[part 1 of 10: packages /Cluster to /E40_Platform_System_SystemPackage/Components]
AUTOSAR XML (schema 4-2-1)
standard types defined: uint8, uint16, UInt16, uint32, UInt32, sint32, boolean, Boolean, SInt32, UInt8, sint8, SInt8, sint16, SInt16
package /Cluster
  can cluster HS3_CAN: baudrate=500000, protocol-name=CAN  # Y2021_FNV2_CMDB_v21.01_HS3_ISOUpdated | FNV2 HS3 CAN
    can physical channel CHNL: comm-connectors=CN_CAN00
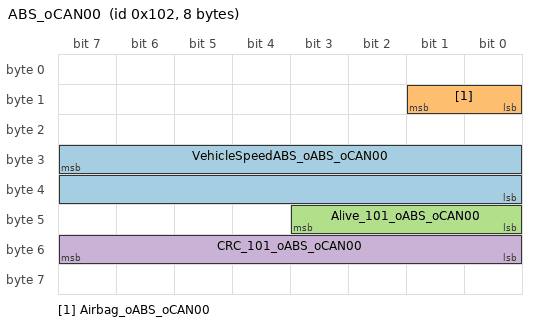
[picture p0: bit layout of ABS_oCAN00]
      frame ABS_oCAN00: id 0x102, to IC, frame-length=8, can-addressing-mode=STANDARD
        pdu ABS_oCAN00: length=8, minimum-delay=0.02, unused-bit-pattern=0
          signal VehicleSpeedABS_oABS_oCAN00: start 31, 16 bit, big-endian, init-value=0, base-type=uint16, compu-method=CM_VehicleSpeedABS, unit=U_SED, transfer-property=PENDING, to IC
          signal Airbag_oABS_oCAN00: start 9, 2 bit, big-endian, init-value=0, base-type=uint8, compu-method=CM_Airbag, unit=U_SED, transfer-property=PENDING, to IC
          signal Alive_101_oABS_oCAN00: start 43, 4 bit, big-endian, init-value=0, base-type=uint8, compu-method=CM_Alive_101, unit=U_SED, transfer-property=PENDING, to IC
          signal CRC_101_oABS_oCAN00: start 55, 8 bit, big-endian, init-value=0, base-type=uint8, compu-method=CM_CRC_101, unit=U_SED, transfer-property=PENDING, to IC
      frame Cluster_Secure_Tx_oCAN00: id 0x300, from IC, frame-length=8, can-addressing-mode=STANDARD
        pdu Cluster_Secure_Tx_oCAN00: length=8, minimum-delay=0.02, unused-bit-pattern=0
          signal SecureTxByte0_oCluster_Secure_Tx_oCAN00: start 0, 8 bit, big-endian, init-value=0, base-type=uint8, compu-method=CM_SecureTxByte0, unit=U_SED, transfer-property=PENDING
          signal SecureTxByte1_oCluster_Secure_Tx_oCAN00: start 8, 8 bit, big-endian, init-value=0, base-type=uint8, compu-method=CM_SecureTxByte1, unit=U_SED, transfer-property=PENDING
          signal SecureTxByte2_oCluster_Secure_Tx_oCAN00: start 16, 8 bit, big-endian, init-value=0, base-type=uint8, compu-method=CM_SecureTxByte2, unit=U_SED, transfer-property=PENDING
          signal SecureTxByte3_oCluster_Secure_Tx_oCAN00: start 24, 8 bit, big-endian, init-value=0, base-type=uint8, compu-method=CM_SecureTxByte3, unit=U_SED, transfer-property=PENDING
          signal MAC_Tx_oCluster_Secure_Tx_oCAN00: start 32, 28 bit, big-endian, init-value=0, base-type=uint32, compu-method=CM_MAC_Tx, unit=U_SED, transfer-property=PENDING
          signal FV_Tx_oCluster_Secure_Tx_oCAN00: start 60, 4 bit, big-endian, init-value=0, base-type=uint8, compu-method=CM_FV_Tx, unit=U_SED, transfer-property=PENDING
      frame Cluster_Tx_Normal_COM_HS_oCAN00: id 0x200, from IC, frame-length=8, can-addressing-mode=STANDARD
        pdu Cluster_Tx_Normal_COM_HS_oCAN00: length=8, minimum-delay=0.02, unused-bit-pattern=0
          signal Battery_Voltage_oCluster_Tx_Normal_COM_HS_oCAN00: start 0, 8 bit, big-endian, init-value=0, base-type=uint8, compu-method=CM_Battery_Voltage, unit=U_SED, transfer-property=PENDING
      frame Cluster_Tx_Normal_COM_LS_oCAN00: id 0x202, from IC, frame-length=8, can-addressing-mode=STANDARD
        pdu Cluster_Tx_Normal_COM_LS_oCAN00: length=8, minimum-delay=0.02, unused-bit-pattern=0
          signal Odometer_oCluster_Tx_Normal_COM_LS_oCAN00: start 0, 32 bit, big-endian, init-value=0, base-type=uint32, compu-method=CM_Odometer, unit=U_SED, transfer-property=PENDING
      frame Cluster_Tx_Normal_COM_MS_oCAN00: id 0x201, from IC, frame-length=8, can-addressing-mode=STANDARD
        pdu Cluster_Tx_Normal_COM_MS_oCAN00: length=8, minimum-delay=0.02, unused-bit-pattern=0
          signal VehicleSpeedIC_oCluster_Tx_Normal_COM_MS_oCAN00: start 0, 16 bit, big-endian, init-value=0, base-type=uint16, compu-method=CM_VehicleSpeedIC, unit=U_SED, transfer-property=PENDING
      frame Cluster_Tx_Reduced_Com_oCAN00: id 0x210, from IC, frame-length=8, can-addressing-mode=STANDARD
        pdu Cluster_Tx_Reduced_Com_oCAN00: length=8, minimum-delay=0.02, unused-bit-pattern=0
          signal Illumination_PWM_oCluster_Tx_Reduced_Com_oCAN00: start 0, 8 bit, big-endian, init-value=0, base-type=uint8, compu-method=CM_Illumination_PWM, unit=U_SED, transfer-property=PENDING
      frame Debug_Frame1_oCAN00: id 0x550, from IC, frame-length=8, can-addressing-mode=STANDARD
        pdu Debug_Frame1_oCAN00: length=8, minimum-delay=0.02, unused-bit-pattern=0
          signal Debug1_Byte0_oDebug_Frame1_oCAN00: start 0, 8 bit, big-endian, init-value=0, base-type=uint8, compu-method=CM_Debug1_Byte0, unit=U_SED, transfer-property=PENDING
          signal Debug1_Byte1_oDebug_Frame1_oCAN00: start 8, 8 bit, big-endian, init-value=0, base-type=uint8, compu-method=CM_Debug1_Byte1, unit=U_SED, transfer-property=PENDING
          signal Debug1_Byte2_oDebug_Frame1_oCAN00: start 16, 8 bit, big-endian, init-value=0, base-type=uint8, compu-method=CM_Debug1_Byte2, unit=U_SED, transfer-property=PENDING
          signal Debug1_Byte3_oDebug_Frame1_oCAN00: start 24, 8 bit, big-endian, init-value=0, base-type=uint8, compu-method=CM_Debug1_Byte3, unit=U_SED, transfer-property=PENDING
          signal Debug1_Byte4_oDebug_Frame1_oCAN00: start 32, 8 bit, big-endian, init-value=0, base-type=uint8, compu-method=CM_Debug1_Byte4, unit=U_SED, transfer-property=PENDING
          signal Debug1_Byte5_oDebug_Frame1_oCAN00: start 40, 8 bit, big-endian, init-value=0, base-type=uint8, compu-method=CM_Debug1_Byte5, unit=U_SED, transfer-property=PENDING
          signal Debug1_Byte6_oDebug_Frame1_oCAN00: start 48, 8 bit, big-endian, init-value=0, base-type=uint8, compu-method=CM_Debug1_Byte6, unit=U_SED, transfer-property=PENDING
          signal Debug1_Byte7_oDebug_Frame1_oCAN00: start 56, 8 bit, big-endian, init-value=0, base-type=uint8, compu-method=CM_Debug1_Byte7, unit=U_SED, transfer-property=PENDING
      frame Debug_Frame2_oCAN00: id 0x551, from IC, frame-length=8, can-addressing-mode=STANDARD
        pdu Debug_Frame2_oCAN00: length=8, minimum-delay=0.02, unused-bit-pattern=0
          signal Debug2_Byte0_oDebug_Frame2_oCAN00: start 0, 8 bit, big-endian, init-value=0, base-type=uint8, compu-method=CM_Debug2_Byte0, unit=U_SED, transfer-property=PENDING
          signal Debug2_Byte1_oDebug_Frame2_oCAN00: start 8, 8 bit, big-endian, init-value=0, base-type=uint8, compu-method=CM_Debug2_Byte1, unit=U_SED, transfer-property=PENDING
          signal Debug2_Byte2_oDebug_Frame2_oCAN00: start 16, 8 bit, big-endian, init-value=0, base-type=uint8, compu-method=CM_Debug2_Byte2, unit=U_SED, transfer-property=PENDING
          signal Debug2_Byte3_oDebug_Frame2_oCAN00: start 24, 8 bit, big-endian, init-value=0, base-type=uint8, compu-method=CM_Debug2_Byte3, unit=U_SED, transfer-property=PENDING
          signal Debug2_Byte4_oDebug_Frame2_oCAN00: start 32, 8 bit, big-endian, init-value=0, base-type=uint8, compu-method=CM_Debug2_Byte4, unit=U_SED, transfer-property=PENDING
          signal Debug2_Byte5_oDebug_Frame2_oCAN00: start 40, 8 bit, big-endian, init-value=0, base-type=uint8, compu-method=CM_Debug2_Byte5, unit=U_SED, transfer-property=PENDING
          signal Debug2_Byte6_oDebug_Frame2_oCAN00: start 48, 8 bit, big-endian, init-value=0, base-type=uint8, compu-method=CM_Debug2_Byte6, unit=U_SED, transfer-property=PENDING
          signal Debug2_Byte7_oDebug_Frame2_oCAN00: start 56, 8 bit, big-endian, init-value=0, base-type=uint8, compu-method=CM_Debug2_Byte7, unit=U_SED, transfer-property=PENDING
      frame Debug_Frame3_oCAN00: id 0x552, from IC, frame-length=8, can-addressing-mode=STANDARD
        pdu Debug_Frame3_oCAN00: length=8, minimum-delay=0.02, unused-bit-pattern=0
          signal Debug3_Byte0_oDebug_Frame3_oCAN00: start 0, 8 bit, big-endian, init-value=0, base-type=uint8, compu-method=CM_Debug3_Byte0, unit=U_SED, transfer-property=PENDING
          signal Debug3_Byte1_oDebug_Frame3_oCAN00: start 8, 8 bit, big-endian, init-value=0, base-type=uint8, compu-method=CM_Debug3_Byte1, unit=U_SED, transfer-property=PENDING
          signal Debug3_Byte2_oDebug_Frame3_oCAN00: start 16, 8 bit, big-endian, init-value=0, base-type=uint8, compu-method=CM_Debug3_Byte2, unit=U_SED, transfer-property=PENDING
          signal Debug3_Byte3_oDebug_Frame3_oCAN00: start 24, 8 bit, big-endian, init-value=0, base-type=uint8, compu-method=CM_Debug3_Byte3, unit=U_SED, transfer-property=PENDING
          signal Debug3_Byte4_oDebug_Frame3_oCAN00: start 32, 8 bit, big-endian, init-value=0, base-type=uint8, compu-method=CM_Debug3_Byte4, unit=U_SED, transfer-property=PENDING
          signal Debug3_Byte5_oDebug_Frame3_oCAN00: start 40, 8 bit, big-endian, init-value=0, base-type=uint8, compu-method=CM_Debug3_Byte5, unit=U_SED, transfer-property=PENDING
          signal Debug3_Byte6_oDebug_Frame3_oCAN00: start 48, 8 bit, big-endian, init-value=0, base-type=uint8, compu-method=CM_Debug3_Byte6, unit=U_SED, transfer-property=PENDING
          signal Debug3_Byte7_oDebug_Frame3_oCAN00: start 56, 8 bit, big-endian, init-value=0, base-type=uint8, compu-method=CM_Debug3_Byte7, unit=U_SED, transfer-property=PENDING
      frame Debug_Frame4_oCAN00: id 0x553, from IC, frame-length=8, can-addressing-mode=STANDARD
        pdu Debug_Frame4_oCAN00: length=8, minimum-delay=0.02, unused-bit-pattern=0
          signal Debug4_Byte0_oDebug_Frame4_oCAN00: start 0, 8 bit, big-endian, init-value=0, base-type=uint8, compu-method=CM_Debug4_Byte0, unit=U_SED, transfer-property=PENDING
          signal Debug4_Byte1_oDebug_Frame4_oCAN00: start 8, 8 bit, big-endian, init-value=0, base-type=uint8, compu-method=CM_Debug4_Byte1, unit=U_SED, transfer-property=PENDING
          signal Debug4_Byte2_oDebug_Frame4_oCAN00: start 16, 8 bit, big-endian, init-value=0, base-type=uint8, compu-method=CM_Debug4_Byte2, unit=U_SED, transfer-property=PENDING
          signal Debug4_Byte3_oDebug_Frame4_oCAN00: start 24, 8 bit, big-endian, init-value=0, base-type=uint8, compu-method=CM_Debug4_Byte3, unit=U_SED, transfer-property=PENDING
          signal Debug4_Byte4_oDebug_Frame4_oCAN00: start 32, 8 bit, big-endian, init-value=0, base-type=uint8, compu-method=CM_Debug4_Byte4, unit=U_SED, transfer-property=PENDING
          signal Debug4_Byte5_oDebug_Frame4_oCAN00: start 40, 8 bit, big-endian, init-value=0, base-type=uint8, compu-method=CM_Debug4_Byte5, unit=U_SED, transfer-property=PENDING
          signal Debug4_Byte6_oDebug_Frame4_oCAN00: start 48, 8 bit, big-endian, init-value=0, base-type=uint8, compu-method=CM_Debug4_Byte6, unit=U_SED, transfer-property=PENDING
          signal Debug4_Byte7_oDebug_Frame4_oCAN00: start 56, 8 bit, big-endian, init-value=0, base-type=uint8, compu-method=CM_Debug4_Byte7, unit=U_SED, transfer-property=PENDING
      frame Debug_Frame5_oCAN00: id 0x554, from IC, frame-length=8, can-addressing-mode=STANDARD
        pdu Debug_Frame5_oCAN00: length=8, minimum-delay=0.02, unused-bit-pattern=0
          signal Debug5_Byte0_oDebug_Frame5_oCAN00: start 0, 8 bit, big-endian, init-value=0, base-type=uint8, compu-method=CM_Debug5_Byte0, unit=U_SED, transfer-property=PENDING
          signal Debug5_Byte1_oDebug_Frame5_oCAN00: start 8, 8 bit, big-endian, init-value=0, base-type=uint8, compu-method=CM_Debug5_Byte1, unit=U_SED, transfer-property=PENDING
          signal Debug5_Byte2_oDebug_Frame5_oCAN00: start 16, 8 bit, big-endian, init-value=0, base-type=uint8, compu-method=CM_Debug5_Byte2, unit=U_SED, transfer-property=PENDING
          signal Debug5_Byte3_oDebug_Frame5_oCAN00: start 24, 8 bit, big-endian, init-value=0, base-type=uint8, compu-method=CM_Debug5_Byte3, unit=U_SED, transfer-property=PENDING
          signal Debug5_Byte4_oDebug_Frame5_oCAN00: start 32, 8 bit, big-endian, init-value=0, base-type=uint8, compu-method=CM_Debug5_Byte4, unit=U_SED, transfer-property=PENDING
          signal Debug5_Byte5_oDebug_Frame5_oCAN00: start 40, 8 bit, big-endian, init-value=0, base-type=uint8, compu-method=CM_Debug5_Byte5, unit=U_SED, transfer-property=PENDING
          signal Debug5_Byte6_oDebug_Frame5_oCAN00: start 48, 8 bit, big-endian, init-value=0, base-type=uint8, compu-method=CM_Debug5_Byte6, unit=U_SED, transfer-property=PENDING
          signal Debug5_Byte7_oDebug_Frame5_oCAN00: start 56, 8 bit, big-endian, init-value=0, base-type=uint8, compu-method=CM_Debug5_Byte7, unit=U_SED, transfer-property=PENDING
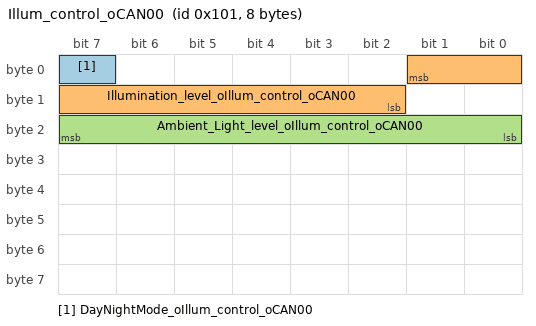
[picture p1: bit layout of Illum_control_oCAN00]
      frame Illum_control_oCAN00: id 0x101, to IC, frame-length=8, can-addressing-mode=STANDARD
        pdu Illum_control_oCAN00: length=8, minimum-delay=0.02, unused-bit-pattern=0
          signal DayNightMode_oIllum_control_oCAN00: start 7, 1 bit, big-endian, init-value=0, base-type=boolean, compu-method=CM_DayNightMode, unit=U_SED, transfer-property=PENDING, to IC
          signal Illumination_level_oIllum_control_oCAN00: start 1, 8 bit, big-endian, init-value=0, base-type=uint8, compu-method=CM_Illumination_level, unit=U_SED, transfer-property=PENDING, to IC
          signal Ambient_Light_level_oIllum_control_oCAN00: start 23, 8 bit, big-endian, init-value=0, base-type=uint8, compu-method=CM_Ambient_Light_level, unit=U_SED, transfer-property=PENDING, to IC
      frame VehicleControl_oCAN00: id 0x100, to IC, frame-length=8, can-addressing-mode=STANDARD
        pdu VehicleControl_oCAN00: length=8, minimum-delay=0.02, unused-bit-pattern=0
          signal PowerMode_oVehicleControl_oCAN00: start 0, 4 bit, big-endian, init-value=0, base-type=uint8, compu-method=CM_PowerMode, unit=U_SED, transfer-property=PENDING, to IC
          signal TransportMode_oVehicleControl_oCAN00: start 54, 1 bit, big-endian, init-value=0, base-type=boolean, compu-method=CM_TransportMode, unit=U_SED, transfer-property=PENDING, to IC
          signal GearMode_oVehicleControl_oCAN00: start 51, 1 bit, big-endian, init-value=0, base-type=boolean, compu-method=CM_GearMode, unit=U_SED, transfer-property=PENDING, to IC
          signal GearRecommendation_oVehicleControl_oCAN00: start 50, 3 bit, big-endian, init-value=0, base-type=uint8, compu-method=CM_GearRecommendation, unit=U_SED, transfer-property=PENDING, to IC
          signal Gear_oVehicleControl_oCAN00: start 7, 4 bit, big-endian, init-value=0, base-type=uint8, compu-method=CM_Gear, unit=U_SED, transfer-property=PENDING, to IC
          signal Warning_oVehicleControl_oCAN00: start 63, 8 bit, big-endian, init-value=0, base-type=uint8, compu-method=CM_Warning, unit=U_SED, transfer-property=PENDING, to IC
          signal GearStatus_oVehicleControl_oCAN00: start 15, 8 bit, big-endian, init-value=0, base-type=uint8, compu-method=CM_GearStatus, unit=U_SED, transfer-property=PENDING, to IC
          signal EngineSpeed_oVehicleControl_oCAN00: start 39, 16 bit, big-endian, init-value=0, base-type=uint16, compu-method=CM_EngineSpeed, unit=U_SED, transfer-property=PENDING, to IC
package /ECU
  ecu instance IC: associated-com-i-pdu-group=[IC_oCAN00_Rx, IC_oCAN00_Tx]  # Instrument Panel Cluster Control Module, IC (Instrument Cluster)
    can communication controller CT_CAN00
    can communication connector CN_CAN00: comm-controller=CT_CAN00
package /IPDUGroup
  i signal i pdu group IC_oCAN00_Rx: communication-direction=IN, i-signal-i-pdus=[ABS_oCAN00, Illum_control_oCAN00, VehicleControl_oCAN00]
  i signal i pdu group IC_oCAN00_Tx: communication-direction=OUT
    i-signal-i-pdus:
      Cluster_Secure_Tx_oCAN00
      Cluster_Tx_Normal_COM_HS_oCAN00
      Cluster_Tx_Normal_COM_LS_oCAN00
      Cluster_Tx_Normal_COM_MS_oCAN00
      Cluster_Tx_Reduced_Com_oCAN00
      Debug_Frame{1..5}_oCAN00
package /E40_Platform_System_SystemPackage
  composition sw component type E40_Platform_System_SoftwareArchitecture
    component E40_Platform_SystemCmp: type=E40_Platform_System
  system E40_Platform_System_System
    system mapping MAPPING
      data-mappings:
        data-element=CComAbsMdl.SoftwareArchitecture.pp_SR_TxSecureTxByte{0..3}.SecureTxByte{0..3}, system-signal=SecureTxByte{0..3}
        data-element=CComAbsMdl.SoftwareArchitecture.pp_SR_TxMAC_Tx.MAC_Tx, system-signal=MAC_Tx
        data-element=CComAbsMdl.SoftwareArchitecture.pp_SR_TxFV_Tx.FV_Tx, system-signal=FV_Tx
        data-element=CComAbsMdl.SoftwareArchitecture.pp_SR_TxBattery_Voltage.Battery_Voltage, system-signal=Battery_Voltage
        data-element=CComAbsMdl.SoftwareArchitecture.pp_SR_TxOdometer.Odometer, system-signal=Odometer
        data-element=CComAbsMdl.SoftwareArchitecture.pp_SR_TxVehicleSpeedIC.VehicleSpeedIC, system-signal=VehicleSpeedIC
        data-element=CComAbsMdl.SoftwareArchitecture.pp_SR_TxIllumination_PWM.Illumination_PWM, system-signal=Illumination_PWM
        data-element=CComAbsMdl.SoftwareArchitecture.pp_SR_TxDebug1_Byte{0..7}.Debug1_Byte{0..7}, system-signal=Debug1_Byte{0..7}
        data-element=CComAbsMdl.SoftwareArchitecture.pp_SR_TxDebug2_Byte{0..7}.Debug2_Byte{0..7}, system-signal=Debug2_Byte{0..7}
        data-element=CComAbsMdl.SoftwareArchitecture.pp_SR_TxDebug3_Byte{0..7}.Debug3_Byte{0..7}, system-signal=Debug3_Byte{0..7}
        data-element=CComAbsMdl.SoftwareArchitecture.pp_SR_TxDebug4_Byte{0..7}.Debug4_Byte{0..7}, system-signal=Debug4_Byte{0..7}
        data-element=CComAbsMdl.SoftwareArchitecture.pp_SR_TxDebug5_Byte{0..7}.Debug5_Byte{0..7}, system-signal=Debug5_Byte{0..7}
        data-element=CComAbsMdl.SoftwareArchitecture.rp_SR_RxDayNightMode.DayNightMode, system-signal=DayNightMode
        data-element=CComAbsMdl.SoftwareArchitecture.rp_SR_RxIllumination_level.Illumination_level, system-signal=Illumination_level
        data-element=CComAbsMdl.SoftwareArchitecture.rp_SR_RxAmbient_Light_level.Ambient_Light_level, system-signal=Ambient_Light_level
        data-element=CComAbsMdl.SoftwareArchitecture.rp_SR_RxPowerMode.PowerMode, system-signal=PowerMode
        data-element=CComAbsMdl.SoftwareArchitecture.rp_SR_RxTransportMode.TransportMode, system-signal=TransportMode
        data-element=CComAbsMdl.SoftwareArchitecture.rp_SR_RxGearMode.GearMode, system-signal=GearMode
        data-element=CComAbsMdl.SoftwareArchitecture.rp_SR_RxGearRecommendation.GearRecommendation, system-signal=GearRecommendation
        data-element=CComAbsMdl.SoftwareArchitecture.rp_SR_RxGear.Gear, system-signal=Gear
        data-element=CComAbsMdl.SoftwareArchitecture.rp_SR_RxWarning.Warning, system-signal=Warning
        data-element=CComAbsMdl.SoftwareArchitecture.rp_SR_RxGearStatus.GearStatus, system-signal=GearStatus
        data-element=CComAbsMdl.SoftwareArchitecture.rp_SR_RxEngineSpeed.EngineSpeed, system-signal=EngineSpeed
        data-element=CComAbsMdl.SoftwareArchitecture.rp_SR_RxVehicleSpeedABS.VehicleSpeedABS, system-signal=VehicleSpeedABS
        data-element=CComAbsMdl.SoftwareArchitecture.rp_SR_RxAirbag.Airbag, system-signal=Airbag
        data-element=CComAbsMdl.SoftwareArchitecture.rp_SR_RxAlive_101.Alive_101, system-signal=Alive_101
        data-element=CComAbsMdl.SoftwareArchitecture.rp_SR_RxCRC_101.CRC_101, system-signal=CRC_101
      sw-impl-mappings:
        58 x swc to impl mapping:
          ImplementationMapping1: component-implementation=IMPL_CBacklightCdd, component=SoftwareArchitecture.E40_Platform_SystemCmp.CBacklightCdd
          ImplementationMapping2: component-implementation=IMPL_IoHwAb, component=SoftwareArchitecture.E40_Platform_SystemCmp.IoHwAb
          ImplementationMapping3: component-implementation=IMPL_CBattMdl, component=SoftwareArchitecture.E40_Platform_SystemCmp.CBattMdl
          ImplementationMapping4: component-implementation=IMPL_CCDD_EcuPowerM, component=SoftwareArchitecture.E40_Platform_SystemCmp.CCDD_EcuPowerM
          ImplementationMapping5: component-implementation=IMPL_CComAbsCtrl, component=SoftwareArchitecture.E40_Platform_SystemCmp.CComAbsCtrl
          ImplementationMapping6: component-implementation=IMPL_ComMExt, component=SoftwareArchitecture.E40_Platform_SystemCmp.ComMExt
          ImplementationMapping7: component-implementation=IMPL_CComAbsMdl, component=SoftwareArchitecture.E40_Platform_SystemCmp.CComAbsMdl
          ImplementationMapping8: component-implementation=IMPL_CCtrl_Telltale, component=SoftwareArchitecture.E40_Platform_SystemCmp.CCtrl_Telltale
          ImplementationMapping9: component-implementation=IMPL_Ctrl_WSS, component=SoftwareArchitecture.E40_Platform_SystemCmp.Ctrl_WSS
          ImplementationMapping10: component-implementation=IMPL_NvMExt, component=SoftwareArchitecture.E40_Platform_SystemCmp.NvMExt
          ImplementationMapping11: component-implementation=IMPL_TmExt, component=SoftwareArchitecture.E40_Platform_SystemCmp.TmExt
          ImplementationMapping12: component-implementation=IMPL_Mdl_Dim, component=SoftwareArchitecture.E40_Platform_SystemCmp.Mdl_Dim
          ImplementationMapping13: component-implementation=IMPL_Ctrl_Dim, component=SoftwareArchitecture.E40_Platform_SystemCmp.Ctrl_Dim
          ImplementationMapping14: component-implementation=IMPL_MemAbstractMdl, component=SoftwareArchitecture.E40_Platform_SystemCmp.MemAbstractMdl
          ImplementationMapping15: component-implementation=IMPL_Ctrl_warning, component=SoftwareArchitecture.E40_Platform_SystemCmp.Ctrl_warning
          ImplementationMapping16: component-implementation=IMPL_CWarnMsg_Core_Observer, component=SoftwareArchitecture.E40_Platform_SystemCmp.CWarnMsg_Core_Observer
          ImplementationMapping17: component-implementation=IMPL_UclProxyCdd, component=SoftwareArchitecture.E40_Platform_SystemCmp.UclProxyCdd
          ImplementationMapping18: component-implementation=IMPL_DmnMgr, component=SoftwareArchitecture.E40_Platform_SystemCmp.DmnMgr
          ImplementationMapping19: component-implementation=IMPL_CSleepManager, component=SoftwareArchitecture.E40_Platform_SystemCmp.CSleepManager
          ImplementationMapping20: component-implementation=IMPL_Mdl_Gear, component=SoftwareArchitecture.E40_Platform_SystemCmp.Mdl_Gear
          ImplementationMapping21: component-implementation=IMPL_CView_Telltale, component=SoftwareArchitecture.E40_Platform_SystemCmp.CView_Telltale
          ImplementationMapping22: component-implementation=IMPL_Mdl_Airbag, component=SoftwareArchitecture.E40_Platform_SystemCmp.Mdl_Airbag
          ImplementationMapping23: component-implementation=IMPL_Mdl_SafetyAdapter, component=SoftwareArchitecture.E40_Platform_SystemCmp.Mdl_SafetyAdapter
          ImplementationMapping24: component-implementation=IMPL_Mdl_TurnHazard, component=SoftwareArchitecture.E40_Platform_SystemCmp.Mdl_TurnHazard
          ImplementationMapping25: component-implementation=IMPL_FastGaugeAdapter, component=SoftwareArchitecture.E40_Platform_SystemCmp.FastGaugeAdapter
          ImplementationMapping26: component-implementation=IMPL_View_Speed, component=SoftwareArchitecture.E40_Platform_SystemCmp.View_Speed
          ImplementationMapping27: component-implementation=IMPL_Mdl_Speed, component=SoftwareArchitecture.E40_Platform_SystemCmp.Mdl_Speed
          ImplementationMapping28: component-implementation=IMPL_Mdl_Linear_Interpolation, component=SoftwareArchitecture.E40_Platform_SystemCmp.Mdl_Linear_Interpolation
          ImplementationMapping29: component-implementation=IMPL_Mdl_Tacho, component=SoftwareArchitecture.E40_Platform_SystemCmp.Mdl_Tacho
          ImplementationMapping30: component-implementation=IMPL_SlowGaugeAdapter, component=SoftwareArchitecture.E40_Platform_SystemCmp.SlowGaugeAdapter
          ImplementationMapping31: component-implementation=IMPL_CUpdateCdd, component=SoftwareArchitecture.E40_Platform_SystemCmp.CUpdateCdd
          ImplementationMapping32: component-implementation=IMPL_Mdl_wAirbag, component=SoftwareArchitecture.E40_Platform_SystemCmp.Mdl_wAirbag
          ImplementationMapping33: component-implementation=IMPL_Mdl_wFuelLidOpen, component=SoftwareArchitecture.E40_Platform_SystemCmp.Mdl_wFuelLidOpen
          ImplementationMapping34: component-implementation=IMPL_WarnMsg_Core_TmrSupport, component=SoftwareArchitecture.E40_Platform_SystemCmp.WarnMsg_Core_TmrSupport
          ImplementationMapping35: component-implementation=IMPL_DcmApp, component=SoftwareArchitecture.E40_Platform_SystemCmp.DcmApp
          ImplementationMapping36: component-implementation=IMPL_DemApp, component=SoftwareArchitecture.E40_Platform_SystemCmp.DemApp
          ImplementationMapping37: component-implementation=IMPL_DemExt, component=SoftwareArchitecture.E40_Platform_SystemCmp.DemExt
          ImplementationMapping38: component-implementation=IMPL_CDisplayCdd, component=SoftwareArchitecture.E40_Platform_SystemCmp.CDisplayCdd
          ImplementationMapping39: component-implementation=IMPL_CFltM, component=SoftwareArchitecture.E40_Platform_SystemCmp.CFltM
          ImplementationMapping40: component-implementation=IMPL_RstM, component=SoftwareArchitecture.E40_Platform_SystemCmp.RstM
          ImplementationMapping41: component-implementation=IMPL_Dlt, component=SoftwareArchitecture.E40_Platform_SystemCmp.Dlt
          ImplementationMapping42: component-implementation=IMPL_EcuMExt, component=SoftwareArchitecture.E40_Platform_SystemCmp.EcuMExt
          ImplementationMapping43: component-implementation=IMPL_EcuAppM, component=SoftwareArchitecture.E40_Platform_SystemCmp.EcuAppM
          ImplementationMapping44: component-implementation=IMPL_CFltMExt, component=SoftwareArchitecture.E40_Platform_SystemCmp.CFltMExt
          ImplementationMapping45: component-implementation=IMPL_GdtCdd, component=SoftwareArchitecture.E40_Platform_SystemCmp.GdtCdd
          ImplementationMapping46: component-implementation=IMPL_CIoExp, component=SoftwareArchitecture.E40_Platform_SystemCmp.CIoExp
          ImplementationMapping47: component-implementation=IMPL_CPmicCdd, component=SoftwareArchitecture.E40_Platform_SystemCmp.CPmicCdd
          ImplementationMapping48: component-implementation=IMPL_RtcCdd, component=SoftwareArchitecture.E40_Platform_SystemCmp.RtcCdd
          ImplementationMapping49: component-implementation=IMPL_SafeNvM, component=SoftwareArchitecture.E40_Platform_SystemCmp.SafeNvM
          ImplementationMapping50: component-implementation=IMPL_CSndCdd, component=SoftwareArchitecture.E40_Platform_SystemCmp.CSndCdd
          ImplementationMapping51: component-implementation=IMPL_CorTst, component=SoftwareArchitecture.E40_Platform_SystemCmp.CorTst
          ImplementationMapping52: component-implementation=IMPL_FlsTst, component=SoftwareArchitecture.E40_Platform_SystemCmp.FlsTst
          ImplementationMapping53: component-implementation=IMPL_CMeetCdd, component=SoftwareArchitecture.E40_Platform_SystemCmp.CMeetCdd
          ImplementationMapping54: component-implementation=IMPL_RamTst, component=SoftwareArchitecture.E40_Platform_SystemCmp.RamTst
          ImplementationMapping55: component-implementation=IMPL_SysTst, component=SoftwareArchitecture.E40_Platform_SystemCmp.SysTst
          ImplementationMapping56: component-implementation=IMPL_DltExt, component=SoftwareArchitecture.E40_Platform_SystemCmp.DltExt
          ImplementationMapping57: component-implementation=IMPL_ComCallout, component=SoftwareArchitecture.E40_Platform_SystemCmp.ComCallout
          ImplementationMapping58: component-implementation=IMPL_DcmExt, component=SoftwareArchitecture.E40_Platform_SystemCmp.DcmExt
      sw-mappings:
        swc to ecu mapping SwcToEcuMapping: ecu-instance=IC
    root-software-compositions:
      root sw composition prototype SoftwareArchitecture: software-composition=E40_Platform_System
package /E40_Platform_System_SystemPackage/Components
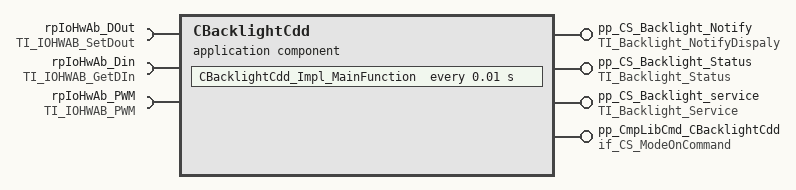
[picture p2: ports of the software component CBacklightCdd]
  application sw component type CBacklightCdd
    4 x provide port:
      pp_CS_Backlight_Notify: server-com-spec{operation=NotifyDisplayPowerState, queue-length=1}, provided-interface=TI_Backlight_NotifyDispaly
      pp_CS_Backlight_Status: server-com-spec{operation=TI_Backlight_Status/GetStatus, queue-length=1}, provided-interface=TI_Backlight_Status
      pp_CS_Backlight_service: provided-interface=TI_Backlight_Service
        provided-com-specs:
          operation=GetBrightnessValue, queue-length=1
          operation=GetThermalValue, queue-length=1
          operation=SetBrightnessValue, queue-length=1
      pp_CmpLibCmd_CBacklightCdd: server-com-spec{operation=Impl_OnCommand, queue-length=1}, provided-interface=if_CS_ModeOnCommand
    require port rpIoHwAb_DOut: required-interface=TI_IOHWAB_SetDout
    require port rpIoHwAb_Din: required-interface=TI_IOHWAB_GetDIn
    require port rpIoHwAb_PWM: required-interface=TI_IOHWAB_PWM
    behavior IB_CBacklightCdd
      operation invoked event OIE_pp_CS_Backlight_service_CBacklightCdd_GetBrightnessValueTrigByGetBrightnessValue: start-on-event=CBacklightCdd_GetBrightnessValue, operation=pp_CS_Backlight_service.GetBrightnessValue
      operation invoked event OIE_pp_CS_Backlight_Status_CBacklightCdd_GetStatusTrigByGetStatus: start-on-event=CBacklightCdd_GetStatus, operation=pp_CS_Backlight_Status.GetStatus
      operation invoked event OIE_pp_CS_Backlight_service_CBacklightCdd_GetThermalValueTrigByGetThermalValue: start-on-event=CBacklightCdd_GetThermalValue, operation=pp_CS_Backlight_service.GetThermalValue
      timing event TECBacklightCdd_Impl_MainFunction: start-on-event=CBacklightCdd_Impl_MainFunction, period=0.01
      operation invoked event OIE_pp_CmpLibCmd_CBacklightCdd_CBacklightCdd_Impl_OnCommandTrigByImpl_OnCommand: start-on-event=CBacklightCdd_Impl_OnCommand, operation=pp_CmpLibCmd_CBacklightCdd.Impl_OnCommand
      operation invoked event OIE_pp_CS_Backlight_Notify_CBacklightCdd_NotifyDisplayPowerStateTrigByNotifyDisplayPowerState: start-on-event=CBacklightCdd_NotifyDisplayPowerState, operation=pp_CS_Backlight_Notify.NotifyDisplayPowerState
      operation invoked event OIE_pp_CS_Backlight_service_CBacklightCdd_SetBrightnessValueTrigBySetBrightnessValue: start-on-event=CBacklightCdd_SetBrightnessValue, operation=pp_CS_Backlight_service.SetBrightnessValue
      port-api-options:
        enable-take-address=false, indirect-api=false, port=pp_CS_Backlight_Notify
        enable-take-address=false, indirect-api=false, port=pp_CS_Backlight_Status
        enable-take-address=false, indirect-api=false, port=pp_CS_Backlight_service
        enable-take-address=false, indirect-api=false, port=pp_CmpLibCmd_CBacklightCdd
        enable-take-address=false, indirect-api=false, port=CBacklightCdd/rpIoHwAb_DOut
        enable-take-address=false, indirect-api=false, port=CBacklightCdd/rpIoHwAb_Din
        enable-take-address=false, indirect-api=false, port=CBacklightCdd/rpIoHwAb_PWM
      7 x runnable, all with can-be-invoked-concurrently=true:
        CBacklightCdd_GetBrightnessValue
          9 x sync call, all with timeout=0.0:
            OA_rpIoHwAb_DOut_SetOutputGroup: operation=rpIoHwAb_DOut.SetOutputGroup
            OA_rpIoHwAb_DOut_SetOutputPin: operation=rpIoHwAb_DOut.SetOutputPin
            OA_rpIoHwAb_Din_GetAsyncRawInput: operation=rpIoHwAb_Din.GetAsyncRawInput
            OA_rpIoHwAb_Din_GetProcessedInput: operation=rpIoHwAb_Din.GetProcessedInput
            OA_rpIoHwAb_Din_GetSyncRawInput: operation=rpIoHwAb_Din.GetSyncRawInput
            OA_rpIoHwAb_Din_GetInputGroup: operation=rpIoHwAb_Din.GetInputGroup
            OA_rpIoHwAb_PWM_PwmSetDuty: operation=rpIoHwAb_PWM.PwmSetDuty
            OA_rpIoHwAb_PWM_PwmSetDutyAndPeriod: operation=rpIoHwAb_PWM.PwmSetDutyAndPeriod
            OA_rpIoHwAb_PWM_PwmSetIdeal: operation=rpIoHwAb_PWM.PwmSetIdeal
        CBacklightCdd_GetStatus
          9 x sync call, all with timeout=0.0:
            OA_rpIoHwAb_DOut_SetOutputGroup: operation=rpIoHwAb_DOut.SetOutputGroup
            OA_rpIoHwAb_DOut_SetOutputPin: operation=rpIoHwAb_DOut.SetOutputPin
            OA_rpIoHwAb_Din_GetAsyncRawInput: operation=rpIoHwAb_Din.GetAsyncRawInput
            OA_rpIoHwAb_Din_GetProcessedInput: operation=rpIoHwAb_Din.GetProcessedInput
            OA_rpIoHwAb_Din_GetSyncRawInput: operation=rpIoHwAb_Din.GetSyncRawInput
            OA_rpIoHwAb_Din_GetInputGroup: operation=rpIoHwAb_Din.GetInputGroup
            OA_rpIoHwAb_PWM_PwmSetDuty: operation=rpIoHwAb_PWM.PwmSetDuty
            OA_rpIoHwAb_PWM_PwmSetDutyAndPeriod: operation=rpIoHwAb_PWM.PwmSetDutyAndPeriod
            OA_rpIoHwAb_PWM_PwmSetIdeal: operation=rpIoHwAb_PWM.PwmSetIdeal
        CBacklightCdd_GetThermalValue
          9 x sync call, all with timeout=0.0:
            OA_rpIoHwAb_DOut_SetOutputGroup: operation=rpIoHwAb_DOut.SetOutputGroup
            OA_rpIoHwAb_DOut_SetOutputPin: operation=rpIoHwAb_DOut.SetOutputPin
            OA_rpIoHwAb_Din_GetAsyncRawInput: operation=rpIoHwAb_Din.GetAsyncRawInput
            OA_rpIoHwAb_Din_GetProcessedInput: operation=rpIoHwAb_Din.GetProcessedInput
            OA_rpIoHwAb_Din_GetSyncRawInput: operation=rpIoHwAb_Din.GetSyncRawInput
            OA_rpIoHwAb_Din_GetInputGroup: operation=rpIoHwAb_Din.GetInputGroup
            OA_rpIoHwAb_PWM_PwmSetDuty: operation=rpIoHwAb_PWM.PwmSetDuty
            OA_rpIoHwAb_PWM_PwmSetDutyAndPeriod: operation=rpIoHwAb_PWM.PwmSetDutyAndPeriod
            OA_rpIoHwAb_PWM_PwmSetIdeal: operation=rpIoHwAb_PWM.PwmSetIdeal
        CBacklightCdd_Impl_MainFunction
          9 x sync call, all with timeout=0.0:
            OA_rpIoHwAb_DOut_SetOutputGroup: operation=rpIoHwAb_DOut.SetOutputGroup
            OA_rpIoHwAb_DOut_SetOutputPin: operation=rpIoHwAb_DOut.SetOutputPin
            OA_rpIoHwAb_Din_GetAsyncRawInput: operation=rpIoHwAb_Din.GetAsyncRawInput
            OA_rpIoHwAb_Din_GetProcessedInput: operation=rpIoHwAb_Din.GetProcessedInput
            OA_rpIoHwAb_Din_GetSyncRawInput: operation=rpIoHwAb_Din.GetSyncRawInput
            OA_rpIoHwAb_Din_GetInputGroup: operation=rpIoHwAb_Din.GetInputGroup
            OA_rpIoHwAb_PWM_PwmSetDuty: operation=rpIoHwAb_PWM.PwmSetDuty
            OA_rpIoHwAb_PWM_PwmSetDutyAndPeriod: operation=rpIoHwAb_PWM.PwmSetDutyAndPeriod
            OA_rpIoHwAb_PWM_PwmSetIdeal: operation=rpIoHwAb_PWM.PwmSetIdeal
        CBacklightCdd_Impl_OnCommand
          9 x sync call, all with timeout=0.0:
            OA_rpIoHwAb_DOut_SetOutputGroup: operation=rpIoHwAb_DOut.SetOutputGroup
            OA_rpIoHwAb_DOut_SetOutputPin: operation=rpIoHwAb_DOut.SetOutputPin
            OA_rpIoHwAb_Din_GetAsyncRawInput: operation=rpIoHwAb_Din.GetAsyncRawInput
            OA_rpIoHwAb_Din_GetProcessedInput: operation=rpIoHwAb_Din.GetProcessedInput
            OA_rpIoHwAb_Din_GetSyncRawInput: operation=rpIoHwAb_Din.GetSyncRawInput
            OA_rpIoHwAb_Din_GetInputGroup: operation=rpIoHwAb_Din.GetInputGroup
            OA_rpIoHwAb_PWM_PwmSetDuty: operation=rpIoHwAb_PWM.PwmSetDuty
            OA_rpIoHwAb_PWM_PwmSetDutyAndPeriod: operation=rpIoHwAb_PWM.PwmSetDutyAndPeriod
            OA_rpIoHwAb_PWM_PwmSetIdeal: operation=rpIoHwAb_PWM.PwmSetIdeal
        CBacklightCdd_NotifyDisplayPowerState
          9 x sync call, all with timeout=0.0:
            OA_rpIoHwAb_DOut_SetOutputGroup: operation=rpIoHwAb_DOut.SetOutputGroup
            OA_rpIoHwAb_DOut_SetOutputPin: operation=rpIoHwAb_DOut.SetOutputPin
            OA_rpIoHwAb_Din_GetAsyncRawInput: operation=rpIoHwAb_Din.GetAsyncRawInput
            OA_rpIoHwAb_Din_GetProcessedInput: operation=rpIoHwAb_Din.GetProcessedInput
            OA_rpIoHwAb_Din_GetSyncRawInput: operation=rpIoHwAb_Din.GetSyncRawInput
            OA_rpIoHwAb_Din_GetInputGroup: operation=rpIoHwAb_Din.GetInputGroup
            OA_rpIoHwAb_PWM_PwmSetDuty: operation=rpIoHwAb_PWM.PwmSetDuty
            OA_rpIoHwAb_PWM_PwmSetDutyAndPeriod: operation=rpIoHwAb_PWM.PwmSetDutyAndPeriod
            OA_rpIoHwAb_PWM_PwmSetIdeal: operation=rpIoHwAb_PWM.PwmSetIdeal
        CBacklightCdd_SetBrightnessValue
          9 x sync call, all with timeout=0.0:
            OA_rpIoHwAb_DOut_SetOutputGroup: operation=rpIoHwAb_DOut.SetOutputGroup
            OA_rpIoHwAb_DOut_SetOutputPin: operation=rpIoHwAb_DOut.SetOutputPin
            OA_rpIoHwAb_Din_GetAsyncRawInput: operation=rpIoHwAb_Din.GetAsyncRawInput
            OA_rpIoHwAb_Din_GetProcessedInput: operation=rpIoHwAb_Din.GetProcessedInput
            OA_rpIoHwAb_Din_GetSyncRawInput: operation=rpIoHwAb_Din.GetSyncRawInput
            OA_rpIoHwAb_Din_GetInputGroup: operation=rpIoHwAb_Din.GetInputGroup
            OA_rpIoHwAb_PWM_PwmSetDuty: operation=rpIoHwAb_PWM.PwmSetDuty
            OA_rpIoHwAb_PWM_PwmSetDutyAndPeriod: operation=rpIoHwAb_PWM.PwmSetDutyAndPeriod
            OA_rpIoHwAb_PWM_PwmSetIdeal: operation=rpIoHwAb_PWM.PwmSetIdeal
  swc implementation IMPL_CBacklightCdd: programming-language=C, behavior=IB_CBacklightCdd
    code-descriptors:
      code CodeDescriptor
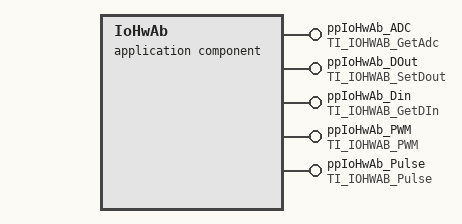
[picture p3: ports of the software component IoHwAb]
  application sw component type IoHwAb
    5 x provide port:
      ppIoHwAb_ADC: provided-interface=TI_IOHWAB_GetAdc
        provided-com-specs:
          operation=GetAsyncRawAdc, queue-length=1
          operation=GetProcessedAdc, queue-length=1
          operation=GetSyncRawAdc, queue-length=1
      ppIoHwAb_DOut: provided-com-specs=[{operation=SetOutputGroup, queue-length=1}, {operation=SetOutputPin, queue-length=1}], provided-interface=TI_IOHWAB_SetDout
      ppIoHwAb_Din: provided-interface=TI_IOHWAB_GetDIn
        provided-com-specs:
          operation=GetAsyncRawInput, queue-length=1
          operation=GetInputGroup, queue-length=1
          operation=GetProcessedInput, queue-length=1
          operation=GetSyncRawInput, queue-length=1
      ppIoHwAb_PWM: provided-interface=TI_IOHWAB_PWM
        provided-com-specs:
          operation=PwmSetDuty, queue-length=1
          operation=PwmSetDutyAndPeriod, queue-length=1
          operation=PwmSetIdeal, queue-length=1
      ppIoHwAb_Pulse: provided-interface=TI_IOHWAB_Pulse
        provided-com-specs:
          operation=GetCurrentSignalStatus_PulseInput, queue-length=1
          operation=GetCurrentSpeed_PulseInput, queue-length=1
          operation=GetRollingCount_PulseInput, queue-length=1
          operation=ResetRollingCount_PulseInput, queue-length=1
          operation=Start_Signal_Measurement_PulseInput, queue-length=1
          operation=Stop_Signal_Measurement_PulseInput, queue-length=1
          operation=Update_CalibParam_PulseInput, queue-length=1
    behavior IB_IoHwAb
      10 x operation invoked event:
        OIE_ppIoHwAb_ADC_IoHwAb_GetAsyncRawAdcTrigByGetAsyncRawAdc: start-on-event=IoHwAb_GetAsyncRawAdc, operation=ppIoHwAb_ADC.GetAsyncRawAdc
        OIE_ppIoHwAb_Din_IoHwAb_GetAsyncRawInputTrigByGetAsyncRawInput: start-on-event=IoHwAb_GetAsyncRawInput, operation=ppIoHwAb_Din.GetAsyncRawInput
        OIE_ppIoHwAb_Pulse_IoHwAb_GetCurrentSignalStatus_PulseInputTrigByGetCurrentSignalStatus_PulseInput: start-on-event=IoHwAb_GetCurrentSignalStatus_PulseInput, operation=ppIoHwAb_Pulse.GetCurrentSignalStatus_PulseInput
        OIE_ppIoHwAb_Pulse_IoHwAb_GetCurrentSpeed_PulseInputTrigByGetCurrentSpeed_PulseInput: start-on-event=IoHwAb_GetCurrentSpeed_PulseInput, operation=ppIoHwAb_Pulse.GetCurrentSpeed_PulseInput
        OIE_ppIoHwAb_Din_IoHwAb_GetInputGroupTrigByGetInputGroup: start-on-event=IoHwAb_GetInputGroup, operation=ppIoHwAb_Din.GetInputGroup
        OIE_ppIoHwAb_ADC_IoHwAb_GetProcessedAdcTrigByGetProcessedAdc: start-on-event=IoHwAb_GetProcessedAdc, operation=ppIoHwAb_ADC.GetProcessedAdc
        OIE_ppIoHwAb_Din_IoHwAb_GetProcessedInputTrigByGetProcessedInput: start-on-event=IoHwAb_GetProcessedInput, operation=ppIoHwAb_Din.GetProcessedInput
        OIE_ppIoHwAb_Pulse_IoHwAb_GetRollingCount_PulseInputTrigByGetRollingCount_PulseInput: start-on-event=IoHwAb_GetRollingCount_PulseInput, operation=ppIoHwAb_Pulse.GetRollingCount_PulseInput
        OIE_ppIoHwAb_ADC_IoHwAb_GetSyncRawAdcTrigByGetSyncRawAdc: start-on-event=IoHwAb_GetSyncRawAdc, operation=ppIoHwAb_ADC.GetSyncRawAdc
        OIE_ppIoHwAb_Din_IoHwAb_GetSyncRawInputTrigByGetSyncRawInput: start-on-event=IoHwAb_GetSyncRawInput, operation=ppIoHwAb_Din.GetSyncRawInput
      5 x timing event:
        TEIoHwAb_MainFunction: start-on-event=IoHwAb_MainFunction, period=0.01
        TEIoHwAb_OsTask_SafeBsw_Task_10ms: start-on-event=IoHwAb_OsTask_SafeBsw_Task_10ms, period=0.01
        TEIoHwAb_OsTask_SafeBsw_WdgM_CheckPoint_10ms: start-on-event=IoHwAb_OsTask_SafeBsw_WdgM_CheckPoint_10ms, period=0.01
        TEIoHwAb_OsTask_SafeBsw_WdgM_CheckPoint_20ms: start-on-event=IoHwAb_OsTask_SafeBsw_WdgM_CheckPoint_20ms, period=0.02
        TEIoHwAb_OsTask_SafeBsw_WdgM_CheckPoint_30ms: start-on-event=IoHwAb_OsTask_SafeBsw_WdgM_CheckPoint_30ms, period=0.03
      9 x operation invoked event:
        OIE_ppIoHwAb_PWM_IoHwAb_PwmSetDutyTrigByPwmSetDuty: start-on-event=IoHwAb_PwmSetDuty, operation=ppIoHwAb_PWM.PwmSetDuty
        OIE_ppIoHwAb_PWM_IoHwAb_PwmSetDutyAndPeriodTrigByPwmSetDutyAndPeriod: start-on-event=IoHwAb_PwmSetDutyAndPeriod, operation=ppIoHwAb_PWM.PwmSetDutyAndPeriod
        OIE_ppIoHwAb_PWM_IoHwAb_PwmSetIdealTrigByPwmSetIdeal: start-on-event=IoHwAb_PwmSetIdeal, operation=ppIoHwAb_PWM.PwmSetIdeal
        OIE_ppIoHwAb_Pulse_IoHwAb_ResetRollingCount_PulseInputTrigByResetRollingCount_PulseInput: start-on-event=IoHwAb_ResetRollingCount_PulseInput, operation=ppIoHwAb_Pulse.ResetRollingCount_PulseInput
        OIE_ppIoHwAb_DOut_IoHwAb_SetOutputGroupTrigBySetOutputGroup: start-on-event=IoHwAb_SetOutputGroup, operation=ppIoHwAb_DOut.SetOutputGroup
        OIE_ppIoHwAb_DOut_IoHwAb_SetOutputPinTrigBySetOutputPin: start-on-event=IoHwAb_SetOutputPin, operation=ppIoHwAb_DOut.SetOutputPin
        OIE_ppIoHwAb_Pulse_IoHwAb_Start_Signal_Measurement_PulseInputTrigByStart_Signal_Measurement_PulseInput: start-on-event=IoHwAb_Start_Signal_Measurement_PulseInput, operation=ppIoHwAb_Pulse.Start_Signal_Measurement_PulseInput
        OIE_ppIoHwAb_Pulse_IoHwAb_Stop_Signal_Measurement_PulseInputTrigByStop_Signal_Measurement_PulseInput: start-on-event=IoHwAb_Stop_Signal_Measurement_PulseInput, operation=ppIoHwAb_Pulse.Stop_Signal_Measurement_PulseInput
        OIE_ppIoHwAb_Pulse_IoHwAb_Update_CalibParam_PulseInputTrigByUpdate_CalibParam_PulseInput: start-on-event=IoHwAb_Update_CalibParam_PulseInput, operation=ppIoHwAb_Pulse.Update_CalibParam_PulseInput
      port-api-options:
        enable-take-address=false, indirect-api=false, port=ppIoHwAb_ADC
        enable-take-address=false, indirect-api=false, port=ppIoHwAb_DOut
        enable-take-address=false, indirect-api=false, port=ppIoHwAb_Din
        enable-take-address=false, indirect-api=false, port=ppIoHwAb_PWM
        enable-take-address=false, indirect-api=false, port=ppIoHwAb_Pulse
      24 x runnable, all with can-be-invoked-concurrently=true:
        IoHwAb_GetAsyncRawAdc
        IoHwAb_GetAsyncRawInput
        IoHwAb_GetCurrentSignalStatus_PulseInput
        IoHwAb_GetCurrentSpeed_PulseInput
        IoHwAb_GetInputGroup
        IoHwAb_GetProcessedAdc
        IoHwAb_GetProcessedInput
        IoHwAb_GetRollingCount_PulseInput
        IoHwAb_GetSyncRawAdc
        IoHwAb_GetSyncRawInput
        IoHwAb_MainFunction
        IoHwAb_OsTask_SafeBsw_Task_10ms
        IoHwAb_OsTask_SafeBsw_WdgM_CheckPoint_10ms
        IoHwAb_OsTask_SafeBsw_WdgM_CheckPoint_20ms
        IoHwAb_OsTask_SafeBsw_WdgM_CheckPoint_30ms
        IoHwAb_PwmSetDuty
        IoHwAb_PwmSetDutyAndPeriod
        IoHwAb_PwmSetIdeal
        IoHwAb_ResetRollingCount_PulseInput
        IoHwAb_SetOutputGroup
        IoHwAb_SetOutputPin
        IoHwAb_Start_Signal_Measurement_PulseInput
        IoHwAb_Stop_Signal_Measurement_PulseInput
        IoHwAb_Update_CalibParam_PulseInput
  swc implementation IMPL_IoHwAb: programming-language=C, behavior=IB_IoHwAb
    code-descriptors:
      code CodeDescriptor
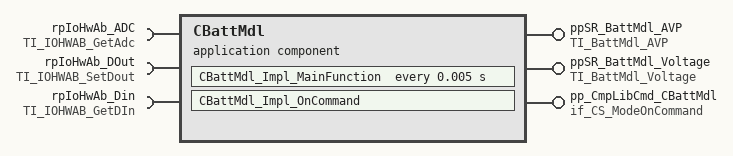
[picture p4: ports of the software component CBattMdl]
  application sw component type CBattMdl
    provide port ppSR_BattMdl_AVP: provided-interface=TI_BattMdl_AVP
      provided-com-specs:
        data-element=HVP0Flag, uses-end-to-end-protection=0, init-value=constant-reference=CBattMdlHVP0FlagValue0
        data-element=HVSD{0..4}Flag, uses-end-to-end-protection=0, init-value=constant-reference=CBattMdlHVSD{0..4}FlagValue0
        data-element=LVP0Flag, uses-end-to-end-protection=0, init-value=constant-reference=CBattMdlLVP0FlagValue0
        data-element=LVP1Flag, uses-end-to-end-protection=0, init-value=constant-reference=CBattMdlLVP1FlagValue0
        data-element=LVSD{0..4}Flag, uses-end-to-end-protection=0, init-value=constant-reference=CBattMdlLVSD{0..4}FlagValue0
        data-element=SVPFlag, uses-end-to-end-protection=0, init-value=constant-reference=CBattMdlSVPFlagValue0
    provide port ppSR_BattMdl_Voltage: nonqueued-sender-com-spec{data-element=OverVoltageInterruptFlag, uses-end-to-end-protection=0, init-value=constant-reference=CBattMdlOverVoltageInterruptFlagValue0}, provided-interface=TI_BattMdl_Voltage
    provide port pp_CmpLibCmd_CBattMdl: server-com-spec{operation=Impl_OnCommand, queue-length=1}, provided-interface=if_CS_ModeOnCommand
    require port rpIoHwAb_ADC: required-interface=TI_IOHWAB_GetAdc
    require port rpIoHwAb_DOut: required-interface=TI_IOHWAB_SetDout
    require port rpIoHwAb_Din: required-interface=TI_IOHWAB_GetDIn
    behavior IB_CBattMdl
      timing event TECBattMdl_Impl_MainFunction: start-on-event=CBattMdl_Impl_MainFunction, period=0.005
      operation invoked event OIE_pp_CmpLibCmd_CBattMdl_CBattMdl_Impl_OnCommandTrigByImpl_OnCommand: start-on-event=CBattMdl_Impl_OnCommand, operation=pp_CmpLibCmd_CBattMdl.Impl_OnCommand
      port-api-options:
        enable-take-address=false, indirect-api=false, port=ppSR_BattMdl_AVP
        enable-take-address=false, indirect-api=false, port=ppSR_BattMdl_Voltage
        enable-take-address=false, indirect-api=false, port=pp_CmpLibCmd_CBattMdl
        enable-take-address=false, indirect-api=false, port=CBattMdl/rpIoHwAb_ADC
        enable-take-address=false, indirect-api=false, port=CBattMdl/rpIoHwAb_DOut
        enable-take-address=false, indirect-api=false, port=CBattMdl/rpIoHwAb_Din
      runnable CBattMdl_Impl_MainFunction: can-be-invoked-concurrently=true
        data-send-points:
          15 x access:
            DWA_ppSR_BattMdl_AVP_HVP0Flag: accessed-variable=ppSR_BattMdl_AVP.HVP0Flag
            DWA_ppSR_BattMdl_AVP_HVSD{0..4}Flag: accessed-variable=ppSR_BattMdl_AVP.HVSD{0..4}Flag
            DWA_ppSR_BattMdl_AVP_LVP0Flag: accessed-variable=ppSR_BattMdl_AVP.LVP0Flag
            DWA_ppSR_BattMdl_AVP_LVP1Flag: accessed-variable=ppSR_BattMdl_AVP.LVP1Flag
            DWA_ppSR_BattMdl_AVP_LVSD{0..4}Flag: accessed-variable=ppSR_BattMdl_AVP.LVSD{0..4}Flag
            DWA_ppSR_BattMdl_AVP_SVPFlag: accessed-variable=ppSR_BattMdl_AVP.SVPFlag
            DWA_ppSR_BattMdl_Voltage_OverVoltageInterruptFlag: accessed-variable=ppSR_BattMdl_Voltage.OverVoltageInterruptFlag
        9 x sync call, all with timeout=0.0:
          OA_rpIoHwAb_ADC_GetAsyncRawAdc: operation=rpIoHwAb_ADC.GetAsyncRawAdc
          OA_rpIoHwAb_ADC_GetSyncRawAdc: operation=rpIoHwAb_ADC.GetSyncRawAdc
          OA_rpIoHwAb_ADC_GetProcessedAdc: operation=rpIoHwAb_ADC.GetProcessedAdc
          OA_rpIoHwAb_DOut_SetOutputGroup: operation=rpIoHwAb_DOut.SetOutputGroup
          OA_rpIoHwAb_DOut_SetOutputPin: operation=rpIoHwAb_DOut.SetOutputPin
          OA_rpIoHwAb_Din_GetAsyncRawInput: operation=rpIoHwAb_Din.GetAsyncRawInput
          OA_rpIoHwAb_Din_GetProcessedInput: operation=rpIoHwAb_Din.GetProcessedInput
          OA_rpIoHwAb_Din_GetSyncRawInput: operation=rpIoHwAb_Din.GetSyncRawInput
          OA_rpIoHwAb_Din_GetInputGroup: operation=rpIoHwAb_Din.GetInputGroup
      runnable CBattMdl_Impl_OnCommand: can-be-invoked-concurrently=true
        data-send-points:
          15 x access:
            DWA_ppSR_BattMdl_AVP_HVP0Flag: accessed-variable=ppSR_BattMdl_AVP.HVP0Flag
            DWA_ppSR_BattMdl_AVP_HVSD{0..4}Flag: accessed-variable=ppSR_BattMdl_AVP.HVSD{0..4}Flag
            DWA_ppSR_BattMdl_AVP_LVP0Flag: accessed-variable=ppSR_BattMdl_AVP.LVP0Flag
            DWA_ppSR_BattMdl_AVP_LVP1Flag: accessed-variable=ppSR_BattMdl_AVP.LVP1Flag
            DWA_ppSR_BattMdl_AVP_LVSD{0..4}Flag: accessed-variable=ppSR_BattMdl_AVP.LVSD{0..4}Flag
            DWA_ppSR_BattMdl_AVP_SVPFlag: accessed-variable=ppSR_BattMdl_AVP.SVPFlag
            DWA_ppSR_BattMdl_Voltage_OverVoltageInterruptFlag: accessed-variable=ppSR_BattMdl_Voltage.OverVoltageInterruptFlag
        9 x sync call, all with timeout=0.0:
          OA_rpIoHwAb_ADC_GetAsyncRawAdc: operation=rpIoHwAb_ADC.GetAsyncRawAdc
          OA_rpIoHwAb_ADC_GetSyncRawAdc: operation=rpIoHwAb_ADC.GetSyncRawAdc
          OA_rpIoHwAb_ADC_GetProcessedAdc: operation=rpIoHwAb_ADC.GetProcessedAdc
          OA_rpIoHwAb_DOut_SetOutputGroup: operation=rpIoHwAb_DOut.SetOutputGroup
          OA_rpIoHwAb_DOut_SetOutputPin: operation=rpIoHwAb_DOut.SetOutputPin
          OA_rpIoHwAb_Din_GetAsyncRawInput: operation=rpIoHwAb_Din.GetAsyncRawInput
          OA_rpIoHwAb_Din_GetProcessedInput: operation=rpIoHwAb_Din.GetProcessedInput
          OA_rpIoHwAb_Din_GetSyncRawInput: operation=rpIoHwAb_Din.GetSyncRawInput
          OA_rpIoHwAb_Din_GetInputGroup: operation=rpIoHwAb_Din.GetInputGroup
  15 x constant specification:
    CBattMdlHVP0FlagValue0: value-spec=CBattMdlHVP0FlagValue0:false
    CBattMdlHVSD{0..4}FlagValue0: value-spec=CBattMdlHVSD{0..4}FlagValue0:false
    CBattMdlLVP0FlagValue0: value-spec=CBattMdlLVP0FlagValue0:false
    CBattMdlLVP1FlagValue0: value-spec=CBattMdlLVP1FlagValue0:false
    CBattMdlLVSD{0..4}FlagValue0: value-spec=CBattMdlLVSD{0..4}FlagValue0:false
    CBattMdlSVPFlagValue0: value-spec=CBattMdlSVPFlagValue0:false
    CBattMdlOverVoltageInterruptFlagValue0: value-spec=CBattMdlOverVoltageInterruptFlagValue0:false
  swc implementation IMPL_CBattMdl: programming-language=C, behavior=IB_CBattMdl
    code-descriptors:
      code CodeDescriptor
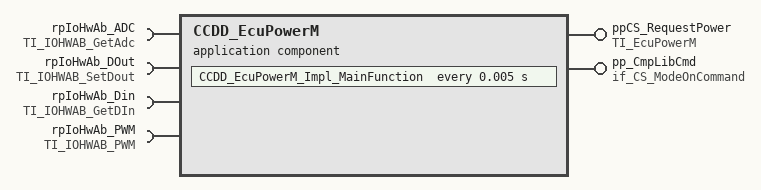
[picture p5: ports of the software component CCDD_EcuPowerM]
  application sw component type CCDD_EcuPowerM
    provide port ppCS_RequestPower: provided-interface=TI_EcuPowerM
      provided-com-specs:
        operation=EcuPowerM_GetDeviceStatus, queue-length=1
        operation=EcuPowerM_RequestPower, queue-length=1
    provide port pp_CmpLibCmd: server-com-spec{operation=Impl_OnCommand, queue-length=1}, provided-interface=if_CS_ModeOnCommand
    4 x require port:
      rpIoHwAb_ADC: required-interface=TI_IOHWAB_GetAdc
      rpIoHwAb_DOut: required-interface=TI_IOHWAB_SetDout
      rpIoHwAb_Din: required-interface=TI_IOHWAB_GetDIn
      rpIoHwAb_PWM: required-interface=TI_IOHWAB_PWM
    behavior IB_CCDD_EcuPowerM
      timing event TECCDD_EcuPowerM_Impl_MainFunction: start-on-event=CCDD_EcuPowerM_Impl_MainFunction, period=0.005
      operation invoked event OIE_ppCS_RequestPower_EcuPowerM_GetDeviceStatusTrigByEcuPowerM_GetDeviceStatus: start-on-event=EcuPowerM_GetDeviceStatus, operation=ppCS_RequestPower.EcuPowerM_GetDeviceStatus
      operation invoked event OIE_ppCS_RequestPower_EcuPowerM_RequestPowerTrigByEcuPowerM_RequestPower: start-on-event=EcuPowerM_RequestPower, operation=ppCS_RequestPower.EcuPowerM_RequestPower
      operation invoked event OIE_pp_CmpLibCmd_CCDD_EcuPowerM_Impl_OnCommandTrigByImpl_OnCommand: start-on-event=CCDD_EcuPowerM_Impl_OnCommand, operation=pp_CmpLibCmd.Impl_OnCommand
      port-api-options:
        enable-take-address=false, indirect-api=false, port=ppCS_RequestPower
        enable-take-address=false, indirect-api=false, port=CCDD_EcuPowerM/pp_CmpLibCmd
        enable-take-address=false, indirect-api=false, port=CCDD_EcuPowerM/rpIoHwAb_ADC
        enable-take-address=false, indirect-api=false, port=CCDD_EcuPowerM/rpIoHwAb_DOut
        enable-take-address=false, indirect-api=false, port=CCDD_EcuPowerM/rpIoHwAb_Din
        enable-take-address=false, indirect-api=false, port=CCDD_EcuPowerM/rpIoHwAb_PWM
      4 x runnable, all with can-be-invoked-concurrently=true:
        CCDD_EcuPowerM_Impl_MainFunction
          12 x sync call, all with timeout=0.0:
            OA_rpIoHwAb_ADC_GetAsyncRawAdc: operation=rpIoHwAb_ADC.GetAsyncRawAdc
            OA_rpIoHwAb_ADC_GetSyncRawAdc: operation=rpIoHwAb_ADC.GetSyncRawAdc
            OA_rpIoHwAb_ADC_GetProcessedAdc: operation=rpIoHwAb_ADC.GetProcessedAdc
            OA_rpIoHwAb_DOut_SetOutputGroup: operation=rpIoHwAb_DOut.SetOutputGroup
            OA_rpIoHwAb_DOut_SetOutputPin: operation=rpIoHwAb_DOut.SetOutputPin
            OA_rpIoHwAb_Din_GetAsyncRawInput: operation=rpIoHwAb_Din.GetAsyncRawInput
            OA_rpIoHwAb_Din_GetProcessedInput: operation=rpIoHwAb_Din.GetProcessedInput
            OA_rpIoHwAb_Din_GetSyncRawInput: operation=rpIoHwAb_Din.GetSyncRawInput
            OA_rpIoHwAb_Din_GetInputGroup: operation=rpIoHwAb_Din.GetInputGroup
            OA_rpIoHwAb_PWM_PwmSetDuty: operation=rpIoHwAb_PWM.PwmSetDuty
            OA_rpIoHwAb_PWM_PwmSetDutyAndPeriod: operation=rpIoHwAb_PWM.PwmSetDutyAndPeriod
            OA_rpIoHwAb_PWM_PwmSetIdeal: operation=rpIoHwAb_PWM.PwmSetIdeal
        EcuPowerM_GetDeviceStatus
          12 x sync call, all with timeout=0.0:
            OA_rpIoHwAb_ADC_GetAsyncRawAdc: operation=rpIoHwAb_ADC.GetAsyncRawAdc
            OA_rpIoHwAb_ADC_GetSyncRawAdc: operation=rpIoHwAb_ADC.GetSyncRawAdc
            OA_rpIoHwAb_ADC_GetProcessedAdc: operation=rpIoHwAb_ADC.GetProcessedAdc
            OA_rpIoHwAb_DOut_SetOutputGroup: operation=rpIoHwAb_DOut.SetOutputGroup
            OA_rpIoHwAb_DOut_SetOutputPin: operation=rpIoHwAb_DOut.SetOutputPin
            OA_rpIoHwAb_Din_GetAsyncRawInput: operation=rpIoHwAb_Din.GetAsyncRawInput
            OA_rpIoHwAb_Din_GetProcessedInput: operation=rpIoHwAb_Din.GetProcessedInput
            OA_rpIoHwAb_Din_GetSyncRawInput: operation=rpIoHwAb_Din.GetSyncRawInput
            OA_rpIoHwAb_Din_GetInputGroup: operation=rpIoHwAb_Din.GetInputGroup
            OA_rpIoHwAb_PWM_PwmSetDuty: operation=rpIoHwAb_PWM.PwmSetDuty
            OA_rpIoHwAb_PWM_PwmSetDutyAndPeriod: operation=rpIoHwAb_PWM.PwmSetDutyAndPeriod
            OA_rpIoHwAb_PWM_PwmSetIdeal: operation=rpIoHwAb_PWM.PwmSetIdeal
        EcuPowerM_RequestPower
          12 x sync call, all with timeout=0.0:
            OA_rpIoHwAb_ADC_GetAsyncRawAdc: operation=rpIoHwAb_ADC.GetAsyncRawAdc
            OA_rpIoHwAb_ADC_GetSyncRawAdc: operation=rpIoHwAb_ADC.GetSyncRawAdc
            OA_rpIoHwAb_ADC_GetProcessedAdc: operation=rpIoHwAb_ADC.GetProcessedAdc
            OA_rpIoHwAb_DOut_SetOutputGroup: operation=rpIoHwAb_DOut.SetOutputGroup
            OA_rpIoHwAb_DOut_SetOutputPin: operation=rpIoHwAb_DOut.SetOutputPin
            OA_rpIoHwAb_Din_GetAsyncRawInput: operation=rpIoHwAb_Din.GetAsyncRawInput
            OA_rpIoHwAb_Din_GetProcessedInput: operation=rpIoHwAb_Din.GetProcessedInput
            OA_rpIoHwAb_Din_GetSyncRawInput: operation=rpIoHwAb_Din.GetSyncRawInput
            OA_rpIoHwAb_Din_GetInputGroup: operation=rpIoHwAb_Din.GetInputGroup
            OA_rpIoHwAb_PWM_PwmSetDuty: operation=rpIoHwAb_PWM.PwmSetDuty
            OA_rpIoHwAb_PWM_PwmSetDutyAndPeriod: operation=rpIoHwAb_PWM.PwmSetDutyAndPeriod
            OA_rpIoHwAb_PWM_PwmSetIdeal: operation=rpIoHwAb_PWM.PwmSetIdeal
        CCDD_EcuPowerM_Impl_OnCommand
  swc implementation IMPL_CCDD_EcuPowerM: programming-language=C, behavior=IB_CCDD_EcuPowerM
    code-descriptors:
      code CodeDescriptor
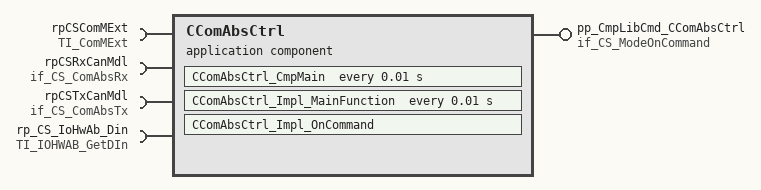
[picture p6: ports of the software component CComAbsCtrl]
  application sw component type CComAbsCtrl
    provide port pp_CmpLibCmd_CComAbsCtrl: server-com-spec{operation=Impl_OnCommand, queue-length=1}, provided-interface=if_CS_ModeOnCommand
    4 x require port:
      rpCSComMExt: required-interface=TI_ComMExt
      rpCSRxCanMdl: required-interface=if_CS_ComAbsRx
      rpCSTxCanMdl: required-interface=if_CS_ComAbsTx
      rp_CS_IoHwAb_Din: required-interface=TI_IOHWAB_GetDIn
    behavior IB_CComAbsCtrl
      timing event TECComAbsCtrl_CmpMain: start-on-event=CComAbsCtrl_CmpMain, period=0.01
      timing event TECComAbsCtrl_Impl_MainFunction: start-on-event=CComAbsCtrl_Impl_MainFunction, period=0.01
      operation invoked event OIE_pp_CmpLibCmd_CComAbsCtrl_CComAbsCtrl_Impl_OnCommandTrigByImpl_OnCommand: start-on-event=CComAbsCtrl_Impl_OnCommand, operation=pp_CmpLibCmd_CComAbsCtrl.Impl_OnCommand
      port-api-options:
        enable-take-address=false, indirect-api=false, port=pp_CmpLibCmd_CComAbsCtrl
        enable-take-address=false, indirect-api=false, port=rpCSComMExt
        enable-take-address=false, indirect-api=false, port=rpCSRxCanMdl
        enable-take-address=false, indirect-api=false, port=rpCSTxCanMdl
        enable-take-address=false, indirect-api=false, port=rp_CS_IoHwAb_Din
      runnable CComAbsCtrl_CmpMain: can-be-invoked-concurrently=true
      runnable CComAbsCtrl_Impl_MainFunction: can-be-invoked-concurrently=true
        32 x sync call, all with timeout=0.0:
          OA_rpCSComMExt_Get_MCAN_ERR_PIN_Status: operation=rpCSComMExt.Get_MCAN_ERR_PIN_Status
          OA_rpCSComMExt_Impl_MainFunction: operation=rpCSComMExt.Impl_MainFunction
          OA_rpCSComMExt_Init: operation=rpCSComMExt.Init
          OA_rpCSComMExt_GetBusOffStatus: operation=rpCSComMExt.GetBusOffStatus
          OA_rpCSComMExt_CAN_RequestCommunication: operation=rpCSComMExt.CAN_RequestCommunication
          OA_rpCSComMExt_CAN_GetCurrentComMode: operation=rpCSComMExt.CAN_GetCurrentComMode
          OA_rpCSComMExt_CAN_ReleaseCommunication: operation=rpCSComMExt.CAN_ReleaseCommunication
          OA_rpCSComMExt_CAN_DeActivateSilentCommunication: operation=rpCSComMExt.CAN_DeActivateSilentCommunication
          OA_rpCSComMExt_CAN_CommControlSetDone: operation=rpCSComMExt.CAN_CommControlSetDone
          OA_rpCSComMExt_CAN_CommControlDeActivateTx: operation=rpCSComMExt.CAN_CommControlDeActivateTx
          OA_rpCSComMExt_CAN_CommControlDeActivateRx: operation=rpCSComMExt.CAN_CommControlDeActivateRx
          OA_rpCSComMExt_CAN_ActivateSilentCommunication: operation=rpCSComMExt.CAN_ActivateSilentCommunication
          OA_rpCSComMExt_CAN_CommControlActivateRx: operation=rpCSComMExt.CAN_CommControlActivateRx
          OA_rpCSComMExt_CAN_CommControlActivateTx: operation=rpCSComMExt.CAN_CommControlActivateTx
          OA_rpCSRxCanMdl_RxCan_GetSignalValueU8Arr: operation=rpCSRxCanMdl.RxCan_GetSignalValueU8Arr
          OA_rpCSRxCanMdl_RxCan_SetSignalInitValue: operation=rpCSRxCanMdl.RxCan_SetSignalInitValue
          OA_rpCSRxCanMdl_RxCan_SetSignalInitValueU8Arr: operation=rpCSRxCanMdl.RxCan_SetSignalInitValueU8Arr
          OA_rpCSRxCanMdl_RxCan_SignalInvalidProcessingControl: operation=rpCSRxCanMdl.RxCan_SignalInvalidProcessingControl
          OA_rpCSRxCanMdl_RxCan_SignalMissingProcessingControl: operation=rpCSRxCanMdl.RxCan_SignalMissingProcessingControl
          OA_rpCSRxCanMdl_RxCan_SignalNRProcessingControl: operation=rpCSRxCanMdl.RxCan_SignalNRProcessingControl
          OA_rpCSRxCanMdl_RxCan_SignalGetJustRcvdStatus: operation=rpCSRxCanMdl.RxCan_SignalGetJustRcvdStatus
          OA_rpCSRxCanMdl_RxCan_SignalClearJustRcvdStatus: operation=rpCSRxCanMdl.RxCan_SignalClearJustRcvdStatus
          OA_rpCSRxCanMdl_RxCan_GetSignalValue: operation=rpCSRxCanMdl.RxCan_GetSignalValue
          OA_rpCSTxCanMdl_TxCan_ClearCanSignalTxConfirmation: operation=rpCSTxCanMdl.TxCan_ClearCanSignalTxConfirmation
          OA_rpCSTxCanMdl_TxCan_GetCanSignalTxConfirmation: operation=rpCSTxCanMdl.TxCan_GetCanSignalTxConfirmation
          OA_rpCSTxCanMdl_TxCan_SetSignalFromRetentionBuffer: operation=rpCSTxCanMdl.TxCan_SetSignalFromRetentionBuffer
          OA_rpCSTxCanMdl_TxCan_SetSignalValue: operation=rpCSTxCanMdl.TxCan_SetSignalValue
          OA_rpCSTxCanMdl_TxCan_SetSignalValueU8Arr: operation=rpCSTxCanMdl.TxCan_SetSignalValueU8Arr
          OA_rp_CS_IoHwAb_Din_GetAsyncRawInput: operation=rp_CS_IoHwAb_Din.GetAsyncRawInput
          OA_rp_CS_IoHwAb_Din_GetProcessedInput: operation=rp_CS_IoHwAb_Din.GetProcessedInput
          OA_rp_CS_IoHwAb_Din_GetSyncRawInput: operation=rp_CS_IoHwAb_Din.GetSyncRawInput
          OA_rp_CS_IoHwAb_Din_GetInputGroup: operation=rp_CS_IoHwAb_Din.GetInputGroup
      runnable CComAbsCtrl_Impl_OnCommand: can-be-invoked-concurrently=true
  swc implementation IMPL_CComAbsCtrl: programming-language=C, behavior=IB_CComAbsCtrl
    code-descriptors:
      code CodeDescriptor
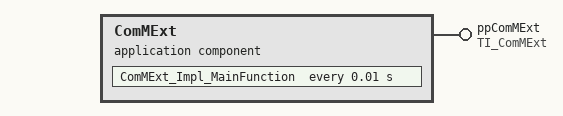
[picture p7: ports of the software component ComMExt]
  application sw component type ComMExt
    provide port ppComMExt: provided-interface=TI_ComMExt
      provided-com-specs:
        operation=CAN_ActivateSilentCommunication, queue-length=1
        operation=CAN_CommControlActivateRx, queue-length=1
        operation=CAN_CommControlActivateTx, queue-length=1
        operation=CAN_CommControlDeActivateRx, queue-length=1
        operation=CAN_CommControlDeActivateTx, queue-length=1
        operation=CAN_CommControlSetDone, queue-length=1
        operation=CAN_DeActivateSilentCommunication, queue-length=1
        operation=CAN_GetCurrentComMode, queue-length=1
        operation=CAN_ReleaseCommunication, queue-length=1
        operation=CAN_RequestCommunication, queue-length=1
        operation=GetBusOffStatus, queue-length=1
        operation=Get_MCAN_ERR_PIN_Status, queue-length=1
        operation=Impl_MainFunction, queue-length=1
        operation=TI_ComMExt/Init, queue-length=1
    behavior IB_ComMExt: port-api-option{enable-take-address=false, indirect-api=false, port=ppComMExt}
      12 x operation invoked event:
        OIE_ppComMExt_ComMExt_CAN_ActivateSilentCommunicationTrigByCAN_ActivateSilentCommunication: start-on-event=ComMExt_CAN_ActivateSilentCommunication, operation=ppComMExt.CAN_ActivateSilentCommunication
        OIE_ppComMExt_ComMExt_CAN_CommControlActivateRxTrigByCAN_CommControlActivateRx: start-on-event=ComMExt_CAN_CommControlActivateRx, operation=ppComMExt.CAN_CommControlActivateRx
        OIE_ppComMExt_ComMExt_CAN_CommControlActivateTxTrigByCAN_CommControlActivateTx: start-on-event=ComMExt_CAN_CommControlActivateTx, operation=ppComMExt.CAN_CommControlActivateTx
        OIE_ppComMExt_ComMExt_CAN_CommControlDeActivateRxTrigByCAN_CommControlDeActivateRx: start-on-event=ComMExt_CAN_CommControlDeActivateRx, operation=ppComMExt.CAN_CommControlDeActivateRx
        OIE_ppComMExt_ComMExt_CAN_CommControlDeActivateTxTrigByCAN_CommControlDeActivateTx: start-on-event=ComMExt_CAN_CommControlDeActivateTx, operation=ppComMExt.CAN_CommControlDeActivateTx
        OIE_ppComMExt_ComMExt_CAN_CommControlSetDoneTrigByCAN_CommControlSetDone: start-on-event=ComMExt_CAN_CommControlSetDone, operation=ppComMExt.CAN_CommControlSetDone
        OIE_ppComMExt_ComMExt_CAN_DeActivateSilentCommunicationTrigByCAN_DeActivateSilentCommunication: start-on-event=ComMExt_CAN_DeActivateSilentCommunication, operation=ppComMExt.CAN_DeActivateSilentCommunication
        OIE_ppComMExt_ComMExt_CAN_GetCurrentComModeTrigByCAN_GetCurrentComMode: start-on-event=ComMExt_CAN_GetCurrentComMode, operation=ppComMExt.CAN_GetCurrentComMode
        OIE_ppComMExt_ComMExt_CAN_ReleaseCommunicationTrigByCAN_ReleaseCommunication: start-on-event=ComMExt_CAN_ReleaseCommunication, operation=ppComMExt.CAN_ReleaseCommunication
        OIE_ppComMExt_ComMExt_CAN_RequestCommunicationTrigByCAN_RequestCommunication: start-on-event=ComMExt_CAN_RequestCommunication, operation=ppComMExt.CAN_RequestCommunication
        OIE_ppComMExt_ComMExt_GetBusOffStatusTrigByGetBusOffStatus: start-on-event=ComMExt_GetBusOffStatus, operation=ppComMExt.GetBusOffStatus
        OIE_ppComMExt_ComMExt_Get_MCAN_ERR_PIN_StatusTrigByGet_MCAN_ERR_PIN_Status: start-on-event=ComMExt_Get_MCAN_ERR_PIN_Status, operation=ppComMExt.Get_MCAN_ERR_PIN_Status
      timing event TEComMExt_Impl_MainFunction: start-on-event=ComMExt_Impl_MainFunction, period=0.01
      operation invoked event OIE_ppComMExt_ComMExt_InitTrigByInit: start-on-event=ComMExt_Init, operation=ppComMExt.Init
      14 x runnable, all with can-be-invoked-concurrently=true:
        ComMExt_CAN_ActivateSilentCommunication
        ComMExt_CAN_CommControlActivateRx
        ComMExt_CAN_CommControlActivateTx
        ComMExt_CAN_CommControlDeActivateRx
        ComMExt_CAN_CommControlDeActivateTx
        ComMExt_CAN_CommControlSetDone
        ComMExt_CAN_DeActivateSilentCommunication
        ComMExt_CAN_GetCurrentComMode
        ComMExt_CAN_ReleaseCommunication
        ComMExt_CAN_RequestCommunication
        ComMExt_GetBusOffStatus
        ComMExt_Get_MCAN_ERR_PIN_Status
        ComMExt_Impl_MainFunction
        ComMExt_Init
  swc implementation IMPL_ComMExt: programming-language=C, behavior=IB_ComMExt
    code-descriptors:
      code CodeDescriptor
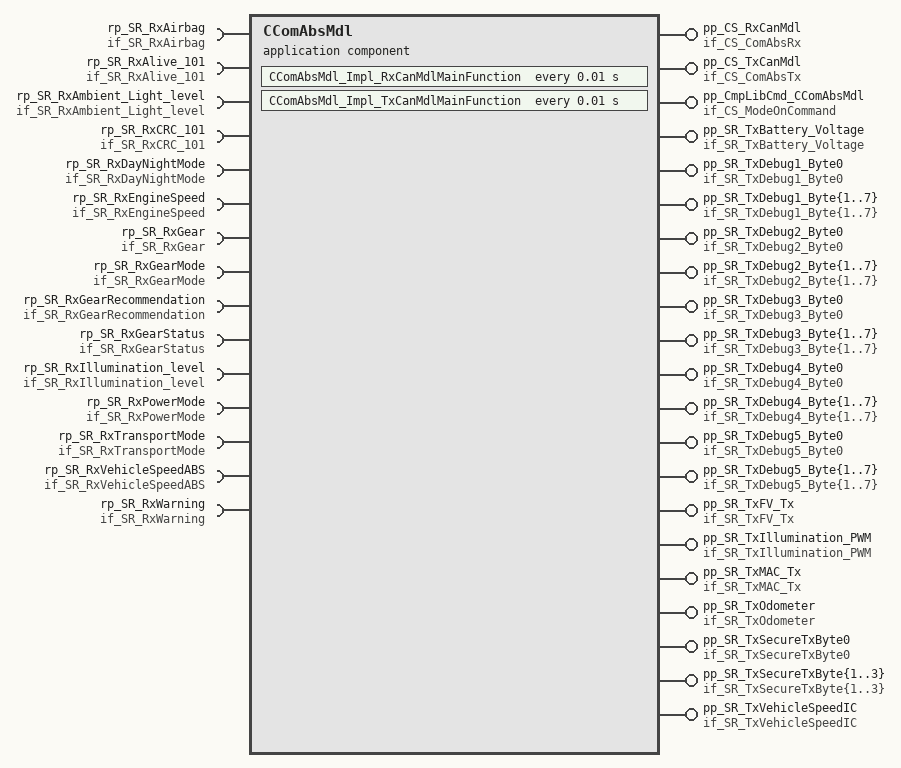
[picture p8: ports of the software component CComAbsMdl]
  application sw component type CComAbsMdl
    53 x provide port:
      pp_CS_RxCanMdl: provided-interface=if_CS_ComAbsRx
        provided-com-specs:
          operation=RxCan_GetSignalValue, queue-length=1
          operation=RxCan_GetSignalValueU8Arr, queue-length=1
          operation=if_CS_ComAbsRx/RxCan_SetSignalInitValue, queue-length=1
          operation=RxCan_SetSignalInitValueU8Arr, queue-length=1
          operation=if_CS_ComAbsRx/RxCan_SignalClearJustRcvdStatus, queue-length=1
          operation=if_CS_ComAbsRx/RxCan_SignalGetJustRcvdStatus, queue-length=1
          operation=if_CS_ComAbsRx/RxCan_SignalInvalidProcessingControl, queue-length=1
          operation=if_CS_ComAbsRx/RxCan_SignalMissingProcessingControl, queue-length=1
          operation=if_CS_ComAbsRx/RxCan_SignalNRProcessingControl, queue-length=1
      pp_CS_TxCanMdl: provided-interface=if_CS_ComAbsTx
        provided-com-specs:
          operation=TxCan_ClearCanSignalTxConfirmation, queue-length=1
          operation=TxCan_GetCanSignalTxConfirmation, queue-length=1
          operation=TxCan_SetSignalFromRetentionBuffer, queue-length=1
          operation=TxCan_SetSignalValue, queue-length=1
          operation=TxCan_SetSignalValueU8Arr, queue-length=1
      pp_CmpLibCmd_CComAbsMdl: server-com-spec{operation=Impl_OnCommand, queue-length=1}, provided-interface=if_CS_ModeOnCommand
      pp_SR_TxBattery_Voltage: nonqueued-sender-com-spec{data-element=Battery_Voltage, transmission-acknowledge=timeout=0.0, init-value=constant-reference=CComAbsMdlBattery_VoltageValue0}, provided-interface=if_SR_TxBattery_Voltage
      pp_SR_TxDebug1_Byte0: nonqueued-sender-com-spec{data-element=Debug1_Byte0, transmission-acknowledge=timeout=0.0, init-value=constant-reference=CComAbsMdlDebug1_Byte0Value0}, provided-interface=if_SR_TxDebug1_Byte0
      pp_SR_TxDebug1_Byte{1..7}: nonqueued-sender-com-spec{data-element=Debug1_Byte{1..7}, init-value=constant-reference=CComAbsMdlDebug1_Byte{1..7}Value0}, provided-interface=if_SR_TxDebug1_Byte{1..7}
      pp_SR_TxDebug2_Byte0: nonqueued-sender-com-spec{data-element=Debug2_Byte0, transmission-acknowledge=timeout=0.0, init-value=constant-reference=CComAbsMdlDebug2_Byte0Value0}, provided-interface=if_SR_TxDebug2_Byte0
      pp_SR_TxDebug2_Byte{1..7}: nonqueued-sender-com-spec{data-element=Debug2_Byte{1..7}, init-value=constant-reference=CComAbsMdlDebug2_Byte{1..7}Value0}, provided-interface=if_SR_TxDebug2_Byte{1..7}
      pp_SR_TxDebug3_Byte0: nonqueued-sender-com-spec{data-element=Debug3_Byte0, transmission-acknowledge=timeout=0.0, init-value=constant-reference=CComAbsMdlDebug3_Byte0Value0}, provided-interface=if_SR_TxDebug3_Byte0
      pp_SR_TxDebug3_Byte{1..7}: nonqueued-sender-com-spec{data-element=Debug3_Byte{1..7}, init-value=constant-reference=CComAbsMdlDebug3_Byte{1..7}Value0}, provided-interface=if_SR_TxDebug3_Byte{1..7}
      pp_SR_TxDebug4_Byte0: nonqueued-sender-com-spec{data-element=Debug4_Byte0, transmission-acknowledge=timeout=0.0, init-value=constant-reference=CComAbsMdlDebug4_Byte0Value0}, provided-interface=if_SR_TxDebug4_Byte0
      pp_SR_TxDebug4_Byte{1..7}: nonqueued-sender-com-spec{data-element=Debug4_Byte{1..7}, init-value=constant-reference=CComAbsMdlDebug4_Byte{1..7}Value0}, provided-interface=if_SR_TxDebug4_Byte{1..7}
      pp_SR_TxDebug5_Byte0: nonqueued-sender-com-spec{data-element=Debug5_Byte0, transmission-acknowledge=timeout=0.0, init-value=constant-reference=CComAbsMdlDebug5_Byte0Value0}, provided-interface=if_SR_TxDebug5_Byte0
      pp_SR_TxDebug5_Byte{1..7}: nonqueued-sender-com-spec{data-element=Debug5_Byte{1..7}, init-value=constant-reference=CComAbsMdlDebug5_Byte{1..7}Value0}, provided-interface=if_SR_TxDebug5_Byte{1..7}
      pp_SR_TxFV_Tx: nonqueued-sender-com-spec{data-element=FV_Tx, init-value=constant-reference=CComAbsMdlFV_TxValue0}, provided-interface=if_SR_TxFV_Tx
      pp_SR_TxIllumination_PWM: nonqueued-sender-com-spec{data-element=Illumination_PWM, transmission-acknowledge=timeout=0.0, init-value=constant-reference=CComAbsMdlIllumination_PWMValue0}, provided-interface=if_SR_TxIllumination_PWM
      pp_SR_TxMAC_Tx: nonqueued-sender-com-spec{data-element=MAC_Tx, init-value=constant-reference=CComAbsMdlMAC_TxValue0}, provided-interface=if_SR_TxMAC_Tx
      pp_SR_TxOdometer: nonqueued-sender-com-spec{data-element=Odometer, transmission-acknowledge=timeout=0.0, init-value=constant-reference=CComAbsMdlOdometerValue0}, provided-interface=if_SR_TxOdometer
      pp_SR_TxSecureTxByte0: nonqueued-sender-com-spec{data-element=SecureTxByte0, transmission-acknowledge=timeout=0.0, init-value=constant-reference=CComAbsMdlSecureTxByte0Value0}, provided-interface=if_SR_TxSecureTxByte0
      pp_SR_TxSecureTxByte{1..3}: nonqueued-sender-com-spec{data-element=SecureTxByte{1..3}, init-value=constant-reference=CComAbsMdlSecureTxByte{1..3}Value0}, provided-interface=if_SR_TxSecureTxByte{1..3}
      pp_SR_TxVehicleSpeedIC: nonqueued-sender-com-spec{data-element=VehicleSpeedIC, transmission-acknowledge=timeout=0.0, init-value=constant-reference=CComAbsMdlVehicleSpeedICValue0}, provided-interface=if_SR_TxVehicleSpeedIC
    15 x require port:
      rp_SR_RxAirbag: nonqueued-receiver-com-spec{data-element=Airbag, init-value=constant-reference=CComAbsMdlAirbagValue0}, required-interface=if_SR_RxAirbag
      rp_SR_RxAlive_101: nonqueued-receiver-com-spec{data-element=Alive_101, init-value=constant-reference=CComAbsMdlAlive_101Value0}, required-interface=if_SR_RxAlive_101
      rp_SR_RxAmbient_Light_level: nonqueued-receiver-com-spec{data-element=Ambient_Light_level, init-value=constant-reference=CComAbsMdlAmbient_Light_levelValue0}, required-interface=if_SR_RxAmbient_Light_level
      rp_SR_RxCRC_101: nonqueued-receiver-com-spec{data-element=CRC_101, init-value=constant-reference=CComAbsMdlCRC_101Value0}, required-interface=if_SR_RxCRC_101
      rp_SR_RxDayNightMode: nonqueued-receiver-com-spec{data-element=DayNightMode, init-value=constant-reference=CComAbsMdlDayNightModeValue0}, required-interface=if_SR_RxDayNightMode
      rp_SR_RxEngineSpeed: nonqueued-receiver-com-spec{data-element=EngineSpeed, init-value=constant-reference=CComAbsMdlEngineSpeedValue0}, required-interface=if_SR_RxEngineSpeed
      rp_SR_RxGear: nonqueued-receiver-com-spec{data-element=Gear, init-value=constant-reference=CComAbsMdlGearValue0}, required-interface=if_SR_RxGear
      rp_SR_RxGearMode: nonqueued-receiver-com-spec{data-element=GearMode, init-value=constant-reference=CComAbsMdlGearModeValue0}, required-interface=if_SR_RxGearMode
      rp_SR_RxGearRecommendation: nonqueued-receiver-com-spec{data-element=GearRecommendation, init-value=constant-reference=CComAbsMdlGearRecommendationValue0}, required-interface=if_SR_RxGearRecommendation
      rp_SR_RxGearStatus: nonqueued-receiver-com-spec{data-element=GearStatus, init-value=constant-reference=CComAbsMdlGearStatusValue0}, required-interface=if_SR_RxGearStatus
      rp_SR_RxIllumination_level: nonqueued-receiver-com-spec{data-element=Illumination_level, init-value=constant-reference=CComAbsMdlIllumination_levelValue0}, required-interface=if_SR_RxIllumination_level
      rp_SR_RxPowerMode: nonqueued-receiver-com-spec{data-element=PowerMode, init-value=constant-reference=CComAbsMdlPowerModeValue0}, required-interface=if_SR_RxPowerMode
      rp_SR_RxTransportMode: nonqueued-receiver-com-spec{data-element=TransportMode, init-value=constant-reference=CComAbsMdlTransportModeValue0}, required-interface=if_SR_RxTransportMode
      rp_SR_RxVehicleSpeedABS: nonqueued-receiver-com-spec{data-element=VehicleSpeedABS, init-value=constant-reference=CComAbsMdlVehicleSpeedABSValue0}, required-interface=if_SR_RxVehicleSpeedABS
      rp_SR_RxWarning: nonqueued-receiver-com-spec{data-element=Warning, init-value=constant-reference=CComAbsMdlWarningValue0}, required-interface=if_SR_RxWarning
    behavior IB_CComAbsMdl
      operation invoked event OIE_pp_CmpLibCmd_CComAbsMdl_CComAbsMdl_Impl_OnCommandTrigByImpl_OnCommand: start-on-event=CComAbsMdl_Impl_OnCommand, operation=pp_CmpLibCmd_CComAbsMdl.Impl_OnCommand
      timing event TECComAbsMdl_Impl_RxCanMdlMainFunction: start-on-event=CComAbsMdl_Impl_RxCanMdlMainFunction, period=0.01
      timing event TECComAbsMdl_Impl_TxCanMdlMainFunction: start-on-event=CComAbsMdl_Impl_TxCanMdlMainFunction, period=0.01
      data received event DRECComAbsMdl_OnDataRx_DayNightModeTrigByDayNightMode: start-on-event=CComAbsMdl_OnDataRx_DayNightMode, data=rp_SR_RxDayNightMode.DayNightMode
      data received event DRECComAbsMdl_OnDataRx_PowerModeTrigByPowerMode: start-on-event=CComAbsMdl_OnDataRx_PowerMode, data=rp_SR_RxPowerMode.PowerMode
      data received event DRECComAbsMdl_OnDataRx_VehicleSpeedABSTrigByVehicleSpeedABS: start-on-event=CComAbsMdl_OnDataRx_VehicleSpeedABS, data=rp_SR_RxVehicleSpeedABS.VehicleSpeedABS
      10 x data send completed event:
        DSCECComAbsMdl_OnDataTx_Battery_VoltageTrigByBattery_Voltage: start-on-event=CComAbsMdl_OnDataTx_Battery_Voltage, event-source=DWA_pp_SR_TxBattery_Voltage_Battery_Voltage
        DSCECComAbsMdl_OnDataTx_Debug{1..5}_Byte0TrigByDebug{1..5}_Byte0: start-on-event=CComAbsMdl_OnDataTx_Debug{1..5}_Byte0, event-source=DWA_pp_SR_TxDebug{1..5}_Byte0_Debug{1..5}_Byte0
        DSCECComAbsMdl_OnDataTx_Illumination_PWMTrigByIllumination_PWM: start-on-event=CComAbsMdl_OnDataTx_Illumination_PWM, event-source=DWA_pp_SR_TxIllumination_PWM_Illumination_PWM
        DSCECComAbsMdl_OnDataTx_OdometerTrigByOdometer: start-on-event=CComAbsMdl_OnDataTx_Odometer, event-source=DWA_pp_SR_TxOdometer_Odometer
        DSCECComAbsMdl_OnDataTx_SecureTxByte0TrigBySecureTxByte0: start-on-event=CComAbsMdl_OnDataTx_SecureTxByte0, event-source=DWA_pp_SR_TxSecureTxByte0_SecureTxByte0
        DSCECComAbsMdl_OnDataTx_VehicleSpeedICTrigByVehicleSpeedIC: start-on-event=CComAbsMdl_OnDataTx_VehicleSpeedIC, event-source=DWA_pp_SR_TxVehicleSpeedIC_VehicleSpeedIC
      14 x operation invoked event:
        OIE_pp_CS_RxCanMdl_CComAbsMdl_RxCan_GetSignalValueTrigByRxCan_GetSignalValue: start-on-event=CComAbsMdl_RxCan_GetSignalValue, operation=pp_CS_RxCanMdl.RxCan_GetSignalValue
        OIE_pp_CS_RxCanMdl_CComAbsMdl_RxCan_GetSignalValueU8ArrTrigByRxCan_GetSignalValueU8Arr: start-on-event=CComAbsMdl_RxCan_GetSignalValueU8Arr, operation=pp_CS_RxCanMdl.RxCan_GetSignalValueU8Arr
        OIE_pp_CS_RxCanMdl_CComAbsMdl_RxCan_SetSignalInitValueTrigByRxCan_SetSignalInitValue: start-on-event=CComAbsMdl_RxCan_SetSignalInitValue, operation=pp_CS_RxCanMdl.RxCan_SetSignalInitValue
        OIE_pp_CS_RxCanMdl_CComAbsMdl_RxCan_SetSignalInitValueU8ArrTrigByRxCan_SetSignalInitValueU8Arr: start-on-event=CComAbsMdl_RxCan_SetSignalInitValueU8Arr, operation=pp_CS_RxCanMdl.RxCan_SetSignalInitValueU8Arr
        OIE_pp_CS_RxCanMdl_CComAbsMdl_RxCan_SignalClearJustRcvdStatusTrigByRxCan_SignalClearJustRcvdStatus: start-on-event=CComAbsMdl_RxCan_SignalClearJustRcvdStatus, operation=pp_CS_RxCanMdl.RxCan_SignalClearJustRcvdStatus
        OIE_pp_CS_RxCanMdl_CComAbsMdl_RxCan_SignalGetJustRcvdStatusTrigByRxCan_SignalGetJustRcvdStatus: start-on-event=CComAbsMdl_RxCan_SignalGetJustRcvdStatus, operation=pp_CS_RxCanMdl.RxCan_SignalGetJustRcvdStatus
        OIE_pp_CS_RxCanMdl_CComAbsMdl_RxCan_SignalInvalidProcessingControlTrigByRxCan_SignalInvalidProcessingControl: start-on-event=CComAbsMdl_RxCan_SignalInvalidProcessingControl, operation=pp_CS_RxCanMdl.RxCan_SignalInvalidProcessingControl
        OIE_pp_CS_RxCanMdl_CComAbsMdl_RxCan_SignalMissingProcessingControlTrigByRxCan_SignalMissingProcessingControl: start-on-event=CComAbsMdl_RxCan_SignalMissingProcessingControl, operation=pp_CS_RxCanMdl.RxCan_SignalMissingProcessingControl
        OIE_pp_CS_RxCanMdl_CComAbsMdl_RxCan_SignalNRProcessingControlTrigByRxCan_SignalNRProcessingControl: start-on-event=CComAbsMdl_RxCan_SignalNRProcessingControl, operation=pp_CS_RxCanMdl.RxCan_SignalNRProcessingControl
        OIE_pp_CS_TxCanMdl_CComAbsMdl_TxCan_ClearCanSignalTxConfirmationTrigByTxCan_ClearCanSignalTxConfirmation: start-on-event=CComAbsMdl_TxCan_ClearCanSignalTxConfirmation, operation=pp_CS_TxCanMdl.TxCan_ClearCanSignalTxConfirmation
        OIE_pp_CS_TxCanMdl_CComAbsMdl_TxCan_GetCanSignalTxConfirmationTrigByTxCan_GetCanSignalTxConfirmation: start-on-event=CComAbsMdl_TxCan_GetCanSignalTxConfirmation, operation=pp_CS_TxCanMdl.TxCan_GetCanSignalTxConfirmation
        OIE_pp_CS_TxCanMdl_CComAbsMdl_TxCan_SetSignalFromRetentionBufferTrigByTxCan_SetSignalFromRetentionBuffer: start-on-event=CComAbsMdl_TxCan_SetSignalFromRetentionBuffer, operation=pp_CS_TxCanMdl.TxCan_SetSignalFromRetentionBuffer
        OIE_pp_CS_TxCanMdl_CComAbsMdl_TxCan_SetSignalValueTrigByTxCan_SetSignalValue: start-on-event=CComAbsMdl_TxCan_SetSignalValue, operation=pp_CS_TxCanMdl.TxCan_SetSignalValue
        OIE_pp_CS_TxCanMdl_CComAbsMdl_TxCan_SetSignalValueU8ArrTrigByTxCan_SetSignalValueU8Arr: start-on-event=CComAbsMdl_TxCan_SetSignalValueU8Arr, operation=pp_CS_TxCanMdl.TxCan_SetSignalValueU8Arr
      port-api-options:
        enable-take-address=false, indirect-api=false, port=pp_CS_RxCanMdl
        enable-take-address=false, indirect-api=false, port=pp_CS_TxCanMdl
        enable-take-address=false, indirect-api=false, port=pp_CmpLibCmd_CComAbsMdl
        enable-take-address=false, indirect-api=false, port=pp_SR_TxBattery_Voltage
        enable-take-address=false, indirect-api=false, port=pp_SR_TxDebug1_Byte{0..7}
        enable-take-address=false, indirect-api=false, port=pp_SR_TxDebug2_Byte{0..7}
        enable-take-address=false, indirect-api=false, port=pp_SR_TxDebug3_Byte{0..7}
        enable-take-address=false, indirect-api=false, port=pp_SR_TxDebug4_Byte{0..7}
        enable-take-address=false, indirect-api=false, port=pp_SR_TxDebug5_Byte{0..7}
        enable-take-address=false, indirect-api=false, port=pp_SR_TxFV_Tx
        enable-take-address=false, indirect-api=false, port=pp_SR_TxIllumination_PWM
        enable-take-address=false, indirect-api=false, port=pp_SR_TxMAC_Tx
        enable-take-address=false, indirect-api=false, port=pp_SR_TxOdometer
        enable-take-address=false, indirect-api=false, port=pp_SR_TxSecureTxByte{0..3}
        enable-take-address=false, indirect-api=false, port=pp_SR_TxVehicleSpeedIC
        enable-take-address=false, indirect-api=false, port=rp_SR_RxAirbag
        enable-take-address=false, indirect-api=false, port=rp_SR_RxAlive_101
        enable-take-address=false, indirect-api=false, port=rp_SR_RxAmbient_Light_level
        enable-take-address=false, indirect-api=false, port=rp_SR_RxCRC_101
        enable-take-address=false, indirect-api=false, port=rp_SR_RxDayNightMode
        enable-take-address=false, indirect-api=false, port=rp_SR_RxEngineSpeed
        enable-take-address=false, indirect-api=false, port=rp_SR_RxGear
        enable-take-address=false, indirect-api=false, port=rp_SR_RxGearMode
        enable-take-address=false, indirect-api=false, port=rp_SR_RxGearRecommendation
        enable-take-address=false, indirect-api=false, port=rp_SR_RxGearStatus
        enable-take-address=false, indirect-api=false, port=rp_SR_RxIllumination_level
        enable-take-address=false, indirect-api=false, port=rp_SR_RxPowerMode
        enable-take-address=false, indirect-api=false, port=rp_SR_RxTransportMode
        enable-take-address=false, indirect-api=false, port=rp_SR_RxVehicleSpeedABS
        enable-take-address=false, indirect-api=false, port=rp_SR_RxWarning
      30 x runnable, all with can-be-invoked-concurrently=true:
        CComAbsMdl_Impl_OnCommand
        CComAbsMdl_Impl_RxCanMdlMainFunction
          data-receive-point-by-arguments:
            15 x access:
              DRA_rp_SR_RxAirbag_Airbag: accessed-variable=rp_SR_RxAirbag.Airbag
              DRA_rp_SR_RxAlive_101_Alive_101: accessed-variable=rp_SR_RxAlive_101.Alive_101
              DRA_rp_SR_RxAmbient_Light_level_Ambient_Light_level: accessed-variable=rp_SR_RxAmbient_Light_level.Ambient_Light_level
              DRA_rp_SR_RxCRC_101_CRC_101: accessed-variable=rp_SR_RxCRC_101.CRC_101
              DRA_rp_SR_RxDayNightMode_DayNightMode: accessed-variable=rp_SR_RxDayNightMode.DayNightMode
              DRA_rp_SR_RxEngineSpeed_EngineSpeed: accessed-variable=rp_SR_RxEngineSpeed.EngineSpeed
              DRA_rp_SR_RxGear_Gear: accessed-variable=rp_SR_RxGear.Gear
              DRA_rp_SR_RxGearMode_GearMode: accessed-variable=rp_SR_RxGearMode.GearMode
              DRA_rp_SR_RxGearRecommendation_GearRecommendation: accessed-variable=rp_SR_RxGearRecommendation.GearRecommendation
              DRA_rp_SR_RxGearStatus_GearStatus: accessed-variable=rp_SR_RxGearStatus.GearStatus
              DRA_rp_SR_RxIllumination_level_Illumination_level: accessed-variable=rp_SR_RxIllumination_level.Illumination_level
              DRA_rp_SR_RxPowerMode_PowerMode: accessed-variable=rp_SR_RxPowerMode.PowerMode
              DRA_rp_SR_RxTransportMode_TransportMode: accessed-variable=rp_SR_RxTransportMode.TransportMode
              DRA_rp_SR_RxVehicleSpeedABS_VehicleSpeedABS: accessed-variable=rp_SR_RxVehicleSpeedABS.VehicleSpeedABS
              DRA_rp_SR_RxWarning_Warning: accessed-variable=rp_SR_RxWarning.Warning
          data-send-points:
            50 x access:
              DWA_pp_SR_TxBattery_Voltage_Battery_Voltage: accessed-variable=pp_SR_TxBattery_Voltage.Battery_Voltage
              DWA_pp_SR_TxDebug1_Byte{0..7}_Debug1_Byte{0..7}: accessed-variable=pp_SR_TxDebug1_Byte{0..7}.Debug1_Byte{0..7}
              DWA_pp_SR_TxDebug2_Byte{0..7}_Debug2_Byte{0..7}: accessed-variable=pp_SR_TxDebug2_Byte{0..7}.Debug2_Byte{0..7}
              DWA_pp_SR_TxDebug3_Byte{0..7}_Debug3_Byte{0..7}: accessed-variable=pp_SR_TxDebug3_Byte{0..7}.Debug3_Byte{0..7}
              DWA_pp_SR_TxDebug4_Byte{0..7}_Debug4_Byte{0..7}: accessed-variable=pp_SR_TxDebug4_Byte{0..7}.Debug4_Byte{0..7}
              DWA_pp_SR_TxDebug5_Byte{0..7}_Debug5_Byte{0..7}: accessed-variable=pp_SR_TxDebug5_Byte{0..7}.Debug5_Byte{0..7}
              DWA_pp_SR_TxFV_Tx_FV_Tx: accessed-variable=pp_SR_TxFV_Tx.FV_Tx
              DWA_pp_SR_TxIllumination_PWM_Illumination_PWM: accessed-variable=pp_SR_TxIllumination_PWM.Illumination_PWM
              DWA_pp_SR_TxMAC_Tx_MAC_Tx: accessed-variable=pp_SR_TxMAC_Tx.MAC_Tx
              DWA_pp_SR_TxOdometer_Odometer: accessed-variable=pp_SR_TxOdometer.Odometer
              DWA_pp_SR_TxSecureTxByte{0..3}_SecureTxByte{0..3}: accessed-variable=pp_SR_TxSecureTxByte{0..3}.SecureTxByte{0..3}
              DWA_pp_SR_TxVehicleSpeedIC_VehicleSpeedIC: accessed-variable=pp_SR_TxVehicleSpeedIC.VehicleSpeedIC
        CComAbsMdl_Impl_TxCanMdlMainFunction
        CComAbsMdl_OnDataRx_DayNightMode
        CComAbsMdl_OnDataRx_PowerMode
        CComAbsMdl_OnDataRx_VehicleSpeedABS
        CComAbsMdl_OnDataTx_Battery_Voltage
        CComAbsMdl_OnDataTx_Debug{1..5}_Byte0
        CComAbsMdl_OnDataTx_Illumination_PWM
        CComAbsMdl_OnDataTx_Odometer
        CComAbsMdl_OnDataTx_SecureTxByte0
        CComAbsMdl_OnDataTx_VehicleSpeedIC
        CComAbsMdl_RxCan_GetSignalValue
        CComAbsMdl_RxCan_GetSignalValueU8Arr
        CComAbsMdl_RxCan_SetSignalInitValue
        CComAbsMdl_RxCan_SetSignalInitValueU8Arr
        CComAbsMdl_RxCan_SignalClearJustRcvdStatus
        CComAbsMdl_RxCan_SignalGetJustRcvdStatus
        CComAbsMdl_RxCan_SignalInvalidProcessingControl
        CComAbsMdl_RxCan_SignalMissingProcessingControl
        CComAbsMdl_RxCan_SignalNRProcessingControl
        CComAbsMdl_TxCan_ClearCanSignalTxConfirmation
        CComAbsMdl_TxCan_GetCanSignalTxConfirmation
        CComAbsMdl_TxCan_SetSignalFromRetentionBuffer
        CComAbsMdl_TxCan_SetSignalValue
        CComAbsMdl_TxCan_SetSignalValueU8Arr
  65 x constant specification:
    CComAbsMdlBattery_VoltageValue0: value-spec=CComAbsMdlBattery_VoltageValue0:0
    CComAbsMdlDebug1_Byte{0..7}Value0: value-spec=CComAbsMdlDebug1_Byte{0..7}Value0:0
    CComAbsMdlDebug2_Byte{0..7}Value0: value-spec=CComAbsMdlDebug2_Byte{0..7}Value0:0
    CComAbsMdlDebug3_Byte{0..7}Value0: value-spec=CComAbsMdlDebug3_Byte{0..7}Value0:0
    CComAbsMdlDebug4_Byte{0..7}Value0: value-spec=CComAbsMdlDebug4_Byte{0..7}Value0:0
    CComAbsMdlDebug5_Byte{0..7}Value0: value-spec=CComAbsMdlDebug5_Byte{0..7}Value0:0
    CComAbsMdlFV_TxValue0: value-spec=CComAbsMdlFV_TxValue0:0
    CComAbsMdlIllumination_PWMValue0: value-spec=CComAbsMdlIllumination_PWMValue0:0
    CComAbsMdlMAC_TxValue0: value-spec=CComAbsMdlMAC_TxValue0:0
    CComAbsMdlOdometerValue0: value-spec=CComAbsMdlOdometerValue0:0
    CComAbsMdlSecureTxByte{0..3}Value0: value-spec=CComAbsMdlSecureTxByte{0..3}Value0:0
    CComAbsMdlVehicleSpeedICValue0: value-spec=CComAbsMdlVehicleSpeedICValue0:0
    CComAbsMdlAirbagValue0: value-spec=CComAbsMdlAirbagValue0:0
    CComAbsMdlAlive_101Value0: value-spec=CComAbsMdlAlive_101Value0:0
    CComAbsMdlAmbient_Light_levelValue0: value-spec=CComAbsMdlAmbient_Light_levelValue0:0
    CComAbsMdlCRC_101Value0: value-spec=CComAbsMdlCRC_101Value0:0
    CComAbsMdlDayNightModeValue0: value-spec=CComAbsMdlDayNightModeValue0:0
    CComAbsMdlEngineSpeedValue0: value-spec=CComAbsMdlEngineSpeedValue0:0
    CComAbsMdlGearValue0: value-spec=CComAbsMdlGearValue0:0
    CComAbsMdlGearModeValue0: value-spec=CComAbsMdlGearModeValue0:0
    CComAbsMdlGearRecommendationValue0: value-spec=CComAbsMdlGearRecommendationValue0:0
    CComAbsMdlGearStatusValue0: value-spec=CComAbsMdlGearStatusValue0:0
    CComAbsMdlIllumination_levelValue0: value-spec=CComAbsMdlIllumination_levelValue0:0
    CComAbsMdlPowerModeValue0: value-spec=CComAbsMdlPowerModeValue0:0
    CComAbsMdlTransportModeValue0: value-spec=CComAbsMdlTransportModeValue0:0
    CComAbsMdlVehicleSpeedABSValue0: value-spec=CComAbsMdlVehicleSpeedABSValue0:0
    CComAbsMdlWarningValue0: value-spec=CComAbsMdlWarningValue0:0
  swc implementation IMPL_CComAbsMdl: programming-language=C, behavior=IB_CComAbsMdl
    code-descriptors:
      code CodeDescriptor
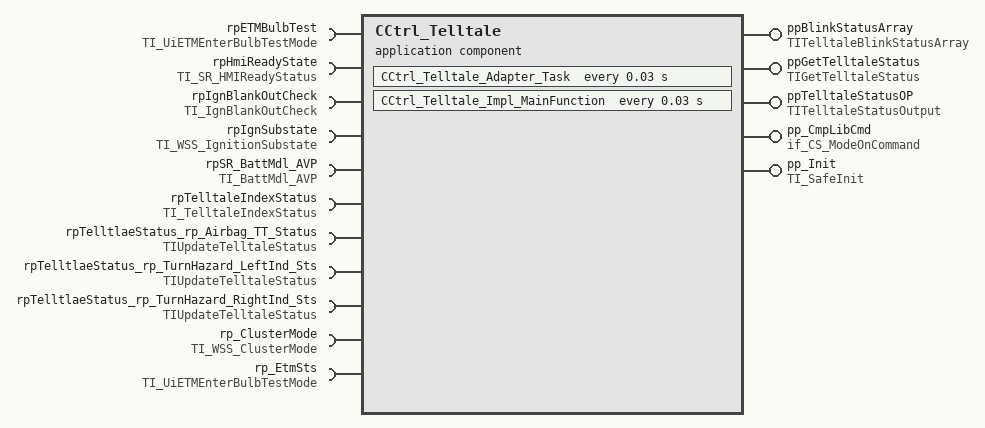
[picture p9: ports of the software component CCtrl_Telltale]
  application sw component type CCtrl_Telltale
    5 x provide port:
      ppBlinkStatusArray: provided-interface=TITelltaleBlinkStatusArray
        provided-com-specs:
          data-element=TTBlinkStatusArray, init-value=constant-reference=CCtrl_TelltaleTTBlinkStatusArrayValue0
          data-element=TTdummyDataForTypes, init-value=constant-reference=CCtrl_TelltaleTTdummyDataForTypesValue0
      ppGetTelltaleStatus: nonqueued-sender-com-spec{data-element=TelltaleFunctionalOpStatus, init-value=constant-reference=CCtrl_TelltaleTelltaleFunctionalOpStatusValue0}, provided-interface=TIGetTelltaleStatus
      ppTelltaleStatusOP: nonqueued-sender-com-spec{data-element=TelltaleOpArray, init-value=constant-reference=CCtrl_TelltaleTelltaleOpArrayValue0}, provided-interface=TITelltaleStatusOutput
      pp_CmpLibCmd: server-com-spec{operation=Impl_OnCommand, queue-length=1}, provided-interface=if_CS_ModeOnCommand
      pp_Init: server-com-spec{operation=TI_SafeInit/Init, queue-length=1}, provided-interface=TI_SafeInit
    11 x require port:
      rpETMBulbTest: nonqueued-receiver-com-spec{data-element=CurrentBulbTestStatus, init-value=constant-reference=CCtrl_TelltaleCurrentBulbTestStatusValue0}, required-interface=TI_UiETMEnterBulbTestMode
      rpHmiReadyState: nonqueued-receiver-com-spec{data-element=HMI_ReadyStatus, init-value=constant-reference=CCtrl_TelltaleHMI_ReadyStatusValue0}, required-interface=TI_SR_HMIReadyStatus
      rpIgnBlankOutCheck: nonqueued-receiver-com-spec{data-element=IgnBlankOutCheck, init-value=constant-reference=CCtrl_TelltaleIgnBlankOutCheckValue0}, required-interface=TI_IgnBlankOutCheck
      rpIgnSubstate: nonqueued-receiver-com-spec{data-element=IgnitionSubstate, init-value=constant-reference=CCtrl_TelltaleIgnitionSubstateValue0}, required-interface=TI_WSS_IgnitionSubstate
      rpSR_BattMdl_AVP: required-interface=TI_BattMdl_AVP
        required-com-specs:
          data-element=HVP0Flag, init-value=constant-reference=CCtrl_TelltaleHVP0FlagValue0
          data-element=HVSD{0..4}Flag, init-value=constant-reference=CCtrl_TelltaleHVSD{0..4}FlagValue0
          data-element=LVP0Flag, init-value=constant-reference=CCtrl_TelltaleLVP0FlagValue0
          data-element=LVP1Flag, init-value=constant-reference=CCtrl_TelltaleLVP1FlagValue0
          data-element=LVSD{0..4}Flag, init-value=constant-reference=CCtrl_TelltaleLVSD{0..4}FlagValue0
          data-element=SVPFlag, init-value=constant-reference=CCtrl_TelltaleSVPFlagValue0
      rpTelltaleIndexStatus: required-interface=TI_TelltaleIndexStatus
        required-com-specs:
          data-element=TTIndex, init-value=constant-reference=CCtrl_TelltaleTTIndexValue0
          data-element=TTStatus, init-value=constant-reference=CCtrl_TelltaleTTStatusValue0
      rpTelltlaeStatus_rp_Airbag_TT_Status: nonqueued-receiver-com-spec{data-element=CurrentTelltaleStatus, init-value=constant-reference=CCtrl_TelltaleCurrentTelltaleStatusValue0}, required-interface=TIUpdateTelltaleStatus
      rpTelltlaeStatus_rp_TurnHazard_LeftInd_Sts: nonqueued-receiver-com-spec{data-element=CurrentTelltaleStatus, init-value=constant-reference=CCtrl_TelltaleCurrentTelltaleStatusValue0}, required-interface=TIUpdateTelltaleStatus
      rpTelltlaeStatus_rp_TurnHazard_RightInd_Sts: nonqueued-receiver-com-spec{data-element=CurrentTelltaleStatus, init-value=constant-reference=CCtrl_TelltaleCurrentTelltaleStatusValue0}, required-interface=TIUpdateTelltaleStatus
      rp_ClusterMode: nonqueued-receiver-com-spec{data-element=WSSCurrentClusterMode, init-value=constant-reference=CCtrl_TelltaleWSSCurrentClusterModeValue0}, required-interface=TI_WSS_ClusterMode
      rp_EtmSts: nonqueued-receiver-com-spec{data-element=CurrentBulbTestStatus, init-value=constant-reference=CCtrl_TelltaleCurrentBulbTestStatusValue0}, required-interface=TI_UiETMEnterBulbTestMode
    behavior IB_CCtrl_Telltale
      timing event TECCtrl_Telltale_Adapter_Task: start-on-event=CCtrl_Telltale_Adapter_Task, period=0.03
      timing event TECCtrl_Telltale_Impl_MainFunction: start-on-event=CCtrl_Telltale_Impl_MainFunction, period=0.03
      operation invoked event OIE_pp_CmpLibCmd_CCtrl_Telltale_Impl_OnCommandTrigByImpl_OnCommand: start-on-event=CCtrl_Telltale_Impl_OnCommand, operation=pp_CmpLibCmd.Impl_OnCommand
      operation invoked event OIE_pp_Init_CCtrl_Telltale_InitTrigByInit: start-on-event=CCtrl_Telltale_Init, operation=pp_Init.Init
      port-api-options:
        enable-take-address=false, indirect-api=false, port=ppBlinkStatusArray
        enable-take-address=false, indirect-api=false, port=ppGetTelltaleStatus
        enable-take-address=false, indirect-api=false, port=ppTelltaleStatusOP
        enable-take-address=false, indirect-api=false, port=CCtrl_Telltale/pp_CmpLibCmd
        enable-take-address=false, indirect-api=false, port=CCtrl_Telltale/pp_Init
        enable-take-address=false, indirect-api=false, port=rpETMBulbTest
        enable-take-address=false, indirect-api=false, port=rpHmiReadyState
        enable-take-address=false, indirect-api=false, port=rpIgnBlankOutCheck
        enable-take-address=false, indirect-api=false, port=CCtrl_Telltale/rpIgnSubstate
        enable-take-address=false, indirect-api=false, port=rpSR_BattMdl_AVP
        enable-take-address=false, indirect-api=false, port=rpTelltaleIndexStatus
        enable-take-address=false, indirect-api=false, port=CCtrl_Telltale/rpTelltlaeStatus_rp_Airbag_TT_Status
        enable-take-address=false, indirect-api=false, port=CCtrl_Telltale/rpTelltlaeStatus_rp_TurnHazard_LeftInd_Sts
        enable-take-address=false, indirect-api=false, port=CCtrl_Telltale/rpTelltlaeStatus_rp_TurnHazard_RightInd_Sts
        enable-take-address=false, indirect-api=false, port=CCtrl_Telltale/rp_ClusterMode
        enable-take-address=false, indirect-api=false, port=rp_EtmSts
      4 x runnable, all with can-be-invoked-concurrently=true:
        CCtrl_Telltale_Adapter_Task
          data-receive-point-by-arguments:
            25 x access:
              DRA_rpETMBulbTest_CurrentBulbTestStatus: accessed-variable=rpETMBulbTest.CurrentBulbTestStatus
              DRA_rpHmiReadyState_HMI_ReadyStatus: accessed-variable=rpHmiReadyState.HMI_ReadyStatus
              DRA_rpIgnBlankOutCheck_IgnBlankOutCheck: accessed-variable=rpIgnBlankOutCheck.IgnBlankOutCheck
              DRA_rpIgnSubstate_IgnitionSubstate: accessed-variable=rpIgnSubstate.IgnitionSubstate
              DRA_rpSR_BattMdl_AVP_HVP0Flag: accessed-variable=rpSR_BattMdl_AVP.HVP0Flag
              DRA_rpSR_BattMdl_AVP_HVSD{0..4}Flag: accessed-variable=rpSR_BattMdl_AVP.HVSD{0..4}Flag
              DRA_rpSR_BattMdl_AVP_LVP0Flag: accessed-variable=rpSR_BattMdl_AVP.LVP0Flag
              DRA_rpSR_BattMdl_AVP_LVP1Flag: accessed-variable=rpSR_BattMdl_AVP.LVP1Flag
              DRA_rpSR_BattMdl_AVP_LVSD{0..4}Flag: accessed-variable=rpSR_BattMdl_AVP.LVSD{0..4}Flag
              DRA_rpSR_BattMdl_AVP_SVPFlag: accessed-variable=rpSR_BattMdl_AVP.SVPFlag
              DRA_rpTelltaleIndexStatus_TTIndex: accessed-variable=rpTelltaleIndexStatus.TTIndex
              DRA_rpTelltaleIndexStatus_TTStatus: accessed-variable=rpTelltaleIndexStatus.TTStatus
              DRA_rpTelltlaeStatus_rp_Airbag_TT_Status_CurrentTelltaleStatus: accessed-variable=rpTelltlaeStatus_rp_Airbag_TT_Status.CurrentTelltaleStatus
              DRA_rpTelltlaeStatus_rp_TurnHazard_LeftInd_Sts_CurrentTelltaleStatus: accessed-variable=rpTelltlaeStatus_rp_TurnHazard_LeftInd_Sts.CurrentTelltaleStatus
              DRA_rpTelltlaeStatus_rp_TurnHazard_RightInd_Sts_CurrentTelltaleStatus: accessed-variable=rpTelltlaeStatus_rp_TurnHazard_RightInd_Sts.CurrentTelltaleStatus
              DRA_rp_ClusterMode_WSSCurrentClusterMode: accessed-variable=rp_ClusterMode.WSSCurrentClusterMode
              DRA_rp_EtmSts_CurrentBulbTestStatus: accessed-variable=rp_EtmSts.CurrentBulbTestStatus
          data-send-points:
            4 x access:
              DWA_ppBlinkStatusArray_TTBlinkStatusArray: accessed-variable=ppBlinkStatusArray.TTBlinkStatusArray
              DWA_ppBlinkStatusArray_TTdummyDataForTypes: accessed-variable=ppBlinkStatusArray.TTdummyDataForTypes
              DWA_ppGetTelltaleStatus_TelltaleFunctionalOpStatus: accessed-variable=ppGetTelltaleStatus.TelltaleFunctionalOpStatus
              DWA_ppTelltaleStatusOP_TelltaleOpArray: accessed-variable=ppTelltaleStatusOP.TelltaleOpArray
        CCtrl_Telltale_Impl_MainFunction
          data-receive-point-by-arguments:
            25 x access:
              DRA_rpETMBulbTest_CurrentBulbTestStatus: accessed-variable=rpETMBulbTest.CurrentBulbTestStatus
              DRA_rpHmiReadyState_HMI_ReadyStatus: accessed-variable=rpHmiReadyState.HMI_ReadyStatus
              DRA_rpIgnBlankOutCheck_IgnBlankOutCheck: accessed-variable=rpIgnBlankOutCheck.IgnBlankOutCheck
              DRA_rpIgnSubstate_IgnitionSubstate: accessed-variable=rpIgnSubstate.IgnitionSubstate
              DRA_rpSR_BattMdl_AVP_HVP0Flag: accessed-variable=rpSR_BattMdl_AVP.HVP0Flag
              DRA_rpSR_BattMdl_AVP_HVSD{0..4}Flag: accessed-variable=rpSR_BattMdl_AVP.HVSD{0..4}Flag
              DRA_rpSR_BattMdl_AVP_LVP0Flag: accessed-variable=rpSR_BattMdl_AVP.LVP0Flag
              DRA_rpSR_BattMdl_AVP_LVP1Flag: accessed-variable=rpSR_BattMdl_AVP.LVP1Flag
              DRA_rpSR_BattMdl_AVP_LVSD{0..4}Flag: accessed-variable=rpSR_BattMdl_AVP.LVSD{0..4}Flag
              DRA_rpSR_BattMdl_AVP_SVPFlag: accessed-variable=rpSR_BattMdl_AVP.SVPFlag
              DRA_rpTelltaleIndexStatus_TTIndex: accessed-variable=rpTelltaleIndexStatus.TTIndex
              DRA_rpTelltaleIndexStatus_TTStatus: accessed-variable=rpTelltaleIndexStatus.TTStatus
              DRA_rpTelltlaeStatus_rp_Airbag_TT_Status_CurrentTelltaleStatus: accessed-variable=rpTelltlaeStatus_rp_Airbag_TT_Status.CurrentTelltaleStatus
              DRA_rpTelltlaeStatus_rp_TurnHazard_LeftInd_Sts_CurrentTelltaleStatus: accessed-variable=rpTelltlaeStatus_rp_TurnHazard_LeftInd_Sts.CurrentTelltaleStatus
              DRA_rpTelltlaeStatus_rp_TurnHazard_RightInd_Sts_CurrentTelltaleStatus: accessed-variable=rpTelltlaeStatus_rp_TurnHazard_RightInd_Sts.CurrentTelltaleStatus
              DRA_rp_ClusterMode_WSSCurrentClusterMode: accessed-variable=rp_ClusterMode.WSSCurrentClusterMode
              DRA_rp_EtmSts_CurrentBulbTestStatus: accessed-variable=rp_EtmSts.CurrentBulbTestStatus
          data-send-points:
            4 x access:
              DWA_ppBlinkStatusArray_TTBlinkStatusArray: accessed-variable=ppBlinkStatusArray.TTBlinkStatusArray
              DWA_ppBlinkStatusArray_TTdummyDataForTypes: accessed-variable=ppBlinkStatusArray.TTdummyDataForTypes
              DWA_ppGetTelltaleStatus_TelltaleFunctionalOpStatus: accessed-variable=ppGetTelltaleStatus.TelltaleFunctionalOpStatus
              DWA_ppTelltaleStatusOP_TelltaleOpArray: accessed-variable=ppTelltaleStatusOP.TelltaleOpArray
        CCtrl_Telltale_Impl_OnCommand
        CCtrl_Telltale_Init
  26 x constant specification:
    CCtrl_TelltaleTTBlinkStatusArrayValue0: value-spec=CCtrl_TelltaleTTBlinkStatusArrayValue0:[CCtrl_TelltaleTTBlinkStatusArray0Value:0, CCtrl_TelltaleTTBlinkStatusArray1Value:0, CCtrl_TelltaleTTBlinkStatusArray2Value:0, CCtrl_TelltaleTTBlinkStatusArray3Value:0, CCtrl_TelltaleTTBlinkStatusArray4Value:0, CCtrl_TelltaleTTBlinkStatusArray5Value:0, CCtrl_TelltaleTTBlinkStatusArray6Value:0, CCtrl_TelltaleTTBlinkStatusArray7Value:0, CCtrl_TelltaleTTBlinkStatusArray8Value:0, CCtrl_TelltaleTTBlinkStatusArray9Value:0, CCtrl_TelltaleTTBlinkStatusArray10Value:0, CCtrl_TelltaleTTBlinkStatusArray11Value:0, CCtrl_TelltaleTTBlinkStatusArray12Value:0, CCtrl_TelltaleTTBlinkStatusArray13Value:0, CCtrl_TelltaleTTBlinkStatusArray14Value:0, CCtrl_TelltaleTTBlinkStatusArray15Value:0]
    CCtrl_TelltaleTTdummyDataForTypesValue0: value-spec=CCtrl_TelltaleTTdummyDataForTypesValue0:0
    CCtrl_TelltaleTelltaleFunctionalOpStatusValue0: value-spec=CCtrl_TelltaleTelltaleFunctionalOpStatusValue0:[CCtrl_TelltaleTelltaleFunctionalOpStatus0Value:0, CCtrl_TelltaleTelltaleFunctionalOpStatus1Value:0, CCtrl_TelltaleTelltaleFunctionalOpStatus2Value:0, CCtrl_TelltaleTelltaleFunctionalOpStatus3Value:0, CCtrl_TelltaleTelltaleFunctionalOpStatus4Value:0, CCtrl_TelltaleTelltaleFunctionalOpStatus5Value:0, CCtrl_TelltaleTelltaleFunctionalOpStatus6Value:0, CCtrl_TelltaleTelltaleFunctionalOpStatus7Value:0, CCtrl_TelltaleTelltaleFunctionalOpStatus8Value:0, CCtrl_TelltaleTelltaleFunctionalOpStatus9Value:0, CCtrl_TelltaleTelltaleFunctionalOpStatus10Value:0, CCtrl_TelltaleTelltaleFunctionalOpStatus11Value:0, CCtrl_TelltaleTelltaleFunctionalOpStatus12Value:0, CCtrl_TelltaleTelltaleFunctionalOpStatus13Value:0, CCtrl_TelltaleTelltaleFunctionalOpStatus14Value:0, CCtrl_TelltaleTelltaleFunctionalOpStatus15Value:0, CCtrl_TelltaleTelltaleFunctionalOpStatus16Value:0, CCtrl_TelltaleTelltaleFunctionalOpStatus17Value:0, CCtrl_TelltaleTelltaleFunctionalOpStatus18Value:0, CCtrl_TelltaleTelltaleFunctionalOpStatus19Value:0, CCtrl_TelltaleTelltaleFunctionalOpStatus20Value:0, CCtrl_TelltaleTelltaleFunctionalOpStatus21Value:0, CCtrl_TelltaleTelltaleFunctionalOpStatus22Value:0, CCtrl_TelltaleTelltaleFunctionalOpStatus23Value:0, CCtrl_TelltaleTelltaleFunctionalOpStatus24Value:0, CCtrl_TelltaleTelltaleFunctionalOpStatus25Value:0, CCtrl_TelltaleTelltaleFunctionalOpStatus26Value:0, CCtrl_TelltaleTelltaleFunctionalOpStatus27Value:0, CCtrl_TelltaleTelltaleFunctionalOpStatus28Value:0, CCtrl_TelltaleTelltaleFunctionalOpStatus29Value:0, CCtrl_TelltaleTelltaleFunctionalOpStatus30Value:0, CCtrl_TelltaleTelltaleFunctionalOpStatus31Value:0, CCtrl_TelltaleTelltaleFunctionalOpStatus32Value:0, CCtrl_TelltaleTelltaleFunctionalOpStatus33Value:0, CCtrl_TelltaleTelltaleFunctionalOpStatus34Value:0, CCtrl_TelltaleTelltaleFunctionalOpStatus35Value:0, CCtrl_TelltaleTelltaleFunctionalOpStatus36Value:0, CCtrl_TelltaleTelltaleFunctionalOpStatus37Value:0, CCtrl_TelltaleTelltaleFunctionalOpStatus38Value:0, CCtrl_TelltaleTelltaleFunctionalOpStatus39Value:0, CCtrl_TelltaleTelltaleFunctionalOpStatus40Value:0, CCtrl_TelltaleTelltaleFunctionalOpStatus41Value:0, CCtrl_TelltaleTelltaleFunctionalOpStatus42Value:0, CCtrl_TelltaleTelltaleFunctionalOpStatus43Value:0, CCtrl_TelltaleTelltaleFunctionalOpStatus44Value:0, CCtrl_TelltaleTelltaleFunctionalOpStatus45Value:0, CCtrl_TelltaleTelltaleFunctionalOpStatus46Value:0, CCtrl_TelltaleTelltaleFunctionalOpStatus47Value:0, CCtrl_TelltaleTelltaleFunctionalOpStatus48Value:0, CCtrl_TelltaleTelltaleFunctionalOpStatus49Value:0, CCtrl_TelltaleTelltaleFunctionalOpStatus50Value:0, CCtrl_TelltaleTelltaleFunctionalOpStatus51Value:0, CCtrl_TelltaleTelltaleFunctionalOpStatus52Value:0, CCtrl_TelltaleTelltaleFunctionalOpStatus53Value:0, CCtrl_TelltaleTelltaleFunctionalOpStatus54Value:0, CCtrl_TelltaleTelltaleFunctionalOpStatus55Value:0, CCtrl_TelltaleTelltaleFunctionalOpStatus56Value:0, CCtrl_TelltaleTelltaleFunctionalOpStatus57Value:0, CCtrl_TelltaleTelltaleFunctionalOpStatus58Value:0, CCtrl_TelltaleTelltaleFunctionalOpStatus59Value:0, CCtrl_TelltaleTelltaleFunctionalOpStatus60Value:0, CCtrl_TelltaleTelltaleFunctionalOpStatus61Value:0, CCtrl_TelltaleTelltaleFunctionalOpStatus62Value:0, CCtrl_TelltaleTelltaleFunctionalOpStatus63Value:0, CCtrl_TelltaleTelltaleFunctionalOpStatus64Value:0, CCtrl_TelltaleTelltaleFunctionalOpStatus65Value:0, CCtrl_TelltaleTelltaleFunctionalOpStatus66Value:0, CCtrl_TelltaleTelltaleFunctionalOpStatus67Value:0, CCtrl_TelltaleTelltaleFunctionalOpStatus68Value:0, CCtrl_TelltaleTelltaleFunctionalOpStatus69Value:0, CCtrl_TelltaleTelltaleFunctionalOpStatus70Value:0, CCtrl_TelltaleTelltaleFunctionalOpStatus71Value:0, CCtrl_TelltaleTelltaleFunctionalOpStatus72Value:0, CCtrl_TelltaleTelltaleFunctionalOpStatus73Value:0, CCtrl_TelltaleTelltaleFunctionalOpStatus74Value:0, CCtrl_TelltaleTelltaleFunctionalOpStatus75Value:0, CCtrl_TelltaleTelltaleFunctionalOpStatus76Value:0, CCtrl_TelltaleTelltaleFunctionalOpStatus77Value:0, CCtrl_TelltaleTelltaleFunctionalOpStatus78Value:0, CCtrl_TelltaleTelltaleFunctionalOpStatus79Value:0, CCtrl_TelltaleTelltaleFunctionalOpStatus80Value:0, CCtrl_TelltaleTelltaleFunctionalOpStatus81Value:0, CCtrl_TelltaleTelltaleFunctionalOpStatus82Value:0, CCtrl_TelltaleTelltaleFunctionalOpStatus83Value:0, CCtrl_TelltaleTelltaleFunctionalOpStatus84Value:0, CCtrl_TelltaleTelltaleFunctionalOpStatus85Value:0, CCtrl_TelltaleTelltaleFunctionalOpStatus86Value:0, CCtrl_TelltaleTelltaleFunctionalOpStatus87Value:0, CCtrl_TelltaleTelltaleFunctionalOpStatus88Value:0, CCtrl_TelltaleTelltaleFunctionalOpStatus89Value:0, CCtrl_TelltaleTelltaleFunctionalOpStatus90Value:0, CCtrl_TelltaleTelltaleFunctionalOpStatus91Value:0]
    CCtrl_TelltaleTelltaleOpArrayValue0: value-spec=CCtrl_TelltaleTelltaleOpArrayValue0:[CCtrl_TelltaleTelltaleOpArray0Value:0, CCtrl_TelltaleTelltaleOpArray1Value:0, CCtrl_TelltaleTelltaleOpArray2Value:0, CCtrl_TelltaleTelltaleOpArray3Value:0, CCtrl_TelltaleTelltaleOpArray4Value:0, CCtrl_TelltaleTelltaleOpArray5Value:0, CCtrl_TelltaleTelltaleOpArray6Value:0, CCtrl_TelltaleTelltaleOpArray7Value:0, CCtrl_TelltaleTelltaleOpArray8Value:0, CCtrl_TelltaleTelltaleOpArray9Value:0, CCtrl_TelltaleTelltaleOpArray10Value:0, CCtrl_TelltaleTelltaleOpArray11Value:0, CCtrl_TelltaleTelltaleOpArray12Value:0, CCtrl_TelltaleTelltaleOpArray13Value:0, CCtrl_TelltaleTelltaleOpArray14Value:0, CCtrl_TelltaleTelltaleOpArray15Value:0, CCtrl_TelltaleTelltaleOpArray16Value:0, CCtrl_TelltaleTelltaleOpArray17Value:0, CCtrl_TelltaleTelltaleOpArray18Value:0, CCtrl_TelltaleTelltaleOpArray19Value:0, CCtrl_TelltaleTelltaleOpArray20Value:0, CCtrl_TelltaleTelltaleOpArray21Value:0, CCtrl_TelltaleTelltaleOpArray22Value:0, CCtrl_TelltaleTelltaleOpArray23Value:0, CCtrl_TelltaleTelltaleOpArray24Value:0, CCtrl_TelltaleTelltaleOpArray25Value:0, CCtrl_TelltaleTelltaleOpArray26Value:0, CCtrl_TelltaleTelltaleOpArray27Value:0, CCtrl_TelltaleTelltaleOpArray28Value:0, CCtrl_TelltaleTelltaleOpArray29Value:0, CCtrl_TelltaleTelltaleOpArray30Value:0, CCtrl_TelltaleTelltaleOpArray31Value:0, CCtrl_TelltaleTelltaleOpArray32Value:0, CCtrl_TelltaleTelltaleOpArray33Value:0, CCtrl_TelltaleTelltaleOpArray34Value:0, CCtrl_TelltaleTelltaleOpArray35Value:0, CCtrl_TelltaleTelltaleOpArray36Value:0, CCtrl_TelltaleTelltaleOpArray37Value:0, CCtrl_TelltaleTelltaleOpArray38Value:0, CCtrl_TelltaleTelltaleOpArray39Value:0, CCtrl_TelltaleTelltaleOpArray40Value:0, CCtrl_TelltaleTelltaleOpArray41Value:0, CCtrl_TelltaleTelltaleOpArray42Value:0, CCtrl_TelltaleTelltaleOpArray43Value:0, CCtrl_TelltaleTelltaleOpArray44Value:0, CCtrl_TelltaleTelltaleOpArray45Value:0, CCtrl_TelltaleTelltaleOpArray46Value:0, CCtrl_TelltaleTelltaleOpArray47Value:0, CCtrl_TelltaleTelltaleOpArray48Value:0, CCtrl_TelltaleTelltaleOpArray49Value:0, CCtrl_TelltaleTelltaleOpArray50Value:0, CCtrl_TelltaleTelltaleOpArray51Value:0, CCtrl_TelltaleTelltaleOpArray52Value:0, CCtrl_TelltaleTelltaleOpArray53Value:0, CCtrl_TelltaleTelltaleOpArray54Value:0, CCtrl_TelltaleTelltaleOpArray55Value:0, CCtrl_TelltaleTelltaleOpArray56Value:0, CCtrl_TelltaleTelltaleOpArray57Value:0, CCtrl_TelltaleTelltaleOpArray58Value:0, CCtrl_TelltaleTelltaleOpArray59Value:0, CCtrl_TelltaleTelltaleOpArray60Value:0, CCtrl_TelltaleTelltaleOpArray61Value:0, CCtrl_TelltaleTelltaleOpArray62Value:0, CCtrl_TelltaleTelltaleOpArray63Value:0, CCtrl_TelltaleTelltaleOpArray64Value:0, CCtrl_TelltaleTelltaleOpArray65Value:0, CCtrl_TelltaleTelltaleOpArray66Value:0, CCtrl_TelltaleTelltaleOpArray67Value:0, CCtrl_TelltaleTelltaleOpArray68Value:0, CCtrl_TelltaleTelltaleOpArray69Value:0, CCtrl_TelltaleTelltaleOpArray70Value:0, CCtrl_TelltaleTelltaleOpArray71Value:0, CCtrl_TelltaleTelltaleOpArray72Value:0, CCtrl_TelltaleTelltaleOpArray73Value:0, CCtrl_TelltaleTelltaleOpArray74Value:0, CCtrl_TelltaleTelltaleOpArray75Value:0, CCtrl_TelltaleTelltaleOpArray76Value:0, CCtrl_TelltaleTelltaleOpArray77Value:0, CCtrl_TelltaleTelltaleOpArray78Value:0, CCtrl_TelltaleTelltaleOpArray79Value:0, CCtrl_TelltaleTelltaleOpArray80Value:0, CCtrl_TelltaleTelltaleOpArray81Value:0, CCtrl_TelltaleTelltaleOpArray82Value:0, CCtrl_TelltaleTelltaleOpArray83Value:0, CCtrl_TelltaleTelltaleOpArray84Value:0, CCtrl_TelltaleTelltaleOpArray85Value:0, CCtrl_TelltaleTelltaleOpArray86Value:0, CCtrl_TelltaleTelltaleOpArray87Value:0, CCtrl_TelltaleTelltaleOpArray88Value:0, CCtrl_TelltaleTelltaleOpArray89Value:0, CCtrl_TelltaleTelltaleOpArray90Value:0, CCtrl_TelltaleTelltaleOpArray91Value:0]
    CCtrl_TelltaleCurrentBulbTestStatusValue0: value-spec=CCtrl_TelltaleCurrentBulbTestStatusValue0:0
    CCtrl_TelltaleHMI_ReadyStatusValue0: value-spec=CCtrl_TelltaleHMI_ReadyStatusValue0:0
    CCtrl_TelltaleIgnBlankOutCheckValue0: value-spec=CCtrl_TelltaleIgnBlankOutCheckValue0:0
    CCtrl_TelltaleIgnitionSubstateValue0: value-spec=CCtrl_TelltaleIgnitionSubstateValue0:0
    CCtrl_TelltaleHVP0FlagValue0: value-spec=CCtrl_TelltaleHVP0FlagValue0:false
    CCtrl_TelltaleHVSD{0..4}FlagValue0: value-spec=CCtrl_TelltaleHVSD{0..4}FlagValue0:false
    CCtrl_TelltaleLVP0FlagValue0: value-spec=CCtrl_TelltaleLVP0FlagValue0:false
    CCtrl_TelltaleLVP1FlagValue0: value-spec=CCtrl_TelltaleLVP1FlagValue0:false
    CCtrl_TelltaleLVSD{0..4}FlagValue0: value-spec=CCtrl_TelltaleLVSD{0..4}FlagValue0:false
    CCtrl_TelltaleSVPFlagValue0: value-spec=CCtrl_TelltaleSVPFlagValue0:false
    CCtrl_TelltaleTTIndexValue0: value-spec=CCtrl_TelltaleTTIndexValue0:0
    CCtrl_TelltaleTTStatusValue0: value-spec=CCtrl_TelltaleTTStatusValue0:0
    CCtrl_TelltaleCurrentTelltaleStatusValue0: value-spec=CCtrl_TelltaleCurrentTelltaleStatusValue0:0
    CCtrl_TelltaleWSSCurrentClusterModeValue0: value-spec=CCtrl_TelltaleWSSCurrentClusterModeValue0:0
  swc implementation IMPL_CCtrl_Telltale: programming-language=C, behavior=IB_CCtrl_Telltale
    code-descriptors:
      code CodeDescriptor
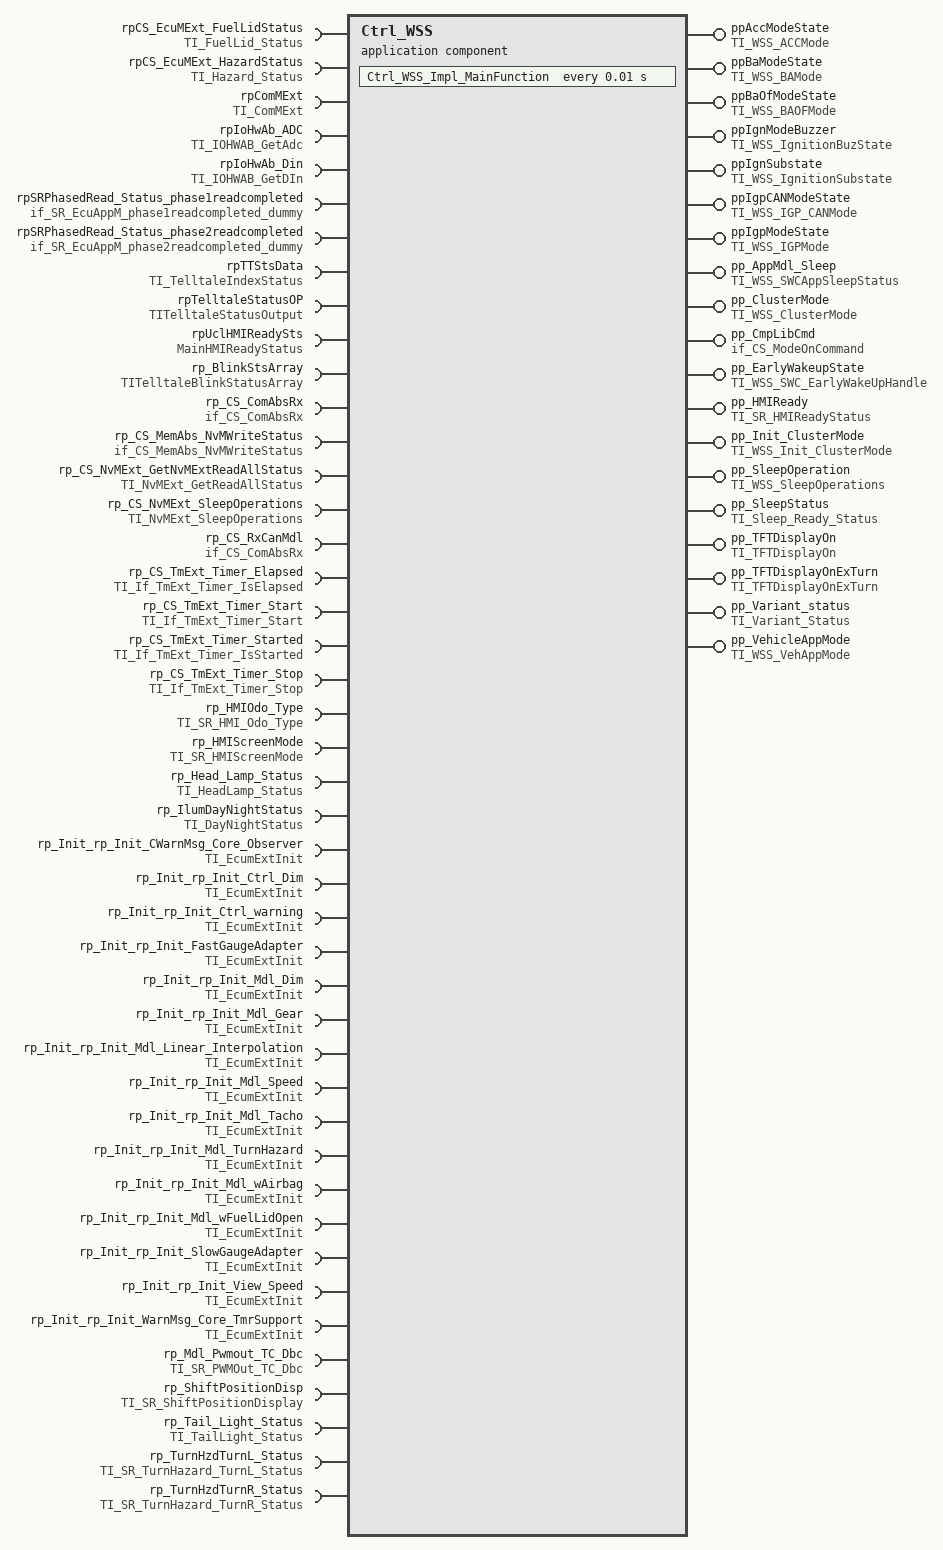
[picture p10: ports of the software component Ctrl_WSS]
  application sw component type Ctrl_WSS
    19 x provide port:
      ppAccModeState: nonqueued-sender-com-spec{data-element=WSSAccState, init-value=constant-reference=Ctrl_WSSWSSAccStateValue0}, provided-interface=TI_WSS_ACCMode
      ppBaModeState: nonqueued-sender-com-spec{data-element=WSSBaState, init-value=constant-reference=Ctrl_WSSWSSBaStateValue0}, provided-interface=TI_WSS_BAMode
      ppBaOfModeState: nonqueued-sender-com-spec{data-element=WSSBaOfState, init-value=constant-reference=Ctrl_WSSWSSBaOfStateValue0}, provided-interface=TI_WSS_BAOFMode
      ppIgnModeBuzzer: nonqueued-sender-com-spec{data-element=IgnitioBuznstate, init-value=constant-reference=Ctrl_WSSIgnitioBuznstateValue0}, provided-interface=TI_WSS_IgnitionBuzState
      ppIgnSubstate: nonqueued-sender-com-spec{data-element=IgnitionSubstate, init-value=constant-reference=Ctrl_WSSIgnitionSubstateValue0}, provided-interface=TI_WSS_IgnitionSubstate
      ppIgpCANModeState: nonqueued-sender-com-spec{data-element=WSSIGPCANState, init-value=constant-reference=Ctrl_WSSWSSIGPCANStateValue0}, provided-interface=TI_WSS_IGP_CANMode
      ppIgpModeState: nonqueued-sender-com-spec{data-element=WSSIGPState, init-value=constant-reference=Ctrl_WSSWSSIGPStateValue0}, provided-interface=TI_WSS_IGPMode
      pp_AppMdl_Sleep: server-com-spec{operation=SWCSleepStatus, queue-length=1}, provided-interface=TI_WSS_SWCAppSleepStatus
      pp_ClusterMode: nonqueued-sender-com-spec{data-element=WSSCurrentClusterMode, init-value=constant-reference=Ctrl_WSSWSSCurrentClusterModeValue0}, provided-interface=TI_WSS_ClusterMode
      pp_CmpLibCmd: server-com-spec{operation=Impl_OnCommand, queue-length=1}, provided-interface=if_CS_ModeOnCommand
      pp_EarlyWakeupState: server-com-spec{operation=SWCEarlyWakeUpHandle, queue-length=1}, provided-interface=TI_WSS_SWC_EarlyWakeUpHandle
      pp_HMIReady: nonqueued-sender-com-spec{data-element=HMI_ReadyStatus, init-value=constant-reference=Ctrl_WSSHMI_ReadyStatusValue0}, provided-interface=TI_SR_HMIReadyStatus
      pp_Init_ClusterMode: nonqueued-sender-com-spec{data-element=WSSCurrentClusterInitMode, init-value=constant-reference=Ctrl_WSSWSSCurrentClusterInitModeValue0}, provided-interface=TI_WSS_Init_ClusterMode
      pp_SleepOperation: provided-interface=TI_WSS_SleepOperations
        provided-com-specs:
          operation=CtrlWSS_CancelSleep, queue-length=1
          operation=CtrlWSS_ReadytoSleep, queue-length=1
          operation=CtrlWSS_RequestSleep, queue-length=1
      pp_SleepStatus: nonqueued-sender-com-spec{data-element=Sleep_Status, init-value=constant-reference=Ctrl_WSSSleep_StatusValue0}, provided-interface=TI_Sleep_Ready_Status
      pp_TFTDisplayOn: nonqueued-sender-com-spec{data-element=TFTDisplayOn, init-value=constant-reference=Ctrl_WSSTFTDisplayOnValue0}, provided-interface=TI_TFTDisplayOn
      pp_TFTDisplayOnExTurn: nonqueued-sender-com-spec{data-element=TFTDisplayOnExTurn, init-value=constant-reference=Ctrl_WSSTFTDisplayOnExTurnValue0}, provided-interface=TI_TFTDisplayOnExTurn
      pp_Variant_status: server-com-spec{operation=GetVariant_Status, queue-length=1}, provided-interface=TI_Variant_Status
      pp_VehicleAppMode: nonqueued-sender-com-spec{data-element=WSSCurrentVehicleState, init-value=constant-reference=Ctrl_WSSWSSCurrentVehicleStateValue0}, provided-interface=TI_WSS_VehAppMode
    44 x require port:
      rpCS_EcuMExt_FuelLidStatus: queued-receiver-com-spec{data-element=FuelLidStatus, queue-length=15}, required-interface=TI_FuelLid_Status
      rpCS_EcuMExt_HazardStatus: queued-receiver-com-spec{data-element=HazardStatus, queue-length=15}, required-interface=TI_Hazard_Status
      rpComMExt: required-interface=TI_ComMExt
      rpIoHwAb_ADC: required-interface=TI_IOHWAB_GetAdc
      rpIoHwAb_Din: required-interface=TI_IOHWAB_GetDIn
      rpSRPhasedRead_Status_phase1readcompleted: nonqueued-receiver-com-spec{data-element=PhasedRead_Status_phase1readcompleted, init-value=constant-reference=Ctrl_WSSPhasedRead_Status_phase1readcompletedValue0}, required-interface=if_SR_EcuAppM_phase1readcompleted_dummy
      rpSRPhasedRead_Status_phase2readcompleted: nonqueued-receiver-com-spec{data-element=PhasedRead_Status_phase2readcompleted, init-value=constant-reference=Ctrl_WSSPhasedRead_Status_phase2readcompletedValue0}, required-interface=if_SR_EcuAppM_phase2readcompleted_dummy
      rpTTStsData: required-interface=TI_TelltaleIndexStatus
        required-com-specs:
          data-element=TTIndex, init-value=constant-reference=Ctrl_WSSTTIndexValue0
          data-element=TTStatus, init-value=constant-reference=Ctrl_WSSTTStatusValue0
      rpTelltaleStatusOP: nonqueued-receiver-com-spec{data-element=TelltaleOpArray, init-value=constant-reference=Ctrl_WSSTelltaleOpArrayValue0}, required-interface=TITelltaleStatusOutput
      rpUclHMIReadySts: queued-receiver-com-spec{data-element=MainHMIReadyStatusData, queue-length=5}, required-interface=MainHMIReadyStatus
      rp_BlinkStsArray: required-interface=TITelltaleBlinkStatusArray
        required-com-specs:
          data-element=TTBlinkStatusArray, init-value=constant-reference=Ctrl_WSSTTBlinkStatusArrayValue0
          data-element=TTdummyDataForTypes, init-value=constant-reference=Ctrl_WSSTTdummyDataForTypesValue0
      rp_CS_ComAbsRx: required-interface=if_CS_ComAbsRx
      rp_CS_MemAbs_NvMWriteStatus: required-interface=if_CS_MemAbs_NvMWriteStatus
      rp_CS_NvMExt_GetNvMExtReadAllStatus: required-interface=TI_NvMExt_GetReadAllStatus
      rp_CS_NvMExt_SleepOperations: required-interface=TI_NvMExt_SleepOperations
      rp_CS_RxCanMdl: required-interface=if_CS_ComAbsRx
      rp_CS_TmExt_Timer_Elapsed: required-interface=TI_If_TmExt_Timer_IsElapsed
      rp_CS_TmExt_Timer_Start: required-interface=TI_If_TmExt_Timer_Start
      rp_CS_TmExt_Timer_Started: required-interface=TI_If_TmExt_Timer_IsStarted
      rp_CS_TmExt_Timer_Stop: required-interface=TI_If_TmExt_Timer_Stop
      rp_HMIOdo_Type: nonqueued-receiver-com-spec{data-element=HMI_OdoType, init-value=constant-reference=Ctrl_WSSHMI_OdoTypeValue0}, required-interface=TI_SR_HMI_Odo_Type
      rp_HMIScreenMode: nonqueued-receiver-com-spec{data-element=HMIScreenMode_Status, init-value=constant-reference=Ctrl_WSSHMIScreenMode_StatusValue0}, required-interface=TI_SR_HMIScreenMode
      rp_Head_Lamp_Status: nonqueued-receiver-com-spec{data-element=Head_Lamp_st, init-value=constant-reference=Ctrl_WSSHead_Lamp_stValue0}, required-interface=TI_HeadLamp_Status
      rp_IlumDayNightStatus: nonqueued-receiver-com-spec{data-element=illumDNStatus, init-value=constant-reference=Ctrl_WSSillumDNStatusValue0}, required-interface=TI_DayNightStatus
      rp_Init_rp_Init_CWarnMsg_Core_Observer: required-interface=TI_EcumExtInit
      rp_Init_rp_Init_Ctrl_Dim: required-interface=TI_EcumExtInit
      rp_Init_rp_Init_Ctrl_warning: required-interface=TI_EcumExtInit
      rp_Init_rp_Init_FastGaugeAdapter: required-interface=TI_EcumExtInit
      rp_Init_rp_Init_Mdl_Dim: required-interface=TI_EcumExtInit
      rp_Init_rp_Init_Mdl_Gear: required-interface=TI_EcumExtInit
      rp_Init_rp_Init_Mdl_Linear_Interpolation: required-interface=TI_EcumExtInit
      rp_Init_rp_Init_Mdl_Speed: required-interface=TI_EcumExtInit
      rp_Init_rp_Init_Mdl_Tacho: required-interface=TI_EcumExtInit
      rp_Init_rp_Init_Mdl_TurnHazard: required-interface=TI_EcumExtInit
      rp_Init_rp_Init_Mdl_wAirbag: required-interface=TI_EcumExtInit
      rp_Init_rp_Init_Mdl_wFuelLidOpen: required-interface=TI_EcumExtInit
      rp_Init_rp_Init_SlowGaugeAdapter: required-interface=TI_EcumExtInit
      rp_Init_rp_Init_View_Speed: required-interface=TI_EcumExtInit
      rp_Init_rp_Init_WarnMsg_Core_TmrSupport: required-interface=TI_EcumExtInit
      rp_Mdl_Pwmout_TC_Dbc: nonqueued-receiver-com-spec{data-element=PWMOut_TC_Dbc, init-value=constant-reference=Ctrl_WSSPWMOut_TC_DbcValue0}, required-interface=TI_SR_PWMOut_TC_Dbc
      rp_ShiftPositionDisp: nonqueued-receiver-com-spec{data-element=ShiftPositionDisplay, init-value=constant-reference=Ctrl_WSSShiftPositionDisplayValue0}, required-interface=TI_SR_ShiftPositionDisplay
      rp_Tail_Light_Status: nonqueued-receiver-com-spec{data-element=Tail_Light_st, init-value=constant-reference=Ctrl_WSSTail_Light_stValue0}, required-interface=TI_TailLight_Status
      rp_TurnHzdTurnL_Status: nonqueued-receiver-com-spec{data-element=LeftIndicatorSts, init-value=constant-reference=Ctrl_WSSLeftIndicatorStsValue0}, required-interface=TI_SR_TurnHazard_TurnL_Status
      rp_TurnHzdTurnR_Status: nonqueued-receiver-com-spec{data-element=RightIndicatorSts, init-value=constant-reference=Ctrl_WSSRightIndicatorStsValue0}, required-interface=TI_SR_TurnHazard_TurnR_Status
    behavior IB_Ctrl_WSS
      4 x operation invoked event:
        OIE_pp_SleepOperation_CtrlWSS_CancelSleepTrigByCtrlWSS_CancelSleep: start-on-event=CtrlWSS_CancelSleep, operation=pp_SleepOperation.CtrlWSS_CancelSleep
        OIE_pp_SleepOperation_CtrlWSS_ReadytoSleepTrigByCtrlWSS_ReadytoSleep: start-on-event=CtrlWSS_ReadytoSleep, operation=pp_SleepOperation.CtrlWSS_ReadytoSleep
        OIE_pp_SleepOperation_CtrlWSS_RequestSleepTrigByCtrlWSS_RequestSleep: start-on-event=CtrlWSS_RequestSleep, operation=pp_SleepOperation.CtrlWSS_RequestSleep
        OIE_pp_Variant_status_Ctrl_WSS_GetVariant_StatusTrigByGetVariant_Status: start-on-event=Ctrl_WSS_GetVariant_Status, operation=pp_Variant_status.GetVariant_Status
      timing event TECtrl_WSS_Impl_MainFunction: start-on-event=Ctrl_WSS_Impl_MainFunction, period=0.01
      operation invoked event OIE_pp_CmpLibCmd_Ctrl_WSS_Impl_OnCommandTrigByImpl_OnCommand: start-on-event=Ctrl_WSS_Impl_OnCommand, operation=pp_CmpLibCmd.Impl_OnCommand
      operation invoked event OIE_pp_EarlyWakeupState_Ctrl_WSS_SWCEarlyWakeUpHandleTrigBySWCEarlyWakeUpHandle: start-on-event=Ctrl_WSS_SWCEarlyWakeUpHandle, operation=pp_EarlyWakeupState.SWCEarlyWakeUpHandle
      operation invoked event OIE_pp_AppMdl_Sleep_Ctrl_WSS_SWCSleepStatusTrigBySWCSleepStatus: start-on-event=Ctrl_WSS_SWCSleepStatus, operation=pp_AppMdl_Sleep.SWCSleepStatus
      port-api-options:
        enable-take-address=false, indirect-api=false, port=ppAccModeState
        enable-take-address=false, indirect-api=false, port=ppBaModeState
        enable-take-address=false, indirect-api=false, port=ppBaOfModeState
        enable-take-address=false, indirect-api=false, port=ppIgnModeBuzzer
        enable-take-address=false, indirect-api=false, port=ppIgnSubstate
        enable-take-address=false, indirect-api=false, port=ppIgpCANModeState
        enable-take-address=false, indirect-api=false, port=ppIgpModeState
        enable-take-address=false, indirect-api=false, port=pp_AppMdl_Sleep
        enable-take-address=false, indirect-api=false, port=pp_ClusterMode
        enable-take-address=false, indirect-api=false, port=Ctrl_WSS/pp_CmpLibCmd
        enable-take-address=false, indirect-api=false, port=pp_EarlyWakeupState
        enable-take-address=false, indirect-api=false, port=pp_HMIReady
        enable-take-address=false, indirect-api=false, port=pp_Init_ClusterMode
        enable-take-address=false, indirect-api=false, port=pp_SleepOperation
        enable-take-address=false, indirect-api=false, port=pp_SleepStatus
        enable-take-address=false, indirect-api=false, port=pp_TFTDisplayOn
        enable-take-address=false, indirect-api=false, port=pp_TFTDisplayOnExTurn
        enable-take-address=false, indirect-api=false, port=pp_Variant_status
        enable-take-address=false, indirect-api=false, port=pp_VehicleAppMode
        enable-take-address=false, indirect-api=false, port=rpCS_EcuMExt_FuelLidStatus
        enable-take-address=false, indirect-api=false, port=rpCS_EcuMExt_HazardStatus
        enable-take-address=false, indirect-api=false, port=Ctrl_WSS/rpComMExt
        enable-take-address=false, indirect-api=false, port=Ctrl_WSS/rpIoHwAb_ADC
        enable-take-address=false, indirect-api=false, port=Ctrl_WSS/rpIoHwAb_Din
        enable-take-address=false, indirect-api=false, port=rpSRPhasedRead_Status_phase1readcompleted
        enable-take-address=false, indirect-api=false, port=rpSRPhasedRead_Status_phase2readcompleted
        enable-take-address=false, indirect-api=false, port=rpTTStsData
        enable-take-address=false, indirect-api=false, port=Ctrl_WSS/rpTelltaleStatusOP
        enable-take-address=false, indirect-api=false, port=rpUclHMIReadySts
        enable-take-address=false, indirect-api=false, port=rp_BlinkStsArray
        enable-take-address=false, indirect-api=false, port=rp_CS_ComAbsRx
        enable-take-address=false, indirect-api=false, port=Ctrl_WSS/rp_CS_MemAbs_NvMWriteStatus
        enable-take-address=false, indirect-api=false, port=Ctrl_WSS/rp_CS_NvMExt_GetNvMExtReadAllStatus
        enable-take-address=false, indirect-api=false, port=Ctrl_WSS/rp_CS_NvMExt_SleepOperations
        enable-take-address=false, indirect-api=false, port=Ctrl_WSS/rp_CS_RxCanMdl
        enable-take-address=false, indirect-api=false, port=Ctrl_WSS/rp_CS_TmExt_Timer_Elapsed
        enable-take-address=false, indirect-api=false, port=Ctrl_WSS/rp_CS_TmExt_Timer_Start
        enable-take-address=false, indirect-api=false, port=Ctrl_WSS/rp_CS_TmExt_Timer_Started
        enable-take-address=false, indirect-api=false, port=Ctrl_WSS/rp_CS_TmExt_Timer_Stop
        enable-take-address=false, indirect-api=false, port=rp_HMIOdo_Type
        enable-take-address=false, indirect-api=false, port=Ctrl_WSS/rp_HMIScreenMode
        enable-take-address=false, indirect-api=false, port=rp_Head_Lamp_Status
        enable-take-address=false, indirect-api=false, port=Ctrl_WSS/rp_IlumDayNightStatus
        enable-take-address=false, indirect-api=false, port=rp_Init_rp_Init_CWarnMsg_Core_Observer
        enable-take-address=false, indirect-api=false, port=rp_Init_rp_Init_Ctrl_Dim
        enable-take-address=false, indirect-api=false, port=rp_Init_rp_Init_Ctrl_warning
        enable-take-address=false, indirect-api=false, port=rp_Init_rp_Init_FastGaugeAdapter
        enable-take-address=false, indirect-api=false, port=rp_Init_rp_Init_Mdl_Dim
        enable-take-address=false, indirect-api=false, port=rp_Init_rp_Init_Mdl_Gear
        enable-take-address=false, indirect-api=false, port=rp_Init_rp_Init_Mdl_Linear_Interpolation
        enable-take-address=false, indirect-api=false, port=rp_Init_rp_Init_Mdl_Speed
        enable-take-address=false, indirect-api=false, port=rp_Init_rp_Init_Mdl_Tacho
        enable-take-address=false, indirect-api=false, port=rp_Init_rp_Init_Mdl_TurnHazard
        enable-take-address=false, indirect-api=false, port=rp_Init_rp_Init_Mdl_wAirbag
        enable-take-address=false, indirect-api=false, port=rp_Init_rp_Init_Mdl_wFuelLidOpen
        enable-take-address=false, indirect-api=false, port=rp_Init_rp_Init_SlowGaugeAdapter
        enable-take-address=false, indirect-api=false, port=rp_Init_rp_Init_View_Speed
        enable-take-address=false, indirect-api=false, port=rp_Init_rp_Init_WarnMsg_Core_TmrSupport
        enable-take-address=false, indirect-api=false, port=rp_Mdl_Pwmout_TC_Dbc
        enable-take-address=false, indirect-api=false, port=rp_ShiftPositionDisp
        enable-take-address=false, indirect-api=false, port=rp_Tail_Light_Status
        enable-take-address=false, indirect-api=false, port=rp_TurnHzdTurnL_Status
        enable-take-address=false, indirect-api=false, port=rp_TurnHzdTurnR_Status
      8 x runnable, all with can-be-invoked-concurrently=true:
        CtrlWSS_CancelSleep
        CtrlWSS_ReadytoSleep
        CtrlWSS_RequestSleep
        Ctrl_WSS_GetVariant_Status
        Ctrl_WSS_Impl_MainFunction
          data-receive-point-by-arguments:
            19 x access:
              DRP_rpCS_EcuMExt_FuelLidStatus_FuelLidStatus: accessed-variable=rpCS_EcuMExt_FuelLidStatus.FuelLidStatus
              DRP_rpCS_EcuMExt_HazardStatus_HazardStatus: accessed-variable=rpCS_EcuMExt_HazardStatus.HazardStatus
              DRA_rpSRPhasedRead_Status_phase1readcompleted_PhasedRead_Status_phase1readcompleted: accessed-variable=rpSRPhasedRead_Status_phase1readcompleted.PhasedRead_Status_phase1readcompleted
              DRA_rpSRPhasedRead_Status_phase2readcompleted_PhasedRead_Status_phase2readcompleted: accessed-variable=rpSRPhasedRead_Status_phase2readcompleted.PhasedRead_Status_phase2readcompleted
              DRA_rpTTStsData_TTIndex: accessed-variable=rpTTStsData.TTIndex
              DRA_rpTTStsData_TTStatus: accessed-variable=rpTTStsData.TTStatus
              DRA_rpTelltaleStatusOP_TelltaleOpArray: accessed-variable=rpTelltaleStatusOP.TelltaleOpArray
              DRP_rpUclHMIReadySts_MainHMIReadyStatusData: accessed-variable=rpUclHMIReadySts.MainHMIReadyStatusData
              DRA_rp_BlinkStsArray_TTBlinkStatusArray: accessed-variable=rp_BlinkStsArray.TTBlinkStatusArray
              DRA_rp_BlinkStsArray_TTdummyDataForTypes: accessed-variable=rp_BlinkStsArray.TTdummyDataForTypes
              DRA_rp_HMIOdo_Type_HMI_OdoType: accessed-variable=rp_HMIOdo_Type.HMI_OdoType
              DRA_rp_HMIScreenMode_HMIScreenMode_Status: accessed-variable=rp_HMIScreenMode.HMIScreenMode_Status
              DRA_rp_Head_Lamp_Status_Head_Lamp_st: accessed-variable=rp_Head_Lamp_Status.Head_Lamp_st
              DRA_rp_IlumDayNightStatus_illumDNStatus: accessed-variable=rp_IlumDayNightStatus.illumDNStatus
              DRA_rp_Mdl_Pwmout_TC_Dbc_PWMOut_TC_Dbc: accessed-variable=rp_Mdl_Pwmout_TC_Dbc.PWMOut_TC_Dbc
              DRA_rp_ShiftPositionDisp_ShiftPositionDisplay: accessed-variable=rp_ShiftPositionDisp.ShiftPositionDisplay
              DRA_rp_Tail_Light_Status_Tail_Light_st: accessed-variable=rp_Tail_Light_Status.Tail_Light_st
              DRA_rp_TurnHzdTurnL_Status_LeftIndicatorSts: accessed-variable=rp_TurnHzdTurnL_Status.LeftIndicatorSts
              DRA_rp_TurnHzdTurnR_Status_RightIndicatorSts: accessed-variable=rp_TurnHzdTurnR_Status.RightIndicatorSts
          data-send-points:
            14 x access:
              DWA_ppAccModeState_WSSAccState: accessed-variable=ppAccModeState.WSSAccState
              DWA_ppBaModeState_WSSBaState: accessed-variable=ppBaModeState.WSSBaState
              DWA_ppBaOfModeState_WSSBaOfState: accessed-variable=ppBaOfModeState.WSSBaOfState
              DWA_ppIgnModeBuzzer_IgnitioBuznstate: accessed-variable=ppIgnModeBuzzer.IgnitioBuznstate
              DWA_ppIgnSubstate_IgnitionSubstate: accessed-variable=ppIgnSubstate.IgnitionSubstate
              DWA_ppIgpCANModeState_WSSIGPCANState: accessed-variable=ppIgpCANModeState.WSSIGPCANState
              DWA_ppIgpModeState_WSSIGPState: accessed-variable=ppIgpModeState.WSSIGPState
              DWA_pp_ClusterMode_WSSCurrentClusterMode: accessed-variable=pp_ClusterMode.WSSCurrentClusterMode
              DWA_pp_HMIReady_HMI_ReadyStatus: accessed-variable=pp_HMIReady.HMI_ReadyStatus
              DWA_pp_Init_ClusterMode_WSSCurrentClusterInitMode: accessed-variable=pp_Init_ClusterMode.WSSCurrentClusterInitMode
              DWA_pp_SleepStatus_Sleep_Status: accessed-variable=pp_SleepStatus.Sleep_Status
              DWA_pp_TFTDisplayOn_TFTDisplayOn: accessed-variable=pp_TFTDisplayOn.TFTDisplayOn
              DWA_pp_TFTDisplayOnExTurn_TFTDisplayOnExTurn: accessed-variable=pp_TFTDisplayOnExTurn.TFTDisplayOnExTurn
              DWA_pp_VehicleAppMode_WSSCurrentVehicleState: accessed-variable=pp_VehicleAppMode.WSSCurrentVehicleState
          63 x sync call, all with timeout=0.0:
            OA_rpComMExt_Get_MCAN_ERR_PIN_Status: operation=rpComMExt.Get_MCAN_ERR_PIN_Status
            OA_rpComMExt_Impl_MainFunction: operation=rpComMExt.Impl_MainFunction
            OA_rpComMExt_Init: operation=rpComMExt.Init
            OA_rpComMExt_GetBusOffStatus: operation=rpComMExt.GetBusOffStatus
            OA_rpComMExt_CAN_RequestCommunication: operation=rpComMExt.CAN_RequestCommunication
            OA_rpComMExt_CAN_GetCurrentComMode: operation=rpComMExt.CAN_GetCurrentComMode
            OA_rpComMExt_CAN_ReleaseCommunication: operation=rpComMExt.CAN_ReleaseCommunication
            OA_rpComMExt_CAN_DeActivateSilentCommunication: operation=rpComMExt.CAN_DeActivateSilentCommunication
            OA_rpComMExt_CAN_CommControlSetDone: operation=rpComMExt.CAN_CommControlSetDone
            OA_rpComMExt_CAN_CommControlDeActivateTx: operation=rpComMExt.CAN_CommControlDeActivateTx
            OA_rpComMExt_CAN_CommControlDeActivateRx: operation=rpComMExt.CAN_CommControlDeActivateRx
            OA_rpComMExt_CAN_ActivateSilentCommunication: operation=rpComMExt.CAN_ActivateSilentCommunication
            OA_rpComMExt_CAN_CommControlActivateRx: operation=rpComMExt.CAN_CommControlActivateRx
            OA_rpComMExt_CAN_CommControlActivateTx: operation=rpComMExt.CAN_CommControlActivateTx
            OA_rpIoHwAb_ADC_GetAsyncRawAdc: operation=rpIoHwAb_ADC.GetAsyncRawAdc
            OA_rpIoHwAb_ADC_GetSyncRawAdc: operation=rpIoHwAb_ADC.GetSyncRawAdc
            OA_rpIoHwAb_ADC_GetProcessedAdc: operation=rpIoHwAb_ADC.GetProcessedAdc
            OA_rpIoHwAb_Din_GetAsyncRawInput: operation=rpIoHwAb_Din.GetAsyncRawInput
            OA_rpIoHwAb_Din_GetProcessedInput: operation=rpIoHwAb_Din.GetProcessedInput
            OA_rpIoHwAb_Din_GetSyncRawInput: operation=rpIoHwAb_Din.GetSyncRawInput
            OA_rpIoHwAb_Din_GetInputGroup: operation=rpIoHwAb_Din.GetInputGroup
            OA_rp_CS_ComAbsRx_RxCan_GetSignalValueU8Arr: operation=rp_CS_ComAbsRx.RxCan_GetSignalValueU8Arr
            OA_rp_CS_ComAbsRx_RxCan_SetSignalInitValue: operation=rp_CS_ComAbsRx.RxCan_SetSignalInitValue
            OA_rp_CS_ComAbsRx_RxCan_SetSignalInitValueU8Arr: operation=rp_CS_ComAbsRx.RxCan_SetSignalInitValueU8Arr
            OA_rp_CS_ComAbsRx_RxCan_SignalInvalidProcessingControl: operation=rp_CS_ComAbsRx.RxCan_SignalInvalidProcessingControl
            OA_rp_CS_ComAbsRx_RxCan_SignalMissingProcessingControl: operation=rp_CS_ComAbsRx.RxCan_SignalMissingProcessingControl
            OA_rp_CS_ComAbsRx_RxCan_SignalNRProcessingControl: operation=rp_CS_ComAbsRx.RxCan_SignalNRProcessingControl
            OA_rp_CS_ComAbsRx_RxCan_SignalGetJustRcvdStatus: operation=rp_CS_ComAbsRx.RxCan_SignalGetJustRcvdStatus
            OA_rp_CS_ComAbsRx_RxCan_SignalClearJustRcvdStatus: operation=rp_CS_ComAbsRx.RxCan_SignalClearJustRcvdStatus
            OA_rp_CS_ComAbsRx_RxCan_GetSignalValue: operation=rp_CS_ComAbsRx.RxCan_GetSignalValue
            OA_rp_CS_MemAbs_NvMWriteStatus_NvmWriteStatus: operation=rp_CS_MemAbs_NvMWriteStatus.NvmWriteStatus
            OA_rp_CS_NvMExt_GetNvMExtReadAllStatus_NvmExt_GetNvMReadAllStatus: operation=rp_CS_NvMExt_GetNvMExtReadAllStatus.NvmExt_GetNvMReadAllStatus
            OA_rp_CS_NvMExt_SleepOperations_NvMExt_ReadytoSleep: operation=rp_CS_NvMExt_SleepOperations.NvMExt_ReadytoSleep
            OA_rp_CS_NvMExt_SleepOperations_NvMExt_RequestSleep: operation=rp_CS_NvMExt_SleepOperations.NvMExt_RequestSleep
            OA_rp_CS_NvMExt_SleepOperations_NvMExt_CancelSleep: operation=rp_CS_NvMExt_SleepOperations.NvMExt_CancelSleep
            OA_rp_CS_RxCanMdl_RxCan_GetSignalValueU8Arr: operation=rp_CS_RxCanMdl.RxCan_GetSignalValueU8Arr
            OA_rp_CS_RxCanMdl_RxCan_SetSignalInitValue: operation=rp_CS_RxCanMdl.RxCan_SetSignalInitValue
            OA_rp_CS_RxCanMdl_RxCan_SetSignalInitValueU8Arr: operation=rp_CS_RxCanMdl.RxCan_SetSignalInitValueU8Arr
            OA_rp_CS_RxCanMdl_RxCan_SignalInvalidProcessingControl: operation=rp_CS_RxCanMdl.RxCan_SignalInvalidProcessingControl
            OA_rp_CS_RxCanMdl_RxCan_SignalMissingProcessingControl: operation=rp_CS_RxCanMdl.RxCan_SignalMissingProcessingControl
            OA_rp_CS_RxCanMdl_RxCan_SignalNRProcessingControl: operation=rp_CS_RxCanMdl.RxCan_SignalNRProcessingControl
            OA_rp_CS_RxCanMdl_RxCan_SignalGetJustRcvdStatus: operation=rp_CS_RxCanMdl.RxCan_SignalGetJustRcvdStatus
            OA_rp_CS_RxCanMdl_RxCan_SignalClearJustRcvdStatus: operation=rp_CS_RxCanMdl.RxCan_SignalClearJustRcvdStatus
            OA_rp_CS_RxCanMdl_RxCan_GetSignalValue: operation=rp_CS_RxCanMdl.RxCan_GetSignalValue
            OA_rp_CS_TmExt_Timer_Elapsed_Timer_IsElapsed: operation=rp_CS_TmExt_Timer_Elapsed.Timer_IsElapsed
            OA_rp_CS_TmExt_Timer_Start_Timer_Start: operation=rp_CS_TmExt_Timer_Start.Timer_Start
            OA_rp_CS_TmExt_Timer_Started_Timer_IsStarted: operation=rp_CS_TmExt_Timer_Started.Timer_IsStarted
            OA_rp_CS_TmExt_Timer_Stop_Timer_Stop: operation=rp_CS_TmExt_Timer_Stop.Timer_Stop
            OA_rp_Init_rp_Init_CWarnMsg_Core_Observer_Init: operation=rp_Init_rp_Init_CWarnMsg_Core_Observer.Init
            OA_rp_Init_rp_Init_Ctrl_Dim_Init: operation=rp_Init_rp_Init_Ctrl_Dim.Init
            OA_rp_Init_rp_Init_Ctrl_warning_Init: operation=rp_Init_rp_Init_Ctrl_warning.Init
            OA_rp_Init_rp_Init_FastGaugeAdapter_Init: operation=rp_Init_rp_Init_FastGaugeAdapter.Init
            OA_rp_Init_rp_Init_Mdl_Dim_Init: operation=rp_Init_rp_Init_Mdl_Dim.Init
            OA_rp_Init_rp_Init_Mdl_Gear_Init: operation=rp_Init_rp_Init_Mdl_Gear.Init
            OA_rp_Init_rp_Init_Mdl_Linear_Interpolation_Init: operation=rp_Init_rp_Init_Mdl_Linear_Interpolation.Init
            OA_rp_Init_rp_Init_Mdl_Speed_Init: operation=rp_Init_rp_Init_Mdl_Speed.Init
            OA_rp_Init_rp_Init_Mdl_Tacho_Init: operation=rp_Init_rp_Init_Mdl_Tacho.Init
            OA_rp_Init_rp_Init_Mdl_TurnHazard_Init: operation=rp_Init_rp_Init_Mdl_TurnHazard.Init
            OA_rp_Init_rp_Init_Mdl_wAirbag_Init: operation=rp_Init_rp_Init_Mdl_wAirbag.Init
            OA_rp_Init_rp_Init_Mdl_wFuelLidOpen_Init: operation=rp_Init_rp_Init_Mdl_wFuelLidOpen.Init
            OA_rp_Init_rp_Init_SlowGaugeAdapter_Init: operation=rp_Init_rp_Init_SlowGaugeAdapter.Init
            OA_rp_Init_rp_Init_View_Speed_Init: operation=rp_Init_rp_Init_View_Speed.Init
            OA_rp_Init_rp_Init_WarnMsg_Core_TmrSupport_Init: operation=rp_Init_rp_Init_WarnMsg_Core_TmrSupport.Init
        Ctrl_WSS_Impl_OnCommand
        Ctrl_WSS_SWCEarlyWakeUpHandle
        Ctrl_WSS_SWCSleepStatus
  30 x constant specification:
    Ctrl_WSSWSSAccStateValue0: value-spec=Ctrl_WSSWSSAccStateValue0:0
    Ctrl_WSSWSSBaStateValue0: value-spec=Ctrl_WSSWSSBaStateValue0:0
    Ctrl_WSSWSSBaOfStateValue0: value-spec=Ctrl_WSSWSSBaOfStateValue0:0
    Ctrl_WSSIgnitioBuznstateValue0: value-spec=Ctrl_WSSIgnitioBuznstateValue0:0
    Ctrl_WSSIgnitionSubstateValue0: value-spec=Ctrl_WSSIgnitionSubstateValue0:0
    Ctrl_WSSWSSIGPCANStateValue0: value-spec=Ctrl_WSSWSSIGPCANStateValue0:0
    Ctrl_WSSWSSIGPStateValue0: value-spec=Ctrl_WSSWSSIGPStateValue0:0
    Ctrl_WSSWSSCurrentClusterModeValue0: value-spec=Ctrl_WSSWSSCurrentClusterModeValue0:0
    Ctrl_WSSHMI_ReadyStatusValue0: value-spec=Ctrl_WSSHMI_ReadyStatusValue0:0
    Ctrl_WSSWSSCurrentClusterInitModeValue0: value-spec=0
    Ctrl_WSSSleep_StatusValue0: value-spec=Ctrl_WSSSleep_StatusValue0:0
    Ctrl_WSSTFTDisplayOnValue0: value-spec=Ctrl_WSSTFTDisplayOnValue0:0
    Ctrl_WSSTFTDisplayOnExTurnValue0: value-spec=Ctrl_WSSTFTDisplayOnExTurnValue0:0
    Ctrl_WSSWSSCurrentVehicleStateValue0: value-spec=Ctrl_WSSWSSCurrentVehicleStateValue0:0
    Ctrl_WSSPhasedRead_Status_phase1readcompletedValue0: value-spec=Ctrl_WSSPhasedRead_Status_phase1readcompletedValue0:false
    Ctrl_WSSPhasedRead_Status_phase2readcompletedValue0: value-spec=Ctrl_WSSPhasedRead_Status_phase2readcompletedValue0:false
    Ctrl_WSSTTIndexValue0: value-spec=Ctrl_WSSTTIndexValue0:0
    Ctrl_WSSTTStatusValue0: value-spec=Ctrl_WSSTTStatusValue0:0
    Ctrl_WSSTelltaleOpArrayValue0: value-spec=Ctrl_WSSTelltaleOpArrayValue0:[Ctrl_WSSTelltaleOpArray0Value:0, Ctrl_WSSTelltaleOpArray1Value:0, Ctrl_WSSTelltaleOpArray2Value:0, Ctrl_WSSTelltaleOpArray3Value:0, Ctrl_WSSTelltaleOpArray4Value:0, Ctrl_WSSTelltaleOpArray5Value:0, Ctrl_WSSTelltaleOpArray6Value:0, Ctrl_WSSTelltaleOpArray7Value:0, Ctrl_WSSTelltaleOpArray8Value:0, Ctrl_WSSTelltaleOpArray9Value:0, Ctrl_WSSTelltaleOpArray10Value:0, Ctrl_WSSTelltaleOpArray11Value:0, Ctrl_WSSTelltaleOpArray12Value:0, Ctrl_WSSTelltaleOpArray13Value:0, Ctrl_WSSTelltaleOpArray14Value:0, Ctrl_WSSTelltaleOpArray15Value:0, Ctrl_WSSTelltaleOpArray16Value:0, Ctrl_WSSTelltaleOpArray17Value:0, Ctrl_WSSTelltaleOpArray18Value:0, Ctrl_WSSTelltaleOpArray19Value:0, Ctrl_WSSTelltaleOpArray20Value:0, Ctrl_WSSTelltaleOpArray21Value:0, Ctrl_WSSTelltaleOpArray22Value:0, Ctrl_WSSTelltaleOpArray23Value:0, Ctrl_WSSTelltaleOpArray24Value:0, Ctrl_WSSTelltaleOpArray25Value:0, Ctrl_WSSTelltaleOpArray26Value:0, Ctrl_WSSTelltaleOpArray27Value:0, Ctrl_WSSTelltaleOpArray28Value:0, Ctrl_WSSTelltaleOpArray29Value:0, Ctrl_WSSTelltaleOpArray30Value:0, Ctrl_WSSTelltaleOpArray31Value:0, Ctrl_WSSTelltaleOpArray32Value:0, Ctrl_WSSTelltaleOpArray33Value:0, Ctrl_WSSTelltaleOpArray34Value:0, Ctrl_WSSTelltaleOpArray35Value:0, Ctrl_WSSTelltaleOpArray36Value:0, Ctrl_WSSTelltaleOpArray37Value:0, Ctrl_WSSTelltaleOpArray38Value:0, Ctrl_WSSTelltaleOpArray39Value:0, Ctrl_WSSTelltaleOpArray40Value:0, Ctrl_WSSTelltaleOpArray41Value:0, Ctrl_WSSTelltaleOpArray42Value:0, Ctrl_WSSTelltaleOpArray43Value:0, Ctrl_WSSTelltaleOpArray44Value:0, Ctrl_WSSTelltaleOpArray45Value:0, Ctrl_WSSTelltaleOpArray46Value:0, Ctrl_WSSTelltaleOpArray47Value:0, Ctrl_WSSTelltaleOpArray48Value:0, Ctrl_WSSTelltaleOpArray49Value:0, Ctrl_WSSTelltaleOpArray50Value:0, Ctrl_WSSTelltaleOpArray51Value:0, Ctrl_WSSTelltaleOpArray52Value:0, Ctrl_WSSTelltaleOpArray53Value:0, Ctrl_WSSTelltaleOpArray54Value:0, Ctrl_WSSTelltaleOpArray55Value:0, Ctrl_WSSTelltaleOpArray56Value:0, Ctrl_WSSTelltaleOpArray57Value:0, Ctrl_WSSTelltaleOpArray58Value:0, Ctrl_WSSTelltaleOpArray59Value:0, Ctrl_WSSTelltaleOpArray60Value:0, Ctrl_WSSTelltaleOpArray61Value:0, Ctrl_WSSTelltaleOpArray62Value:0, Ctrl_WSSTelltaleOpArray63Value:0, Ctrl_WSSTelltaleOpArray64Value:0, Ctrl_WSSTelltaleOpArray65Value:0, Ctrl_WSSTelltaleOpArray66Value:0, Ctrl_WSSTelltaleOpArray67Value:0, Ctrl_WSSTelltaleOpArray68Value:0, Ctrl_WSSTelltaleOpArray69Value:0, Ctrl_WSSTelltaleOpArray70Value:0, Ctrl_WSSTelltaleOpArray71Value:0, Ctrl_WSSTelltaleOpArray72Value:0, Ctrl_WSSTelltaleOpArray73Value:0, Ctrl_WSSTelltaleOpArray74Value:0, Ctrl_WSSTelltaleOpArray75Value:0, Ctrl_WSSTelltaleOpArray76Value:0, Ctrl_WSSTelltaleOpArray77Value:0, Ctrl_WSSTelltaleOpArray78Value:0, Ctrl_WSSTelltaleOpArray79Value:0, Ctrl_WSSTelltaleOpArray80Value:0, Ctrl_WSSTelltaleOpArray81Value:0, Ctrl_WSSTelltaleOpArray82Value:0, Ctrl_WSSTelltaleOpArray83Value:0, Ctrl_WSSTelltaleOpArray84Value:0, Ctrl_WSSTelltaleOpArray85Value:0, Ctrl_WSSTelltaleOpArray86Value:0, Ctrl_WSSTelltaleOpArray87Value:0, Ctrl_WSSTelltaleOpArray88Value:0, Ctrl_WSSTelltaleOpArray89Value:0, Ctrl_WSSTelltaleOpArray90Value:0, Ctrl_WSSTelltaleOpArray91Value:0]
    Ctrl_WSSTTBlinkStatusArrayValue0: value-spec=Ctrl_WSSTTBlinkStatusArrayValue0:[Ctrl_WSSTTBlinkStatusArray0Value:0, Ctrl_WSSTTBlinkStatusArray1Value:0, Ctrl_WSSTTBlinkStatusArray2Value:0, Ctrl_WSSTTBlinkStatusArray3Value:0, Ctrl_WSSTTBlinkStatusArray4Value:0, Ctrl_WSSTTBlinkStatusArray5Value:0, Ctrl_WSSTTBlinkStatusArray6Value:0, Ctrl_WSSTTBlinkStatusArray7Value:0, Ctrl_WSSTTBlinkStatusArray8Value:0, Ctrl_WSSTTBlinkStatusArray9Value:0, Ctrl_WSSTTBlinkStatusArray10Value:0, Ctrl_WSSTTBlinkStatusArray11Value:0, Ctrl_WSSTTBlinkStatusArray12Value:0, Ctrl_WSSTTBlinkStatusArray13Value:0, Ctrl_WSSTTBlinkStatusArray14Value:0, Ctrl_WSSTTBlinkStatusArray15Value:0]
    Ctrl_WSSTTdummyDataForTypesValue0: value-spec=Ctrl_WSSTTdummyDataForTypesValue0:0
    Ctrl_WSSHMI_OdoTypeValue0: value-spec=Ctrl_WSSHMI_OdoTypeValue0:0
    Ctrl_WSSHMIScreenMode_StatusValue0: value-spec=Ctrl_WSSHMIScreenMode_StatusValue0:0
    Ctrl_WSSHead_Lamp_stValue0: value-spec=Ctrl_WSSHead_Lamp_stValue0:0
    Ctrl_WSSillumDNStatusValue0: value-spec=Ctrl_WSSillumDNStatusValue0:0
    Ctrl_WSSPWMOut_TC_DbcValue0: value-spec=Ctrl_WSSPWMOut_TC_DbcValue0:0
    Ctrl_WSSShiftPositionDisplayValue0: value-spec=Ctrl_WSSShiftPositionDisplayValue0:0
    Ctrl_WSSTail_Light_stValue0: value-spec=Ctrl_WSSTail_Light_stValue0:0
    Ctrl_WSSLeftIndicatorStsValue0: value-spec=Ctrl_WSSLeftIndicatorStsValue0:0
    Ctrl_WSSRightIndicatorStsValue0: value-spec=Ctrl_WSSRightIndicatorStsValue0:0
  swc implementation IMPL_Ctrl_WSS: programming-language=C, behavior=IB_Ctrl_WSS
    code-descriptors:
      code CodeDescriptor
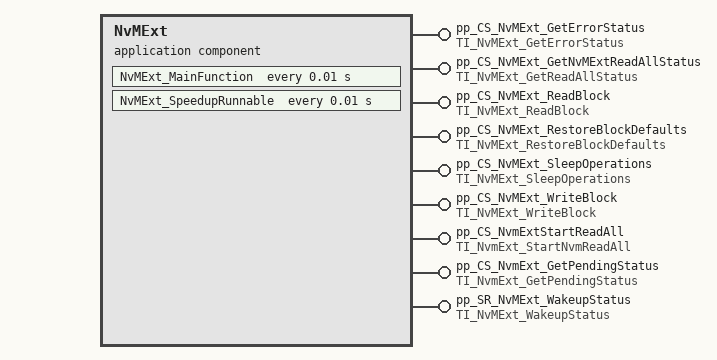
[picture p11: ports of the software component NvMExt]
  application sw component type NvMExt
    9 x provide port:
      pp_CS_NvMExt_GetErrorStatus: server-com-spec{operation=NvMExt_GetErrorStatus, queue-length=1}, provided-interface=TI_NvMExt_GetErrorStatus
      pp_CS_NvMExt_GetNvMExtReadAllStatus: server-com-spec{operation=NvmExt_GetNvMReadAllStatus, queue-length=1}, provided-interface=TI_NvMExt_GetReadAllStatus
      pp_CS_NvMExt_ReadBlock: server-com-spec{operation=NvMExt_ReadBlock, queue-length=1}, provided-interface=TI_NvMExt_ReadBlock
      pp_CS_NvMExt_RestoreBlockDefaults: server-com-spec{operation=NvMExt_RestoreBlockDefaults, queue-length=1}, provided-interface=TI_NvMExt_RestoreBlockDefaults
      pp_CS_NvMExt_SleepOperations: provided-interface=TI_NvMExt_SleepOperations
        provided-com-specs:
          operation=NvMExt_CancelSleep, queue-length=1
          operation=NvMExt_ReadytoSleep, queue-length=1
          operation=NvMExt_RequestSleep, queue-length=1
      pp_CS_NvMExt_WriteBlock: server-com-spec{operation=NvMExt_WriteBlock, queue-length=1}, provided-interface=TI_NvMExt_WriteBlock
      pp_CS_NvmExtStartReadAll: server-com-spec{operation=NvMExt_ReadAll, queue-length=1}, provided-interface=TI_NvmExt_StartNvmReadAll
      pp_CS_NvmExt_GetPendingStatus: server-com-spec{operation=NvMExt_GetPendingStatus, queue-length=1}, provided-interface=TI_NvmExt_GetPendingStatus
      pp_SR_NvMExt_WakeupStatus: nonqueued-sender-com-spec{data-element=WakeupFlag, uses-end-to-end-protection=0, init-value=constant-reference=NvMExtWakeupFlagValue0}, provided-interface=TI_NvMExt_WakeupStatus
    behavior IB_NvMExt
      timing event TENvMExt_MainFunction: start-on-event=NvMExt_MainFunction, period=0.01
      10 x operation invoked event:
        OIE_pp_CS_NvMExt_SleepOperations_NvMExt_CancelSleepTrigByNvMExt_CancelSleep: start-on-event=NvMExt_CancelSleep, operation=pp_CS_NvMExt_SleepOperations.NvMExt_CancelSleep
        OIE_pp_CS_NvMExt_GetErrorStatus_NvMExt_GetErrorStatusTrigByNvMExt_GetErrorStatus: start-on-event=NvMExt_GetErrorStatus, operation=pp_CS_NvMExt_GetErrorStatus.NvMExt_GetErrorStatus
        OIE_pp_CS_NvmExt_GetPendingStatus_NvMExt_GetPendingStatusTrigByNvMExt_GetPendingStatus: start-on-event=NvMExt_GetPendingStatus, operation=pp_CS_NvmExt_GetPendingStatus.NvMExt_GetPendingStatus
        OIE_pp_CS_NvmExtStartReadAll_NvMExt_ReadAllTrigByNvMExt_ReadAll: start-on-event=NvMExt_ReadAll, operation=pp_CS_NvmExtStartReadAll.NvMExt_ReadAll
        OIE_pp_CS_NvMExt_ReadBlock_NvMExt_ReadBlockTrigByNvMExt_ReadBlock: start-on-event=NvMExt_ReadBlock, operation=pp_CS_NvMExt_ReadBlock.NvMExt_ReadBlock
        OIE_pp_CS_NvMExt_SleepOperations_NvMExt_ReadytoSleepTrigByNvMExt_ReadytoSleep: start-on-event=NvMExt_ReadytoSleep, operation=pp_CS_NvMExt_SleepOperations.NvMExt_ReadytoSleep
        OIE_pp_CS_NvMExt_SleepOperations_NvMExt_RequestSleepTrigByNvMExt_RequestSleep: start-on-event=NvMExt_RequestSleep, operation=pp_CS_NvMExt_SleepOperations.NvMExt_RequestSleep
        OIE_pp_CS_NvMExt_RestoreBlockDefaults_NvMExt_RestoreBlockDefaultsTrigByNvMExt_RestoreBlockDefaults: start-on-event=NvMExt_RestoreBlockDefaults, operation=pp_CS_NvMExt_RestoreBlockDefaults.NvMExt_RestoreBlockDefaults
        OIE_pp_CS_NvMExt_WriteBlock_NvMExt_WriteBlockTrigByNvMExt_WriteBlock: start-on-event=NvMExt_WriteBlock, operation=pp_CS_NvMExt_WriteBlock.NvMExt_WriteBlock
        OIE_pp_CS_NvMExt_GetNvMExtReadAllStatus_NvmExt_GetNvMReadAllStatusTrigByNvmExt_GetNvMReadAllStatus: start-on-event=NvmExt_GetNvMReadAllStatus, operation=pp_CS_NvMExt_GetNvMExtReadAllStatus.NvmExt_GetNvMReadAllStatus
      timing event TENvMExt_SpeedupRunnable: start-on-event=NvMExt_SpeedupRunnable, period=0.01
      port-api-options:
        enable-take-address=false, indirect-api=false, port=pp_CS_NvMExt_GetErrorStatus
        enable-take-address=false, indirect-api=false, port=pp_CS_NvMExt_GetNvMExtReadAllStatus
        enable-take-address=false, indirect-api=false, port=pp_CS_NvMExt_ReadBlock
        enable-take-address=false, indirect-api=false, port=pp_CS_NvMExt_RestoreBlockDefaults
        enable-take-address=false, indirect-api=false, port=pp_CS_NvMExt_SleepOperations
        enable-take-address=false, indirect-api=false, port=pp_CS_NvMExt_WriteBlock
        enable-take-address=false, indirect-api=false, port=pp_CS_NvmExtStartReadAll
        enable-take-address=false, indirect-api=false, port=pp_CS_NvmExt_GetPendingStatus
        enable-take-address=false, indirect-api=false, port=pp_SR_NvMExt_WakeupStatus
      12 x runnable, all with can-be-invoked-concurrently=true:
        NvMExt_MainFunction
          data-send-points:
            access DWA_pp_SR_NvMExt_WakeupStatus_WakeupFlag: accessed-variable=pp_SR_NvMExt_WakeupStatus.WakeupFlag
        NvMExt_CancelSleep
        NvMExt_GetErrorStatus
          data-send-points:
            access DWA_pp_SR_NvMExt_WakeupStatus_WakeupFlag: accessed-variable=pp_SR_NvMExt_WakeupStatus.WakeupFlag
        NvMExt_GetPendingStatus
        NvMExt_ReadAll
        NvMExt_ReadBlock
          data-send-points:
            access DWA_pp_SR_NvMExt_WakeupStatus_WakeupFlag: accessed-variable=pp_SR_NvMExt_WakeupStatus.WakeupFlag
        NvMExt_ReadytoSleep
        NvMExt_RequestSleep
        NvMExt_RestoreBlockDefaults
          data-send-points:
            access DWA_pp_SR_NvMExt_WakeupStatus_WakeupFlag: accessed-variable=pp_SR_NvMExt_WakeupStatus.WakeupFlag
        NvMExt_WriteBlock
          data-send-points:
            access DWA_pp_SR_NvMExt_WakeupStatus_WakeupFlag: accessed-variable=pp_SR_NvMExt_WakeupStatus.WakeupFlag
        NvmExt_GetNvMReadAllStatus
        NvMExt_SpeedupRunnable
  constant specification NvMExtWakeupFlagValue0: value-spec=NvMExtWakeupFlagValue0:false
  swc implementation IMPL_NvMExt: programming-language=C, behavior=IB_NvMExt
    code-descriptors:
      code CodeDescriptor
  application sw component type TmExt
    5 x provide port:
      pp_CS_TmExt_Timer_GetElapsedTime: server-com-spec{operation=Timer_GetElapsedTime, queue-length=1}, provided-interface=TI_If_TmExt_Timer_GetElapsedTime
      pp_CS_TmExt_Timer_IsElapsed: server-com-spec{operation=Timer_IsElapsed, queue-length=1}, provided-interface=TI_If_TmExt_Timer_IsElapsed
      pp_CS_TmExt_Timer_IsStarted: server-com-spec{operation=Timer_IsStarted, queue-length=1}, provided-interface=TI_If_TmExt_Timer_IsStarted
      pp_CS_TmExt_Timer_Start: server-com-spec{operation=Timer_Start, queue-length=1}, provided-interface=TI_If_TmExt_Timer_Start
      pp_CS_TmExt_Timer_Stop: server-com-spec{operation=Timer_Stop, queue-length=1}, provided-interface=TI_If_TmExt_Timer_Stop
    behavior IB_TmExt
      timing event TETmExt_MainFunction: start-on-event=TmExt_MainFunction, period=0.01
      5 x operation invoked event:
        OIE_pp_CS_TmExt_Timer_GetElapsedTime_TmExt_Timer_GetElapsedTimeTrigByTimer_GetElapsedTime: start-on-event=TmExt_Timer_GetElapsedTime, operation=pp_CS_TmExt_Timer_GetElapsedTime.Timer_GetElapsedTime
        OIE_pp_CS_TmExt_Timer_IsElapsed_TmExt_Timer_IsElapsedTrigByTimer_IsElapsed: start-on-event=TmExt_Timer_IsElapsed, operation=pp_CS_TmExt_Timer_IsElapsed.Timer_IsElapsed
        OIE_pp_CS_TmExt_Timer_IsStarted_TmExt_Timer_IsStartedTrigByTimer_IsStarted: start-on-event=TmExt_Timer_IsStarted, operation=pp_CS_TmExt_Timer_IsStarted.Timer_IsStarted
        OIE_pp_CS_TmExt_Timer_Start_TmExt_Timer_StartTrigByTimer_Start: start-on-event=TmExt_Timer_Start, operation=pp_CS_TmExt_Timer_Start.Timer_Start
        OIE_pp_CS_TmExt_Timer_Stop_TmExt_Timer_StopTrigByTimer_Stop: start-on-event=TmExt_Timer_Stop, operation=pp_CS_TmExt_Timer_Stop.Timer_Stop
      port-api-options:
        enable-take-address=false, indirect-api=false, port=pp_CS_TmExt_Timer_GetElapsedTime
        enable-take-address=false, indirect-api=false, port=pp_CS_TmExt_Timer_IsElapsed
        enable-take-address=false, indirect-api=false, port=pp_CS_TmExt_Timer_IsStarted
        enable-take-address=false, indirect-api=false, port=pp_CS_TmExt_Timer_Start
        enable-take-address=false, indirect-api=false, port=pp_CS_TmExt_Timer_Stop
      6 x runnable, all with can-be-invoked-concurrently=true:
        TmExt_MainFunction
        TmExt_Timer_GetElapsedTime
        TmExt_Timer_IsElapsed
        TmExt_Timer_IsStarted
        TmExt_Timer_Start
        TmExt_Timer_Stop
  swc implementation IMPL_TmExt: programming-language=C, behavior=IB_TmExt
    code-descriptors:
      code CodeDescriptor
